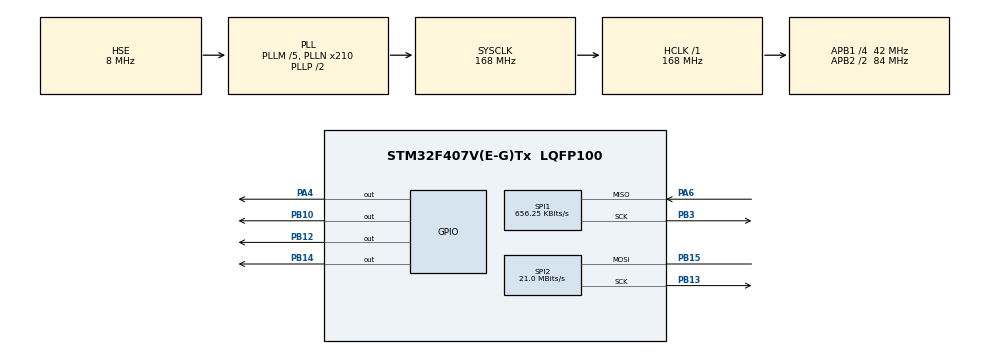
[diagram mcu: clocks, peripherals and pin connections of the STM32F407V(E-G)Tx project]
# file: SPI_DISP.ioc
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Mcu.Family=STM32F4
Mcu.Name=STM32F407V(E-G)Tx
Mcu.Package=LQFP100
NVIC.PriorityGroup=NVIC_PRIORITYGROUP_4
PA4.Signal=GPIO_Output
PA6.Mode=RX_Only_Simplex_Unidirect_Master
PA6.Signal=SPI1_MISO
PB10.Signal=GPIO_Output
PB12.Signal=GPIO_Output
PB13.Mode=Simplex_Bidirectional_Master
PB13.Signal=SPI2_SCK
PB14.Signal=GPIO_Output
PB15.Mode=Simplex_Bidirectional_Master
PB15.Signal=SPI2_MOSI
PB3.Mode=RX_Only_Simplex_Unidirect_Master
PB3.Signal=SPI1_SCK
PH0-OSC_IN.Mode=HSE-External-Oscillator
PH0-OSC_IN.Signal=RCC_OSC_IN
PH1-OSC_OUT.Mode=HSE-External-Oscillator
PH1-OSC_OUT.Signal=RCC_OSC_OUT
ProjectManager.TargetToolchain=MDK-ARM V5
RCC.48MHZClocksFreq_Value=84000000
RCC.AHBFreq_Value=168000000
RCC.APB1CLKDivider=RCC_HCLK_DIV4
RCC.APB1Freq_Value=42000000
RCC.APB1TimFreq_Value=84000000
RCC.APB2CLKDivider=RCC_HCLK_DIV2
RCC.APB2Freq_Value=84000000
RCC.APB2TimFreq_Value=168000000
RCC.CortexFreq_Value=168000000
RCC.HCLKFreq_Value=168000000
RCC.HSE_VALUE=8000000
RCC.HSI_VALUE=16000000
RCC.LSE_VALUE=32768
RCC.PLLM=5
RCC.PLLN=210
RCC.PLLSourceVirtual=RCC_PLLSOURCE_HSE
RCC.SYSCLKFreq_VALUE=168000000
RCC.SYSCLKSource=RCC_SYSCLKSOURCE_PLLCLK
RCC.VCOOutputFreq_Value=336000000
SPI1.BaudRatePrescaler=SPI_BAUDRATEPRESCALER_128
SPI1.CLKPhase=SPI_PHASE_2EDGE
SPI1.CalculateBaudRate=656.25 KBits/s
SPI1.DataSize=SPI_DATASIZE_16BIT
SPI1.Direction=SPI_DIRECTION_2LINES_RXONLY
SPI1.Mode=SPI_MODE_MASTER
SPI2.CalculateBaudRate=21.0 MBits/s
SPI2.Direction=SPI_DIRECTION_1LINE
SPI2.Mode=SPI_MODE_MASTER
board=custom

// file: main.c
/**
  ******************************************************************************
  * File Name          : main.c
  * Description        : Main program body
  ******************************************************************************
  *
  * COPYRIGHT(c) 2016 STMicroelectronics
  *
  * Redistribution and use in source and binary forms, with or without modification,
  * are permitted provided that the following conditions are met:
  *   1. Redistributions of source code must retain the above copyright notice,
  *      this list of conditions and the following disclaimer.
  *   2. Redistributions in binary form must reproduce the above copyright notice,
  *      this list of conditions and the following disclaimer in the documentation
  *      and/or other materials provided with the distribution.
  *   3. Neither the name of STMicroelectronics nor the names of its contributors
  *      may be used to endorse or promote products derived from this software
  *      without specific prior written permission.
  *
  * THIS SOFTWARE IS PROVIDED BY THE COPYRIGHT HOLDERS AND CONTRIBUTORS "AS IS"
  * AND ANY EXPRESS OR IMPLIED WARRANTIES, INCLUDING, BUT NOT LIMITED TO, THE
  * IMPLIED WARRANTIES OF MERCHANTABILITY AND FITNESS FOR A PARTICULAR PURPOSE ARE
  * DISCLAIMED. IN NO EVENT SHALL THE COPYRIGHT HOLDER OR CONTRIBUTORS BE LIABLE
  * FOR ANY DIRECT, INDIRECT, INCIDENTAL, SPECIAL, EXEMPLARY, OR CONSEQUENTIAL
  * DAMAGES (INCLUDING, BUT NOT LIMITED TO, PROCUREMENT OF SUBSTITUTE GOODS OR
  * SERVICES; LOSS OF USE, DATA, OR PROFITS; OR BUSINESS INTERRUPTION) HOWEVER
  * CAUSED AND ON ANY THEORY OF LIABILITY, WHETHER IN CONTRACT, STRICT LIABILITY,
  * OR TORT (INCLUDING NEGLIGENCE OR OTHERWISE) ARISING IN ANY WAY OUT OF THE USE
  * OF THIS SOFTWARE, EVEN IF ADVISED OF THE POSSIBILITY OF SUCH DAMAGE.
  *
  ******************************************************************************
  */

int  pixel=0;

#include "stm32f4xx_hal.h"

/* USER CODE BEGIN Includes */
//===============================================================================//
//----------------------AUTHOR: ИЛЬКОВЕЦ БОРИС / ILKAVETS BARYS-----------------//
// This is Open source software. You can place this code on site, but don't
// forget a link to my YouTube-channel: http://www.youtube.com/c/ElectroHobby1
// Это программное обеспечение распространяется свободно. Вы можете размещать
// его на сайте, но не забудьте указать ссылку на мой YouTube-канал
// "ElectroHobby" http://www.youtube.com/c/ElectroHobby1
//===============================================================================//
#include "main.h"
#include "func.h"
/* USER CODE END Includes */

SPI_HandleTypeDef hspi1;
SPI_HandleTypeDef hspi2;
DMA_HandleTypeDef hdma_spi2_tx;
DMA_HandleTypeDef hdma_spi2_rx;

/* USER CODE BEGIN PV */
#define MAX6675_CS1   HAL_GPIO_WritePin(GPIOA, GPIO_PIN_4,GPIO_PIN_SET);
#define MAX6675_CS0   HAL_GPIO_WritePin(GPIOA, GPIO_PIN_4,GPIO_PIN_RESET);

void Error_Handler(void)
{
  /* USER CODE BEGIN Error_Handler_Debug */
  /* User can add his own implementation to report the HAL error return state */
  __disable_irq();
  while (1)
  {
  }
  /* USER CODE END Error_Handler_Debug */
}

void int2char(int num, unsigned char str[])
{
char lstr[30];
int cnt = 0;
int div = 10;
int j = 0;

while( num >= div)
{
	lstr[cnt] = num % div + 0x30;
	num /= 10;
	cnt++;
}
	lstr[cnt] = num + 0x30;
for(j= cnt ; j >=0;j--)
{
	str[cnt-j] = lstr[j];
}

}

const int test_img_128x128[] = {

0xffff, 0xffff, 0xffff, 0xffff, 0xffff, 0xffff, 0xffff, 0xffff, 0xffff, 0xffff, 0xffff, 0xffff, 0xffff, 0xffff, 0xffff, 0xffff,
	0xffff, 0xffff, 0xffff, 0xffff, 0xffff, 0xffff, 0xffff, 0xffff, 0xffff, 0xffff, 0xffff, 0xffff, 0xffff, 0xffff, 0xffff, 0xffff,
	0xffff, 0xffff, 0xffff, 0xffff, 0xffff, 0xffff, 0xffff, 0xffff, 0xffff, 0xffff, 0xffff, 0xffff, 0xffff, 0xffff, 0xffff, 0xffff,
	0xffff, 0xffff, 0xffff, 0xffff, 0xffff, 0xffff, 0xffff, 0xffff, 0xffff, 0xffff, 0xffff, 0xffff, 0xffff, 0xffff, 0xffff, 0xffff,
	0xffff, 0xffff, 0xffff, 0xffff, 0xffff, 0xffff, 0x4a8a, 0x10c3, 0x10c3, 0x10c3, 0x10c3, 0x10c3, 0x10c3, 0x10c3, 0x10c3, 0x10c3,
	0x10c3, 0x10c3, 0x10c3, 0x10c3, 0x10c3, 0x10c3, 0x10c3, 0x10c3, 0x10c3, 0x1924, 0xffff, 0xffff, 0xffff, 0xffff, 0xffff, 0xffff,
	0xffff, 0xffff, 0xffff, 0xffff, 0xffff, 0xffff, 0xffff, 0xffff, 0xffff, 0xffff, 0xffff, 0xffff, 0xffff, 0xffff, 0xffff, 0xffff,
	0xffff, 0xffff, 0xffff, 0xffff, 0xffff, 0xffff, 0xffff, 0xffff, 0xffff, 0xffff, 0xffff, 0xffff, 0xffff, 0xffff, 0xffff, 0xffff,
	0xffff, 0xffff, 0xffff, 0xffff, 0xffff, 0xffff, 0xffff, 0xffff, 0xffff, 0xffff, 0xffff, 0xffff, 0xffff, 0xffff, 0xffff, 0xffff,
	0xffff, 0xffff, 0xffff, 0xffff, 0xffff, 0xffff, 0xffff, 0xffff, 0xffff, 0xffff, 0xffff, 0xffff, 0xffff, 0xffff, 0xffff, 0xffff,
	0xffff, 0xffff, 0xffff, 0xffff, 0xffff, 0xffff, 0xffff, 0xffff, 0xffff, 0xffff, 0xffff, 0xffff, 0xffff, 0xffff, 0xffff, 0xffff,
	0xffff, 0xffff, 0xffff, 0xffff, 0xffff, 0xffff, 0xffff, 0xffff, 0xffff, 0xffff, 0xffff, 0xffff, 0xffff, 0xffff, 0xffff, 0xffff,
	0xffff, 0xffff, 0xffff, 0xffff, 0xffff, 0xffff, 0xffff, 0xffff, 0xffff, 0xffff, 0xffff, 0xffff, 0xffff, 0xffff, 0xffff, 0xffff,
	0xffff, 0xffff, 0xffff, 0xffff, 0xffff, 0xffff, 0xffff, 0xffff, 0xffff, 0xffff, 0xffff, 0xffff, 0xffff, 0xffff, 0xffff, 0x10c3,
	0x10a2, 0x10a2, 0x10c3, 0x10c3, 0x10c3, 0x10c3, 0x10c3, 0x10c3, 0x10c3, 0x10c3, 0x10c3, 0x10c3, 0x10c3, 0x10c3, 0x10c3, 0x10c3,
	0x10c3, 0x10c3, 0x10c3, 0x10c3, 0x10c3, 0x10c3, 0x10c3, 0x10c3, 0x10c3, 0x10c3, 0x10c3, 0x10c3, 0x10c3, 0x10c3, 0x10a2, 0x10a2,
	0x10a3, 0xffff, 0xffff, 0xffff, 0xffff, 0xffff, 0xffff, 0xffff, 0xffff, 0xffff, 0xffff, 0xffff, 0xffff, 0xffff, 0xffff, 0xffff,
	0xffff, 0xffff, 0xffff, 0xffff, 0xffff, 0xffff, 0xffff, 0xffff, 0xffff, 0xffff, 0xffff, 0xffff, 0xffff, 0xffff, 0xffff, 0xffff,
	0xffff, 0xffff, 0xffff, 0xffff, 0xffff, 0xffff, 0xffff, 0xffff, 0xffff, 0xffff, 0xffff, 0xffff, 0xffff, 0xffff, 0xffff, 0xffff,
	0xffff, 0xffff, 0xffff, 0xffff, 0xffff, 0xffff, 0xffff, 0xffff, 0xffff, 0xffff, 0xffff, 0xffff, 0xffff, 0xffff, 0xffff, 0xffff,
	0xffff, 0xffff, 0xffff, 0xffff, 0xffff, 0xffff, 0xffff, 0xffff, 0xffff, 0xffff, 0xffff, 0xffff, 0xffff, 0xffff, 0xffff, 0xffff,
	0xffff, 0xffff, 0xffff, 0xffff, 0xffff, 0xffff, 0xffff, 0xffff, 0xffff, 0xffff, 0xffff, 0xffff, 0xffff, 0xffff, 0xffff, 0xffff,
	0xffff, 0xffff, 0xffff, 0xffff, 0xffff, 0xffff, 0xffff, 0xffff, 0xffff, 0xffff, 0xffff, 0xffff, 0xffff, 0xffff, 0xffff, 0xffff,
	0xffff, 0xffff, 0xffff, 0xffff, 0xffff, 0xffff, 0xffff, 0xffff, 0xffff, 0xffff, 0x10c3, 0x10c3, 0x10c3, 0x10c3, 0x10c3, 0x10c3,
	0x10c3, 0x10c3, 0x10c3, 0x10c3, 0x10c3, 0x10a3, 0x10a3, 0x10a2, 0x94d3, 0xffff, 0xffff, 0xffff, 0xffff, 0xffff, 0xffff, 0xffff,
	0xffff, 0xffff, 0xffff, 0xffff, 0xffff, 0xffff, 0xffff, 0xc638, 0x10c3, 0x10a3, 0x10c3, 0x10a3, 0x10c3, 0x10c3, 0x10c3, 0x10c3,
	0x10c3, 0x10c3, 0x10c3, 0x10c3, 0x10c3, 0x10c3, 0xffff, 0xffff, 0xffff, 0xffff, 0xffff, 0xffff, 0xffff, 0xffff, 0xffff, 0xffff,
	0xffff, 0xffff, 0xffff, 0xffff, 0xffff, 0xffff, 0xffff, 0xffff, 0xffff, 0xffff, 0xffff, 0xffff, 0xffff, 0xffff, 0xffff, 0xffff,
	0xffff, 0xffff, 0xffff, 0xffff, 0xffff, 0xffff, 0xffff, 0xffff, 0xffff, 0xffff, 0xffff, 0xffff, 0xffff, 0xffff, 0xffff, 0xffff,
	0xffff, 0xffff, 0xffff, 0xffff, 0xffff, 0xffff, 0xffff, 0xffff, 0xffff, 0xffff, 0xffff, 0xffff, 0xffff, 0xffff, 0xffff, 0xffff,
	0xffff, 0xffff, 0xffff, 0xffff, 0xffff, 0xffff, 0xffff, 0xffff, 0xffff, 0xffff, 0xffff, 0xffff, 0xffff, 0xffff, 0xffff, 0xffff,
	0xffff, 0xffff, 0xffff, 0xffff, 0xffff, 0xffff, 0xffff, 0xffff, 0xffff, 0xffff, 0xffff, 0xffff, 0xffff, 0xffff, 0xffff, 0xffff,
	0xffff, 0xffff, 0xffff, 0xffff, 0xffff, 0xffff, 0xffff, 0xffff, 0xffff, 0xffff, 0xffff, 0xffff, 0xffff, 0xffff, 0xffff, 0xffff,
	0xffff, 0xffff, 0xffff, 0xffff, 0xffff, 0xffff, 0x10a3, 0x10a2, 0x10c3, 0x10c3, 0x10c3, 0x10c3, 0x10c3, 0x10c3, 0x10c3, 0x10a2,
	0xffff, 0xffff, 0xffff, 0xffff, 0xffff, 0xffff, 0xffff, 0xffff, 0xffff, 0xffff, 0xffff, 0xffff, 0xffff, 0xffff, 0xffff, 0xffff,
	0xffff, 0xffff, 0xffff, 0xffff, 0xffff, 0xffff, 0xffff, 0xffff, 0xffff, 0xffff, 0xffff, 0xffff, 0xffff, 0xffff, 0xffff, 0xffff,
	0x10c3, 0x10c3, 0x10c3, 0x10c3, 0x10c3, 0x10c3, 0x10c3, 0x10c3, 0x10a3, 0x10a3, 0xffff, 0xffff, 0xffff, 0xffff, 0xffff, 0xffff,
	0xffff, 0xffff, 0xffff, 0xffff, 0xffff, 0xffff, 0xffff, 0xffff, 0xffff, 0xffff, 0xffff, 0xffff, 0xffff, 0xffff, 0xffff, 0xffff,
	0xffff, 0xffff, 0xffff, 0xffff, 0xffff, 0xffff, 0xffff, 0xffff, 0xffff, 0xffff, 0xffff, 0xffff, 0xffff, 0xffff, 0xffff, 0xffff,
	0xffff, 0xffff, 0xffff, 0xffff, 0xffff, 0xffff, 0xffff, 0xffff, 0xffff, 0xffff, 0xffff, 0xffff, 0xffff, 0xffff, 0xffff, 0xffff,
	0xffff, 0xffff, 0xffff, 0xffff, 0xffff, 0xffff, 0xffff, 0xffff, 0xffff, 0xffff, 0xffff, 0xffff, 0xffff, 0xffff, 0xffff, 0xffff,
	0xffff, 0xffff, 0xffff, 0xffff, 0xffff, 0xffff, 0xffff, 0xffff, 0xffff, 0xffff, 0xffff, 0xffff, 0xffff, 0xffff, 0xffff, 0xffff,
	0xffff, 0xffff, 0xffff, 0xffff, 0xffff, 0xffff, 0xffff, 0xffff, 0xffff, 0xffff, 0xffff, 0xffff, 0xffff, 0xffff, 0xffff, 0xffff,
	0xffff, 0xffff, 0x6b6d, 0x10c3, 0x10c3, 0x10c3, 0x10c3, 0x10c3, 0x10c3, 0x10c3, 0x10a2, 0xffff, 0xffff, 0xffff, 0xffff, 0xffff,
	0xffff, 0xffff, 0xffff, 0xffff, 0xffff, 0xffff, 0xffff, 0xffff, 0xffff, 0xffff, 0xffff, 0xc73a, 0x45cf, 0x0d09, 0x0d0a, 0x0d0a,
	0x0d09, 0x0d0a, 0x0d0a, 0x4dcf, 0xc75a, 0xffff, 0xffff, 0xffff, 0xffff, 0xffff, 0xffff, 0xffff, 0xffff, 0xffff, 0xffff, 0xffff,
	0xffff, 0xffff, 0xffff, 0xffff, 0xffff, 0x10a3, 0x10c3, 0x10c3, 0x10c3, 0x10c3, 0x10c3, 0x10c3, 0x10a3, 0x2124, 0xffff, 0xffff,
	0xffff, 0xffff, 0xffff, 0xffff, 0xffff, 0xffff, 0xffff, 0xffff, 0xffff, 0xffff, 0xffff, 0xffff, 0xffff, 0xffff, 0xffff, 0xffff,
	0xffff, 0xffff, 0xffff, 0xffff, 0xffff, 0xffff, 0xffff, 0xffff, 0xffff, 0xffff, 0xffff, 0xffff, 0xffff, 0xffff, 0xffff, 0xffff,
	0xffff, 0xffff, 0xffff, 0xffff, 0xffff, 0xffff, 0xffff, 0xffff, 0xffff, 0xffff, 0xffff, 0xffff, 0xffff, 0xffff, 0xffff, 0xffff,
	0xffff, 0xffff, 0xffff, 0xffff, 0xffff, 0xffff, 0xffff, 0xffff, 0xffff, 0xffff, 0xffff, 0xffff, 0xffff, 0xffff, 0xffff, 0xffff,
	0xffff, 0xffff, 0xffff, 0xffff, 0xffff, 0xffff, 0xffff, 0xffff, 0xffff, 0xffff, 0xffff, 0xffff, 0xffff, 0xffff, 0xffff, 0xffff,
	0xffff, 0xffff, 0xffff, 0xffff, 0xffff, 0xffff, 0xffff, 0xffff, 0xffff, 0xffff, 0xffff, 0xffff, 0xffff, 0xffff, 0xffff, 0x6b6d,
	0x10c3, 0x10c3, 0x10c3, 0x10c3, 0x10c3, 0x10c3, 0x10a3, 0xffff, 0xffff, 0xffff, 0xffff, 0xffff, 0xffff, 0xffff, 0xffff, 0xffff,
	0xffff, 0xf7de, 0x0d0a, 0x0d0a, 0x0d0a, 0x0d0a, 0x0d0a, 0x0d0a, 0x0d0a, 0x0d0a, 0x0d0a, 0x0d0a, 0x0d0a, 0x0d0a, 0x0d0a, 0x0d0a,
	0x0d0a, 0x0d0a, 0x0d0a, 0x0d0a, 0x0d0a, 0x0d0a, 0x0d0a, 0x0d0a, 0x0d0a, 0x0d0a, 0x0d0a, 0x0d0a, 0x0d0a, 0x0d0a, 0xc75a, 0xffff,
	0xffff, 0xffff, 0xffff, 0xffff, 0xffff, 0xffff, 0xffff, 0xffff, 0xffff, 0x10a3, 0x10a2, 0x10c3, 0x10c3, 0x10c3, 0x10c3, 0x10c3,
	0x2124, 0xffff, 0xffff, 0xffff, 0xffff, 0xffff, 0xffff, 0xffff, 0xffff, 0xffff, 0xffff, 0xffff, 0xffff, 0xffff, 0xffff, 0xffff,
	0xffff, 0xffff, 0xffff, 0xffff, 0xffff, 0xffff, 0xffff, 0xffff, 0xffff, 0xffff, 0xffff, 0xffff, 0xffff, 0xffff, 0xffff, 0xffff,
	0xffff, 0xffff, 0xffff, 0xffff, 0xffff, 0xffff, 0xffff, 0xffff, 0xffff, 0xffff, 0xffff, 0xffff, 0xffff, 0xffff, 0xffff, 0xffff,
	0xffff, 0xffff, 0xffff, 0xffff, 0xffff, 0xffff, 0xffff, 0xffff, 0xffff, 0xffff, 0xffff, 0xffff, 0xffff, 0xffff, 0xffff, 0xffff,
	0xffff, 0xffff, 0xffff, 0xffff, 0xffff, 0xffff, 0xffff, 0xffff, 0xffff, 0xffff, 0xffff, 0xffff, 0xffff, 0xffff, 0xffff, 0xffff,
	0xffff, 0xffff, 0xffff, 0xffff, 0xffff, 0xffff, 0xffff, 0xffff, 0xffff, 0xffff, 0xffff, 0xffff, 0xffff, 0x10c3, 0x10c3, 0x10c3,
	0x10c3, 0x10c3, 0x10c3, 0x10a3, 0xffff, 0xffff, 0xffff, 0xffff, 0xffff, 0xffff, 0xffff, 0xffff, 0xffff, 0x050a, 0x050a, 0x0d0a,
	0x0d0a, 0x0d0a, 0x0d0a, 0x0d0a, 0x0d0a, 0x0d0a, 0x0d0a, 0x0d0a, 0x0d0a, 0x0d0a, 0x0d0a, 0x0d2a, 0x050a, 0x0d2a, 0x45cf, 0x45cf,
	0x45cf, 0x45cf, 0x050a, 0x0d0a, 0x0d2a, 0x0d09, 0x0d0a, 0x0d0a, 0x0d0a, 0x0d0a, 0x0d0a, 0x0d0a, 0x0d0a, 0x0d0a, 0x0d0a, 0x0d0a,
	0x0d0a, 0x0d09, 0x0d0a, 0xe7bd, 0xffff, 0xffff, 0xffff, 0xffff, 0xffff, 0xffff, 0xffff, 0xffff, 0x10a2, 0x10c3, 0x10c3, 0x10c3,
	0x10c3, 0x10c3, 0x10a3, 0xffff, 0xffff, 0xffff, 0xffff, 0xffff, 0xffff, 0xffff, 0xffff, 0xffff, 0xffff, 0xffff, 0xffff, 0xffff,
	0xffff, 0xffff, 0xffff, 0xffff, 0xffff, 0xffff, 0xffff, 0xffff, 0xffff, 0xffff, 0xffff, 0xffff, 0xffff, 0xffff, 0xffff, 0xffff,
	0xffff, 0xffff, 0xffff, 0xffff, 0xffff, 0xffff, 0xffff, 0xffff, 0xffff, 0xffff, 0xffff, 0xffff, 0xffff, 0xffff, 0xffff, 0xffff,
	0xffff, 0xffff, 0xffff, 0xffff, 0xffff, 0xffff, 0xffff, 0xffff, 0xffff, 0xffff, 0xffff, 0xffff, 0xffff, 0xffff, 0xffff, 0xffff,
	0xffff, 0xffff, 0xffff, 0xffff, 0xffff, 0xffff, 0xffff, 0xffff, 0xffff, 0xffff, 0xffff, 0xffff, 0xffff, 0xffff, 0xffff, 0xffff,
	0xffff, 0xffff, 0xffff, 0xffff, 0xffff, 0xffff, 0xffff, 0xffff, 0xffff, 0xffff, 0xc638, 0x10c3, 0x10c3, 0x10c3, 0x10c3, 0x10c3,
	0x10a3, 0xffff, 0xffff, 0xffff, 0xffff, 0xffff, 0xffff, 0xffff, 0x6631, 0x0d0a, 0x0d0a, 0x0d0a, 0x0d0a, 0x0d0a, 0x0d0a, 0x0509,
	0x0d09, 0x0d09, 0x4dcf, 0xffff, 0xffff, 0xffff, 0xffff, 0xffff, 0xffff, 0xffff, 0xffff, 0xffff, 0xffff, 0xffff, 0xffff, 0xffff,
	0xffff, 0xffff, 0xffff, 0xffff, 0xffff, 0xffff, 0xffff, 0xffff, 0xffff, 0xffff, 0xffff, 0xffff, 0xffff, 0x6632, 0x0d2a, 0x0d0a,
	0x0d0a, 0x0d0a, 0x0d0a, 0x0d0a, 0x0d0a, 0x0d0a, 0x0509, 0x256c, 0xffff, 0xffff, 0xffff, 0xffff, 0xffff, 0xffff, 0xffff, 0x10a3,
	0x10c3, 0x10c3, 0x10c3, 0x10c3, 0x10c3, 0x4a6a, 0xffff, 0xffff, 0xffff, 0xffff, 0xffff, 0xffff, 0xffff, 0xffff, 0xffff, 0xffff,
	0xffff, 0xffff, 0xffff, 0xffff, 0xffff, 0xffff, 0xffff, 0xffff, 0xffff, 0xffff, 0xffff, 0xffff, 0xffff, 0xffff, 0xffff, 0xffff,
	0xffff, 0xffff, 0xffff, 0xffff, 0xffff, 0xffff, 0xffff, 0xffff, 0xffff, 0xffff, 0xffff, 0xffff, 0xffff, 0xffff, 0xffff, 0xffff,
	0xffff, 0xffff, 0xffff, 0xffff, 0xffff, 0xffff, 0xffff, 0xffff, 0xffff, 0xffff, 0xffff, 0xffff, 0xffff, 0xffff, 0xffff, 0xffff,
	0xffff, 0xffff, 0xffff, 0xffff, 0xffff, 0xffff, 0xffff, 0xffff, 0xffff, 0xffff, 0xffff, 0xffff, 0xffff, 0xffff, 0xffff, 0xffff,
	0xffff, 0xffff, 0xffff, 0xffff, 0xffff, 0xffff, 0xffff, 0xffff, 0x10a3, 0x10c3, 0x10c3, 0x10c3, 0x10c3, 0x10c3, 0xffff, 0xffff,
	0xffff, 0xffff, 0xffff, 0xffff, 0xffff, 0x0d0a, 0x0d09, 0x0d0a, 0x0d0a, 0x0d0a, 0x0d0a, 0x0d0a, 0x0d0a, 0xffff, 0xffff, 0xffff,
	0xffff, 0xffff, 0xffff, 0xffff, 0xffff, 0xffff, 0xffff, 0xffff, 0xffff, 0xffff, 0xffff, 0xffff, 0xffff, 0xffff, 0xffff, 0xffff,
	0xffff, 0xffff, 0xffff, 0xffff, 0xffff, 0xffff, 0xffff, 0xffff, 0xffff, 0xffff, 0xffff, 0xffff, 0xffff, 0xffff, 0xffff, 0xffff,
	0xffff, 0xffff, 0xffff, 0x0d0a, 0x0d0a, 0x0d0a, 0x0d0a, 0x0d0a, 0x050a, 0x0509, 0x0d09, 0xffff, 0xffff, 0xffff, 0xffff, 0xffff,
	0xffff, 0xffff, 0x10a3, 0x10c3, 0x10c3, 0x10c3, 0x10a3, 0x10c3, 0xffff, 0xffff, 0xffff, 0xffff, 0xffff, 0xffff, 0xffff, 0xffff,
	0xffff, 0xffff, 0xffff, 0xffff, 0xffff, 0xffff, 0xffff, 0xffff, 0xffff, 0xffff, 0xffff, 0xffff, 0xffff, 0xffff, 0xffff, 0xffff,
	0xffff, 0xffff, 0xffff, 0xffff, 0xffff, 0xffff, 0xffff, 0xffff, 0xffff, 0xffff, 0xffff, 0xffff, 0xffff, 0xffff, 0xffff, 0xffff,
	0xffff, 0xffff, 0xffff, 0xffff, 0xffff, 0xffff, 0xffff, 0xffff, 0xffff, 0xffff, 0xffff, 0xffff, 0xffff, 0xffff, 0xffff, 0xffff,
	0xffff, 0xffff, 0xffff, 0xffff, 0xffff, 0xffff, 0xffff, 0xffff, 0xffff, 0xffff, 0xffff, 0xffff, 0xffff, 0xffff, 0xffff, 0xffff,
	0xffff, 0xffff, 0xffff, 0xffff, 0xffff, 0xffff, 0x10c3, 0x10c3, 0x10c3, 0x10c3, 0x10c3, 0x10a3, 0xffff, 0xffff, 0xffff, 0xffff,
	0xffff, 0xffff, 0x0d09, 0x0d0a, 0x0d0a, 0x0d0a, 0x0d0a, 0x0d0a, 0x0d2a, 0xffff, 0xffff, 0xffff, 0xffff, 0xffff, 0xffff, 0xffff,
	0xffff, 0xffff, 0xffff, 0xffff, 0xffff, 0xffff, 0xffff, 0xffff, 0xffff, 0xffff, 0xffff, 0xffff, 0xffff, 0xffff, 0xffff, 0xffff,
	0xffff, 0xffff, 0xffff, 0xffff, 0xffff, 0xffff, 0xffff, 0xffff, 0xffff, 0xffff, 0xffff, 0xffff, 0xffff, 0xffff, 0xffff, 0xffff,
	0xffff, 0xffff, 0xffff, 0xffff, 0xffff, 0xffff, 0xffff, 0x0d09, 0x0d0a, 0x0d0a, 0x0d0a, 0x0d0a, 0x0d0a, 0x0d2a, 0xffff, 0xffff,
	0xffff, 0xffff, 0xffff, 0xffff, 0x10a3, 0x10a3, 0x10c3, 0x10c3, 0x10c3, 0x10a2, 0xffff, 0xffff, 0xffff, 0xffff, 0xffff, 0xffff,
	0xffff, 0xffff, 0xffff, 0xffff, 0xffff, 0xffff, 0xffff, 0xffff, 0xffff, 0xffff, 0xffff, 0xffff, 0xffff, 0xffff, 0xffff, 0xffff,
	0xffff, 0xffff, 0xffff, 0xffff, 0xffff, 0xffff, 0xffff, 0xffff, 0xffff, 0xffff, 0xffff, 0xffff, 0xffff, 0xffff, 0xffff, 0xffff,
	0xffff, 0xffff, 0xffff, 0xffff, 0xffff, 0xffff, 0xffff, 0xffff, 0xffff, 0xffff, 0xffff, 0xffff, 0xffff, 0xffff, 0xffff, 0xffff,
	0xffff, 0xffff, 0xffff, 0xffff, 0xffff, 0xffff, 0xffff, 0xffff, 0xffff, 0xffff, 0xffff, 0xffff, 0xffff, 0xffff, 0xffff, 0xffff,
	0xffff, 0xffff, 0xffff, 0xffff, 0x10a2, 0x10c3, 0x10c3, 0x10c3, 0x10a3, 0xffff, 0xffff, 0xffff, 0xffff, 0xffff, 0xffff, 0x0d0a,
	0x0d0a, 0x0d0a, 0x0d0a, 0x0d0a, 0x0d2a, 0x45ef, 0xffff, 0xffff, 0xffff, 0xffff, 0xffff, 0xffff, 0xffff, 0xffff, 0xffff, 0xffff,
	0xffff, 0xffff, 0xffff, 0xffff, 0xffff, 0xffff, 0xffff, 0xffff, 0xffff, 0xffff, 0xffff, 0xffff, 0xffff, 0xffff, 0xffff, 0xffff,
	0xffff, 0xffff, 0xffff, 0xffff, 0xffff, 0xffff, 0xffff, 0xffff, 0xffff, 0xffff, 0xffff, 0xffff, 0xffff, 0xffff, 0xffff, 0xffff,
	0xffff, 0xffff, 0xffff, 0xffff, 0xffff, 0xffff, 0xffff, 0xffff, 0xffff, 0xffff, 0xa6f7, 0x0d09, 0x0d0a, 0x0d0a, 0x0d0a, 0x0d0a,
	0x052a, 0xffff, 0xffff, 0xffff, 0xffff, 0xffff, 0xffff, 0x10c3, 0x10c3, 0x10c3, 0x10c3, 0x10a2, 0xffff, 0xffff, 0xffff, 0xffff,
	0xffff, 0xffff, 0xffff, 0xffff, 0xffff, 0xffff, 0xffff, 0xffff, 0xffff, 0xffff, 0xffff, 0xffff, 0xffff, 0xffff, 0xffff, 0xffff,
	0xffff, 0xffff, 0xffff, 0xffff, 0xffff, 0xffff, 0xffff, 0xffff, 0xffff, 0xffff, 0xffff, 0xffff, 0xffff, 0xffff, 0xffff, 0xffff,
	0xffff, 0xffff, 0xffff, 0xffff, 0xffff, 0xffff, 0xffff, 0xffff, 0xffff, 0xffff, 0xffff, 0xffff, 0xffff, 0xffff, 0xffff, 0xffff,
	0xffff, 0xffff, 0xffff, 0xffff, 0xffff, 0xffff, 0xffff, 0xffff, 0xffff, 0xffff, 0xffff, 0xffff, 0xffff, 0xffff, 0xffff, 0xffff,
	0xffff, 0xffff, 0x10a3, 0x10c3, 0x10c3, 0x10c3, 0x10c3, 0xffff, 0xffff, 0xffff, 0xffff, 0xffff, 0xffff, 0x0d2a, 0x0d0a, 0x0d0a,
	0x0d0a, 0x0d0a, 0x256d, 0xffff, 0xffff, 0xffff, 0xffff, 0xffff, 0xffff, 0xffff, 0xffff, 0xffff, 0xffff, 0xffff, 0xffff, 0xffff,
	0xffff, 0xffff, 0xffff, 0xffff, 0xffff, 0xffff, 0xffff, 0xffff, 0xffff, 0xffff, 0xffff, 0xffff, 0xffff, 0xffff, 0xffff, 0xffff,
	0xffff, 0xffff, 0xffff, 0xffff, 0xffff, 0xffff, 0xffff, 0xffff, 0xffff, 0xffff, 0xffff, 0xffff, 0xffff, 0xffff, 0xffff, 0xffff,
	0xffff, 0xffff, 0xffff, 0xffff, 0xffff, 0xffff, 0xffff, 0xffff, 0xffff, 0xffff, 0xffff, 0xffff, 0xffff, 0x8694, 0x0d0a, 0x0d0a,
	0x0d0a, 0x0d0a, 0x0529, 0xffff, 0xffff, 0xffff, 0xffff, 0xffff, 0xffff, 0x10c3, 0x10c3, 0x10c3, 0x10c3, 0x10c3, 0xffff, 0xffff,
	0xffff, 0xffff, 0xffff, 0xffff, 0xffff, 0xffff, 0xffff, 0xffff, 0xffff, 0xffff, 0xffff, 0xffff, 0xffff, 0xffff, 0xffff, 0xffff,
	0xffff, 0xffff, 0xffff, 0xffff, 0xffff, 0xffff, 0xffff, 0xffff, 0xffff, 0xffff, 0xffff, 0xffff, 0xffff, 0xffff, 0xffff, 0xffff,
	0xffff, 0xffff, 0xffff, 0xffff, 0xffff, 0xffff, 0xffff, 0xffff, 0xffff, 0xffff, 0xffff, 0xffff, 0xffff, 0xffff, 0xffff, 0xffff,
	0xffff, 0xffff, 0xffff, 0xffff, 0xffff, 0xffff, 0xffff, 0xffff, 0xffff, 0xffff, 0xffff, 0xffff, 0xffff, 0xffff, 0xffff, 0xffff,
	0xffff, 0x10c3, 0x10c3, 0x10c3, 0x10c3, 0xffff, 0xffff, 0xffff, 0xffff, 0xffff, 0xf7de, 0x0d0a, 0x0d0a, 0x0d0a, 0x0509, 0x0d2a,
	0xffff, 0xffff, 0xffff, 0xffff, 0xffff, 0xffff, 0xffff, 0xffff, 0xffff, 0xffff, 0xffff, 0xffff, 0xffff, 0xffff, 0xffff, 0xffff,
	0xffff, 0xffff, 0xffff, 0xffff, 0xef9e, 0x10a3, 0x10a3, 0x94b3, 0xffff, 0xffff, 0x10a3, 0xffff, 0xffff, 0xffff, 0xffff, 0xffff,
	0xffff, 0x10a2, 0xffff, 0xffff, 0xffff, 0xffff, 0x10c3, 0x10c3, 0x10c3, 0x10c3, 0x10c3, 0xffff, 0xffff, 0xffff, 0xffff, 0xffff,
	0xffff, 0xffff, 0xffff, 0xffff, 0xffff, 0xffff, 0xffff, 0xffff, 0xffff, 0xffff, 0xffff, 0xffff, 0xffff, 0xffff, 0xffff, 0xffff,
	0x0d0a, 0x0d0a, 0x0d0a, 0x0d0a, 0x0d0a, 0x8694, 0xffff, 0xffff, 0xffff, 0xffff, 0xffff, 0x10c3, 0x10c3, 0x10c3, 0x10c3, 0xd6ba,
	0xffff, 0xffff, 0xffff, 0xffff, 0xffff, 0xffff, 0xffff, 0xffff, 0xffff, 0xffff, 0xffff, 0xffff, 0xffff, 0xffff, 0xffff, 0xffff,
	0xffff, 0xffff, 0xffff, 0xffff, 0xffff, 0xffff, 0xffff, 0xffff, 0xffff, 0xffff, 0xffff, 0xffff, 0xffff, 0xffff, 0xffff, 0xffff,
	0xffff, 0xffff, 0xffff, 0xffff, 0xffff, 0xffff, 0xffff, 0xffff, 0xffff, 0xffff, 0xffff, 0xffff, 0xffff, 0xffff, 0xffff, 0xffff,
	0xffff, 0xffff, 0xffff, 0xffff, 0xffff, 0xffff, 0xffff, 0xffff, 0xffff, 0xffff, 0xffff, 0xffff, 0xffff, 0xffff, 0xffff, 0x10c3,
	0x10c3, 0x10c3, 0x10a2, 0x2124, 0xffff, 0xffff, 0xffff, 0xffff, 0xc75a, 0x0d0a, 0x0d0a, 0x0d0a, 0x050a, 0x45cf, 0xffff, 0xffff,
	0xffff, 0xffff, 0xffff, 0xffff, 0xffff, 0xffff, 0xffff, 0xffff, 0xffff, 0xffff, 0xffff, 0xffff, 0xffff, 0xffff, 0xffff, 0xffff,
	0xffff, 0xffff, 0xffff, 0xffff, 0xffff, 0x2124, 0x10c3, 0xffff, 0xffff, 0xffff, 0xffff, 0xffff, 0x10c3, 0xffff, 0xffff, 0xffff,
	0xffff, 0xffff, 0x3a08, 0xffff, 0xffff, 0xffff, 0xffff, 0xf79e, 0xffff, 0xffff, 0xffff, 0xef9e, 0xffff, 0xffff, 0xffff, 0xffff,
	0xffff, 0xffff, 0xffff, 0xffff, 0xffff, 0xffff, 0xffff, 0xffff, 0xffff, 0xffff, 0xffff, 0xffff, 0xffff, 0xffff, 0xffff, 0xffff,
	0xffff, 0xffff, 0xb719, 0x0d2a, 0x0d0a, 0x0d0a, 0x0d0a, 0x45cf, 0xffff, 0xffff, 0xffff, 0xffff, 0x8c51, 0x10a3, 0x10c3, 0x10c3,
	0x10c3, 0xffff, 0xffff, 0xffff, 0xffff, 0xffff, 0xffff, 0xffff, 0xffff, 0xffff, 0xffff, 0xffff, 0xffff, 0xffff, 0xffff, 0xffff,
	0xffff, 0xffff, 0xffff, 0xffff, 0xffff, 0xffff, 0xffff, 0xffff, 0xffff, 0xffff, 0xffff, 0xffff, 0xffff, 0xffff, 0xffff, 0xffff,
	0xffff, 0xffff, 0xffff, 0xffff, 0xffff, 0xffff, 0xffff, 0xffff, 0xffff, 0xffff, 0xffff, 0xffff, 0xffff, 0xffff, 0xffff, 0xffff,
	0xffff, 0xffff, 0xffff, 0xffff, 0xffff, 0xffff, 0xffff, 0xffff, 0xffff, 0xffff, 0xffff, 0xffff, 0xffff, 0x10a2, 0x10c3, 0x10c3,
	0x10c3, 0x10a3, 0xffff, 0xffff, 0xffff, 0xffff, 0xffff, 0x0d0a, 0x0d0a, 0x0d0a, 0x0d0a, 0xffff, 0xffff, 0xffff, 0xffff, 0xffff,
	0xffff, 0xffff, 0xffff, 0xffff, 0xffff, 0xffff, 0xffff, 0xffff, 0xffff, 0xffff, 0xffff, 0xffff, 0xffff, 0xffff, 0xffff, 0xffff,
	0xffff, 0xffff, 0xffff, 0xffff, 0xffff, 0x4a6a, 0x10c3, 0xffff, 0xffff, 0xffff, 0xffff, 0xffff, 0xd69a, 0x10c3, 0xffff, 0xffff,
	0xffff, 0xffff, 0xffff, 0x10a3, 0xffff, 0xffff, 0xffff, 0xffff, 0x10a2, 0xffff, 0xffff, 0xffff, 0xffff, 0xffff, 0xffff, 0xffff,
	0xffff, 0xffff, 0xffff, 0xffff, 0xffff, 0xffff, 0xffff, 0xffff, 0xffff, 0xffff, 0xffff, 0xffff, 0xffff, 0xffff, 0xffff, 0xffff,
	0xffff, 0xffff, 0xffff, 0xffff, 0xffff, 0x0509, 0x0d0a, 0x0d0a, 0x0d0a, 0xd77b, 0xffff, 0xffff, 0xffff, 0xffff, 0x10a2, 0x10c3,
	0x10c3, 0x10c3, 0x10a2, 0xffff, 0xffff, 0xffff, 0xffff, 0xffff, 0xffff, 0xffff, 0xffff, 0xffff, 0xffff, 0xffff, 0xffff, 0xffff,
	0xffff, 0xffff, 0xffff, 0xffff, 0xffff, 0xffff, 0xffff, 0xffff, 0xffff, 0xffff, 0xffff, 0xffff, 0xffff, 0xffff, 0xffff, 0xffff,
	0xffff, 0xffff, 0xffff, 0xffff, 0xffff, 0xffff, 0xffff, 0xffff, 0xffff, 0xffff, 0xffff, 0xffff, 0xffff, 0xffff, 0xffff, 0xffff,
	0xffff, 0xffff, 0xffff, 0xffff, 0xffff, 0xffff, 0xffff, 0xffff, 0xffff, 0xffff, 0xffff, 0xffff, 0x10a2, 0x10c3, 0x10c3, 0x10c3,
	0xffff, 0xffff, 0xffff, 0xffff, 0xffff, 0x0d0a, 0x0d0a, 0x0d0a, 0x0d0a, 0xffff, 0xffff, 0xffff, 0xffff, 0xffff, 0xffff, 0xffff,
	0xffff, 0xffff, 0xffff, 0xffff, 0xffff, 0xffff, 0xffff, 0xffff, 0xffff, 0xffff, 0xffff, 0xffff, 0xffff, 0xffff, 0xffff, 0xffff,
	0xffff, 0xffff, 0xffff, 0xffff, 0xffff, 0x4a6a, 0x10c3, 0xffff, 0xffff, 0xffff, 0x10a3, 0xffff, 0x6b6d, 0x10a3, 0xffff, 0xffff,
	0x10a2, 0x10c3, 0xffff, 0x10a3, 0x10a2, 0xffff, 0xffff, 0xffff, 0xffff, 0x10a2, 0xffff, 0xffff, 0xffff, 0xffff, 0xffff, 0xffff,
	0xffff, 0xffff, 0xffff, 0xffff, 0xffff, 0xffff, 0xffff, 0xffff, 0xffff, 0xffff, 0xffff, 0xffff, 0xffff, 0xffff, 0xffff, 0xffff,
	0xffff, 0xffff, 0xffff, 0xffff, 0xffff, 0xffff, 0xffff, 0x050a, 0x0d0a, 0x0d0a, 0x0d0a, 0xffff, 0xffff, 0xffff, 0xffff, 0xffff,
	0x10a2, 0x10c3, 0x10c3, 0x10c3, 0xffff, 0xffff, 0xffff, 0xffff, 0xffff, 0xffff, 0xffff, 0xffff, 0xffff, 0xffff, 0xffff, 0xffff,
	0xffff, 0xffff, 0xffff, 0xffff, 0xffff, 0xffff, 0xffff, 0xffff, 0xffff, 0xffff, 0xffff, 0xffff, 0xffff, 0xffff, 0xffff, 0xffff,
	0xffff, 0xffff, 0xffff, 0xffff, 0xffff, 0xffff, 0xffff, 0xffff, 0xffff, 0xffff, 0xffff, 0xffff, 0xffff, 0xffff, 0xffff, 0xffff,
	0xffff, 0xffff, 0xffff, 0xffff, 0xffff, 0xffff, 0xffff, 0xffff, 0xffff, 0xffff, 0x4208, 0x10a3, 0x10c3, 0x10c3, 0x10a3, 0xffff,
	0xffff, 0xffff, 0xffff, 0x0d0a, 0x0d0a, 0x0d0a, 0x0d0a, 0xffff, 0xffff, 0xffff, 0xffff, 0xffff, 0xffff, 0xffff, 0xffff, 0xffff,
	0xffff, 0xffff, 0xffff, 0xffff, 0xffff, 0xffff, 0xffff, 0xffff, 0xffff, 0xffff, 0xffff, 0xffff, 0xffff, 0xffff, 0xffff, 0xffff,
	0xffff, 0xffff, 0xffff, 0xffff, 0xffff, 0x4a6a, 0x10c3, 0xffff, 0xffff, 0x10a2, 0xffff, 0xffff, 0xffff, 0x10c3, 0xffff, 0xffff,
	0x10a2, 0xffff, 0xffff, 0xffff, 0x10c3, 0xffff, 0xffff, 0xffff, 0xffff, 0xffff, 0x10a3, 0xffff, 0xffff, 0xffff, 0xffff, 0xffff,
	0xffff, 0xffff, 0xffff, 0xffff, 0xffff, 0xffff, 0xffff, 0xffff, 0xffff, 0xffff, 0xffff, 0xffff, 0xffff, 0xffff, 0xffff, 0xffff,
	0xffff, 0xffff, 0xffff, 0xffff, 0xffff, 0xffff, 0xffff, 0xffff, 0xffff, 0x0d0a, 0x0d0a, 0x0d0a, 0x0d0a, 0xffff, 0xffff, 0xffff,
	0xffff, 0x6b6d, 0x10c3, 0x10c3, 0x10a3, 0x10a3, 0xffff, 0xffff, 0xffff, 0xffff, 0xffff, 0xffff, 0xffff, 0xffff, 0xffff, 0xffff,
	0xffff, 0xffff, 0xffff, 0xffff, 0xffff, 0xffff, 0xffff, 0xffff, 0xffff, 0xffff, 0xffff, 0xffff, 0xffff, 0xffff, 0xffff, 0xffff,
	0xffff, 0xffff, 0xffff, 0xffff, 0xffff, 0xffff, 0xffff, 0xffff, 0xffff, 0xffff, 0xffff, 0xffff, 0xffff, 0xffff, 0xffff, 0xffff,
	0xffff, 0xffff, 0xffff, 0xffff, 0xffff, 0xffff, 0xffff, 0xffff, 0xffff, 0x10a3, 0x10c3, 0x10c3, 0x10c3, 0xffff, 0xffff, 0xffff,
	0xffff, 0x154b, 0x0d0a, 0x0d0a, 0x0d0a, 0x0d0a, 0xffff, 0xffff, 0xffff, 0xffff, 0xffff, 0xffff, 0xffff, 0xffff, 0xffff, 0xffff,
	0xffff, 0xffff, 0xffff, 0xffff, 0xffff, 0xffff, 0xffff, 0xffff, 0xffff, 0xffff, 0xffff, 0xffff, 0xffff, 0xffff, 0xffff, 0xffff,
	0xffff, 0xffff, 0xffff, 0xffff, 0xffff, 0x10a3, 0x10c3, 0xffff, 0xffff, 0x10a3, 0xffff, 0xffff, 0xffff, 0x10c3, 0xffff, 0xd69a,
	0x10a3, 0xffff, 0xffff, 0xffff, 0x10a2, 0xffff, 0xffff, 0xffff, 0xffff, 0xffff, 0x10a3, 0xffff, 0xffff, 0xffff, 0xffff, 0xffff,
	0xffff, 0xffff, 0xffff, 0xffff, 0xffff, 0xffff, 0xffff, 0xffff, 0xffff, 0xffff, 0xffff, 0xffff, 0xffff, 0xffff, 0xffff, 0xffff,
	0xffff, 0xffff, 0xffff, 0xffff, 0xffff, 0xffff, 0xffff, 0xffff, 0xffff, 0xffff, 0x154b, 0x0d0a, 0x0d0a, 0x050a, 0x050a, 0xffff,
	0xffff, 0xffff, 0xffff, 0x10a3, 0x10c3, 0x10c3, 0x10a3, 0xffff, 0xffff, 0xffff, 0xffff, 0xffff, 0xffff, 0xffff, 0xffff, 0xffff,
	0xffff, 0xffff, 0xffff, 0xffff, 0xffff, 0xffff, 0xffff, 0xffff, 0xffff, 0xffff, 0xffff, 0xffff, 0xffff, 0xffff, 0xffff, 0xffff,
	0xffff, 0xffff, 0xffff, 0xffff, 0xffff, 0xffff, 0xffff, 0xffff, 0xffff, 0xffff, 0xffff, 0xffff, 0xffff, 0xffff, 0xffff, 0xffff,
	0xffff, 0xffff, 0xffff, 0xffff, 0xffff, 0xffff, 0xffff, 0xffff, 0x10c3, 0x10c3, 0x10c3, 0x10c3, 0xffff, 0xffff, 0xffff, 0xffff,
	0x052a, 0x0d0a, 0x0d0a, 0x0d0a, 0xffff, 0xffff, 0xffff, 0xffff, 0xffff, 0xffff, 0xffff, 0xffff, 0xffff, 0xffff, 0xffff, 0xffff,
	0xffff, 0xffff, 0xffff, 0xffff, 0xffff, 0xffff, 0xffff, 0xffff, 0xffff, 0xffff, 0xffff, 0xffff, 0xffff, 0xffff, 0xffff, 0xffff,
	0xffff, 0xffff, 0xffff, 0xffff, 0xffff, 0x10a2, 0x10a2, 0xffff, 0xffff, 0x10a3, 0xffff, 0xffff, 0xffff, 0x10c3, 0xffff, 0xffff,
	0x10a2, 0xffff, 0xffff, 0x10a2, 0xffff, 0xffff, 0xffff, 0xffff, 0xffff, 0x4208, 0x10c3, 0xffff, 0xffff, 0xffff, 0xffff, 0xffff,
	0xffff, 0xffff, 0xffff, 0xffff, 0xffff, 0xffff, 0xffff, 0xffff, 0xffff, 0xffff, 0xffff, 0xffff, 0xffff, 0xffff, 0xffff, 0xffff,
	0xffff, 0xffff, 0xffff, 0xffff, 0xffff, 0xffff, 0xffff, 0xffff, 0xffff, 0xffff, 0xffff, 0xffff, 0x0d09, 0x0d0a, 0x0d0a, 0x0d0a,
	0xffff, 0xffff, 0xffff, 0xffff, 0x10a3, 0x10c3, 0x10c3, 0x10c3, 0xffff, 0xffff, 0xffff, 0xffff, 0xffff, 0xffff, 0xffff, 0xffff,
	0xffff, 0xffff, 0xffff, 0xffff, 0xffff, 0xffff, 0xffff, 0xffff, 0xffff, 0xffff, 0xffff, 0xffff, 0xffff, 0xffff, 0xffff, 0xffff,
	0xffff, 0xffff, 0xffff, 0xffff, 0xffff, 0xffff, 0xffff, 0xffff, 0xffff, 0xffff, 0xffff, 0xffff, 0xffff, 0xffff, 0xffff, 0xffff,
	0xffff, 0xffff, 0xffff, 0xffff, 0xffff, 0xffff, 0xffff, 0x10c3, 0x10c3, 0x10c3, 0x2124, 0xffff, 0xffff, 0xffff, 0xf7de, 0x0d0a,
	0x0d0a, 0x0d0a, 0x3d8e, 0xffff, 0xffff, 0xffff, 0xffff, 0xffff, 0xffff, 0xffff, 0xffff, 0xffff, 0xffff, 0xffff, 0xffff, 0xffff,
	0xffff, 0xffff, 0xffff, 0xffff, 0xffff, 0xffff, 0xffff, 0xffff, 0xffff, 0xffff, 0xffff, 0xffff, 0xffff, 0xffff, 0xffff, 0xffff,
	0xffff, 0xffff, 0xffff, 0xffff, 0xffff, 0xffff, 0xffff, 0xffff, 0xffff, 0xffff, 0xffff, 0xc638, 0xffff, 0xffff, 0xffff, 0xffff,
	0xffff, 0xffff, 0xc638, 0xffff, 0xffff, 0xffff, 0xffff, 0xffff, 0xffff, 0xffff, 0xffff, 0xffff, 0xffff, 0xffff, 0xffff, 0xffff,
	0xffff, 0xffff, 0xffff, 0xffff, 0xffff, 0xffff, 0xffff, 0xffff, 0xffff, 0xffff, 0xffff, 0xffff, 0xffff, 0xffff, 0xffff, 0xffff,
	0xffff, 0xffff, 0xffff, 0xffff, 0xffff, 0xffff, 0xffff, 0xffff, 0xffff, 0xffff, 0xffff, 0xffff, 0xffff, 0xd77b, 0x0d0a, 0x0d0a,
	0x0d0a, 0x6632, 0xffff, 0xffff, 0xffff, 0xd69a, 0x10c3, 0x10c3, 0x10c3, 0xd69a, 0xffff, 0xffff, 0xffff, 0xffff, 0xffff, 0xffff,
	0xffff, 0xffff, 0xffff, 0xffff, 0xffff, 0xffff, 0xffff, 0xffff, 0xffff, 0xffff, 0xffff, 0xffff, 0xffff, 0xffff, 0xffff, 0xffff,
	0xffff, 0xffff, 0xffff, 0xffff, 0xffff, 0xffff, 0xffff, 0xffff, 0xffff, 0xffff, 0xffff, 0xffff, 0xffff, 0xffff, 0xffff, 0xffff,
	0xffff, 0xffff, 0xffff, 0xffff, 0xffff, 0x10a2, 0x10c3, 0x10c3, 0x10c3, 0xffff, 0xffff, 0xffff, 0xffff, 0x052a, 0x0d0a, 0x0d0a,
	0x0d0a, 0xffff, 0xffff, 0xffff, 0xffff, 0xffff, 0xffff, 0xffff, 0xffff, 0xffff, 0xffff, 0xffff, 0xffff, 0xffff, 0xffff, 0xffff,
	0xffff, 0xffff, 0xffff, 0xffff, 0xffff, 0xffff, 0xffff, 0xffff, 0xffff, 0xffff, 0xffff, 0xffff, 0xffff, 0xffff, 0xffff, 0xffff,
	0xffff, 0xffff, 0xffff, 0xffff, 0xffff, 0xffff, 0xffff, 0xffff, 0xffff, 0xffff, 0xffff, 0xffff, 0xffff, 0xffff, 0xffff, 0xffff,
	0xffff, 0xffff, 0xffff, 0xffff, 0xffff, 0xffff, 0xffff, 0xffff, 0xffff, 0xffff, 0xffff, 0xffff, 0xffff, 0xffff, 0xffff, 0xffff,
	0xffff, 0xffff, 0xffff, 0xffff, 0xffff, 0xffff, 0xffff, 0xffff, 0xffff, 0xffff, 0xffff, 0xffff, 0xffff, 0xffff, 0xffff, 0xffff,
	0xffff, 0xffff, 0xffff, 0xffff, 0xffff, 0xffff, 0xffff, 0xffff, 0xffff, 0xffff, 0xffff, 0xffff, 0xffff, 0xffff, 0xffff, 0x0d0a,
	0x0d0a, 0x0d0a, 0x0d0a, 0xffff, 0xffff, 0xffff, 0xffff, 0x10c3, 0x10c3, 0x10c3, 0x10c3, 0xffff, 0xffff, 0xffff, 0xffff, 0xffff,
	0xffff, 0xffff, 0xffff, 0xffff, 0xffff, 0xffff, 0xffff, 0xffff, 0xffff, 0xffff, 0xffff, 0xffff, 0xffff, 0xffff, 0xffff, 0xffff,
	0xffff, 0xffff, 0xffff, 0xffff, 0xffff, 0xffff, 0xffff, 0xffff, 0xffff, 0xffff, 0xffff, 0xffff, 0xffff, 0xffff, 0xffff, 0xffff,
	0xffff, 0xffff, 0xffff, 0xffff, 0x10a3, 0x10c3, 0x10c3, 0x10c3, 0xffff, 0xffff, 0xffff, 0xffff, 0x0d2a, 0x0d0a, 0x0d0a, 0x0d29,
	0xffff, 0xffff, 0xffff, 0xffff, 0xffff, 0xffff, 0xffff, 0xffff, 0xffff, 0xffff, 0xffff, 0xffff, 0xffff, 0xffff, 0xffff, 0xffff,
	0xffff, 0xffff, 0xffff, 0xffff, 0xffff, 0xffff, 0xffff, 0xffff, 0xffff, 0xffff, 0xffff, 0xffff, 0xffff, 0xffff, 0xffff, 0xffff,
	0xffff, 0xffff, 0xffff, 0xffff, 0xffff, 0xffff, 0xffff, 0xffff, 0xffff, 0xffff, 0xffff, 0xffff, 0xffff, 0xffff, 0xffff, 0xffff,
	0xffff, 0xffff, 0xffff, 0xffff, 0xffff, 0xffff, 0xffff, 0xffff, 0xffff, 0xffff, 0xffff, 0xffff, 0xffff, 0xffff, 0xffff, 0xffff,
	0xffff, 0xffff, 0xffff, 0xffff, 0xffff, 0xffff, 0xffff, 0xffff, 0xffff, 0xffff, 0xffff, 0xffff, 0xffff, 0xffff, 0xffff, 0xffff,
	0xffff, 0xffff, 0xffff, 0xffff, 0xffff, 0xffff, 0xffff, 0xffff, 0xffff, 0xffff, 0xffff, 0xffff, 0xffff, 0xffff, 0xffff, 0xffff,
	0x35ad, 0x0d0a, 0x0d0a, 0x0d0a, 0xffff, 0xffff, 0xffff, 0xffff, 0x10c3, 0x10c3, 0x10c3, 0x10a2, 0xffff, 0xffff, 0xffff, 0xffff,
	0xffff, 0xffff, 0xffff, 0xffff, 0xffff, 0xffff, 0xffff, 0xffff, 0xffff, 0xffff, 0xffff, 0xffff, 0xffff, 0xffff, 0xffff, 0xffff,
	0xffff, 0xffff, 0xffff, 0xffff, 0xffff, 0xffff, 0xffff, 0xffff, 0xffff, 0xffff, 0xffff, 0xffff, 0xffff, 0xffff, 0xffff, 0xffff,
	0xffff, 0xffff, 0xffff, 0x10c3, 0x10c3, 0x10c3, 0x10c3, 0xffff, 0xffff, 0xffff, 0xffff, 0x0d0a, 0x0d0a, 0x0d09, 0xffff, 0xffff,
	0xffff, 0xffff, 0xffff, 0xffff, 0xffff, 0xffff, 0xffff, 0xffff, 0xffff, 0xffff, 0xffff, 0xffff, 0xffff, 0xffff, 0xffff, 0xffff,
	0xffff, 0xffff, 0xffff, 0xffff, 0xffff, 0xffff, 0xffff, 0xffff, 0xffff, 0xffff, 0xffff, 0xffff, 0xffff, 0xffff, 0xffff, 0xffff,
	0xffff, 0xffff, 0xffff, 0xffff, 0xffff, 0xffff, 0xffff, 0xffff, 0xffff, 0xffff, 0xffff, 0xffff, 0xffff, 0xffff, 0xffff, 0xffff,
	0xffff, 0xffff, 0xffff, 0xffff, 0xffff, 0xffff, 0xffff, 0xffff, 0xffff, 0xffff, 0xffff, 0xffff, 0xffff, 0xffff, 0xffff, 0xffff,
	0xffff, 0xffff, 0xffff, 0xffff, 0xffff, 0xffff, 0xffff, 0xffff, 0xffff, 0xffff, 0xffff, 0xffff, 0xffff, 0xffff, 0xffff, 0xffff,
	0xffff, 0xffff, 0xffff, 0xffff, 0xffff, 0xffff, 0xffff, 0xffff, 0xffff, 0xffff, 0xffff, 0xffff, 0xffff, 0xffff, 0xffff, 0xffff,
	0xffff, 0xffff, 0x0d0a, 0x0d0a, 0x0509, 0xffff, 0xffff, 0xffff, 0xffff, 0x10a2, 0x10c3, 0x10c3, 0x10a3, 0xffff, 0xffff, 0xffff,
	0xffff, 0xffff, 0xffff, 0xffff, 0xffff, 0xffff, 0xffff, 0xffff, 0xffff, 0xffff, 0xffff, 0xffff, 0xffff, 0xffff, 0xffff, 0xffff,
	0xffff, 0xffff, 0xffff, 0xffff, 0xffff, 0xffff, 0xffff, 0xffff, 0xffff, 0xffff, 0xffff, 0xffff, 0xffff, 0xffff, 0xffff, 0xffff,
	0xffff, 0xffff, 0x10c3, 0x10c3, 0x10c3, 0x10a3, 0xffff, 0xffff, 0xffff, 0x154b, 0x0d0a, 0x0d0a, 0x0d2a, 0xffff, 0xffff, 0xffff,
	0xffff, 0xffff, 0xffff, 0xffff, 0xffff, 0xffff, 0xffff, 0xffff, 0xffff, 0xffff, 0xffff, 0xffff, 0xffff, 0xffff, 0xffff, 0xffff,
	0xffff, 0xffff, 0xffff, 0xffff, 0xffff, 0xffff, 0xffff, 0xffff, 0xffff, 0xffff, 0xffff, 0xffff, 0xffff, 0xffff, 0xffff, 0xffff,
	0xffff, 0xffff, 0xffff, 0xffff, 0xffff, 0xffff, 0xffff, 0xffff, 0xffff, 0xffff, 0xffff, 0xffff, 0xffff, 0xffff, 0xffff, 0xffff,
	0xffff, 0xffff, 0xffff, 0xffff, 0xffff, 0xffff, 0xffff, 0xffff, 0xffff, 0xffff, 0xffff, 0xffff, 0xffff, 0xffff, 0xffff, 0xffff,
	0xffff, 0xffff, 0xffff, 0xffff, 0xffff, 0xffff, 0xffff, 0xffff, 0xffff, 0xffff, 0xffff, 0xffff, 0xffff, 0xffff, 0xffff, 0xffff,
	0xffff, 0xffff, 0xffff, 0xffff, 0xffff, 0xffff, 0xffff, 0xffff, 0xffff, 0xffff, 0xffff, 0xffff, 0xffff, 0xffff, 0xffff, 0xffff,
	0xffff, 0xffff, 0xffff, 0x0d09, 0x0d0a, 0x0d0a, 0x0d09, 0xffff, 0xffff, 0xffff, 0x10a3, 0x10c3, 0x10c3, 0x10c3, 0xffff, 0xffff,
	0xffff, 0xffff, 0xffff, 0xffff, 0xffff, 0xffff, 0xffff, 0xffff, 0xffff, 0xffff, 0xffff, 0xffff, 0xffff, 0xffff, 0xffff, 0xffff,
	0xffff, 0xffff, 0xffff, 0xffff, 0xffff, 0xffff, 0xffff, 0xffff, 0xffff, 0xffff, 0xffff, 0xffff, 0xffff, 0xffff, 0xffff, 0xffff,
	0xffff, 0x10a2, 0x10c3, 0x10c3, 0x10c3, 0xffff, 0xffff, 0xffff, 0x0d0a, 0x0d2a, 0x0d0a, 0x0d0a, 0xffff, 0xffff, 0xffff, 0xffff,
	0xffff, 0xffff, 0xffff, 0xffff, 0xffff, 0xffff, 0xffff, 0xffff, 0xffff, 0xffff, 0xffff, 0xffff, 0xffff, 0xffff, 0xffff, 0xffff,
	0xffff, 0xffff, 0xffff, 0xffff, 0xffff, 0xffff, 0xffff, 0xffff, 0xffff, 0xffff, 0xffff, 0xffff, 0xffff, 0xffff, 0xffff, 0xffff,
	0xffff, 0xffff, 0xffff, 0xffff, 0xffff, 0xffff, 0xffff, 0xffff, 0xffff, 0xffff, 0xffff, 0xffff, 0xffff, 0xffff, 0xffff, 0xffff,
	0xffff, 0xffff, 0xffff, 0xffff, 0xffff, 0xffff, 0xffff, 0xffff, 0xffff, 0xffff, 0xffff, 0xffff, 0xffff, 0xffff, 0xffff, 0xffff,
	0xffff, 0xffff, 0xffff, 0xffff, 0xffff, 0xffff, 0xffff, 0xffff, 0xffff, 0xffff, 0xffff, 0xffff, 0xffff, 0xffff, 0xffff, 0xffff,
	0xffff, 0xffff, 0xffff, 0xffff, 0xffff, 0xffff, 0xffff, 0xffff, 0xffff, 0xffff, 0xffff, 0xffff, 0xffff, 0xffff, 0xffff, 0xffff,
	0xffff, 0xffff, 0xffff, 0xffff, 0x0d0a, 0x0d0a, 0x0d0a, 0x0d09, 0xffff, 0xffff, 0xffff, 0x10a3, 0x10c3, 0x10c3, 0x10c3, 0xffff,
	0xffff, 0xffff, 0xffff, 0xffff, 0xffff, 0xffff, 0xffff, 0xffff, 0xffff, 0xffff, 0xffff, 0xffff, 0xffff, 0xffff, 0xffff, 0xffff,
	0xffff, 0xffff, 0xffff, 0xffff, 0xffff, 0xffff, 0xffff, 0xffff, 0xffff, 0xffff, 0xffff, 0xffff, 0xffff, 0xffff, 0xffff, 0xffff,
	0x10a2, 0x10c3, 0x10c3, 0x10a3, 0xffff, 0xffff, 0xffff, 0x0d09, 0x0d0a, 0x0d0a, 0x0d0a, 0xffff, 0xffff, 0xffff, 0xffff, 0xffff,
	0xffff, 0xffff, 0xffff, 0xffff, 0xffff, 0xffff, 0xffff, 0xffff, 0xffff, 0xffff, 0xffff, 0xffff, 0xffff, 0xffff, 0xffff, 0xffff,
	0xffff, 0xffff, 0xffff, 0xffff, 0xffff, 0xffff, 0xffff, 0xffff, 0xffff, 0xffff, 0xffff, 0xffff, 0xffff, 0xffff, 0xffff, 0xffff,
	0xffff, 0xffff, 0xffff, 0xffff, 0xffff, 0xffff, 0xffff, 0xffff, 0xffff, 0xffff, 0xffff, 0xffff, 0xffff, 0xffff, 0xffff, 0xffff,
	0xffff, 0xffff, 0xffff, 0xffff, 0xffff, 0xffff, 0xffff, 0xffff, 0xffff, 0xffff, 0xffff, 0xffff, 0xffff, 0xffff, 0xffff, 0xffff,
	0xffff, 0xffff, 0xffff, 0xffff, 0xffff, 0xffff, 0xffff, 0xffff, 0xffff, 0xffff, 0xffff, 0xffff, 0xffff, 0xffff, 0xffff, 0xffff,
	0xffff, 0xffff, 0xffff, 0xffff, 0xffff, 0xffff, 0xffff, 0xffff, 0xffff, 0xffff, 0xffff, 0xffff, 0xffff, 0xffff, 0xffff, 0xffff,
	0xffff, 0xffff, 0xffff, 0xffff, 0xffff, 0x152b, 0x0d0a, 0x0d0a, 0x050a, 0xffff, 0xffff, 0xffff, 0x2124, 0x10c3, 0x10c3, 0x10a3,
	0xffff, 0xffff, 0xffff, 0xffff, 0xffff, 0xffff, 0xffff, 0xffff, 0xffff, 0xffff, 0xffff, 0xffff, 0xffff, 0xffff, 0xffff, 0xffff,
	0xffff, 0xffff, 0xffff, 0xffff, 0xffff, 0xffff, 0xffff, 0xffff, 0xffff, 0xffff, 0xffff, 0xffff, 0xffff, 0xffff, 0xffff, 0x10c3,
	0x10c3, 0x10c3, 0x10a2, 0xffff, 0xffff, 0xffff, 0x0d0a, 0x0d0a, 0x0d0a, 0x6632, 0xffff, 0xffff, 0xffff, 0xffff, 0xffff, 0xffff,
	0xffff, 0xffff, 0xffff, 0xffff, 0xffff, 0xffff, 0xffff, 0xffff, 0xffff, 0xffff, 0xffff, 0xffff, 0xffff, 0xffff, 0xffff, 0xffff,
	0xffff, 0xffff, 0xffff, 0xffff, 0xffff, 0xffff, 0xffff, 0xffff, 0xffff, 0xffff, 0xffff, 0xffff, 0xffff, 0xffff, 0xffff, 0xffff,
	0xffff, 0xffff, 0xffff, 0xffff, 0xffff, 0xffff, 0xffff, 0xffff, 0xffff, 0xffff, 0xffff, 0xffff, 0xffff, 0x45cf, 0x0d0a, 0x0d0a,
	0x0d0a, 0x0d0a, 0x45cf, 0xffff, 0xffff, 0xffff, 0xffff, 0xffff, 0xffff, 0xffff, 0xffff, 0xffff, 0xffff, 0xffff, 0xffff, 0xffff,
	0xffff, 0xffff, 0xffff, 0xffff, 0xffff, 0xffff, 0xffff, 0xffff, 0xffff, 0xffff, 0xffff, 0xffff, 0xffff, 0xffff, 0xffff, 0xffff,
	0xffff, 0xffff, 0xffff, 0xffff, 0xffff, 0xffff, 0xffff, 0xffff, 0xffff, 0xffff, 0xffff, 0xffff, 0xffff, 0xffff, 0xffff, 0xffff,
	0xffff, 0xffff, 0xffff, 0xffff, 0xffff, 0xffff, 0xffff, 0x0d0a, 0x0d0a, 0x0d0a, 0xffff, 0xffff, 0xffff, 0x3186, 0x10c3, 0x10c3,
	0x10c3, 0xffff, 0xffff, 0xffff, 0xffff, 0xffff, 0xffff, 0xffff, 0xffff, 0xffff, 0xffff, 0xffff, 0xffff, 0xffff, 0xffff, 0xffff,
	0xffff, 0xffff, 0xffff, 0xffff, 0xffff, 0xffff, 0xffff, 0xffff, 0xffff, 0xffff, 0xffff, 0xffff, 0xffff, 0xffff, 0x10a3, 0x10c3,
	0x10c3, 0x10c3, 0xffff, 0xffff, 0xffff, 0x0d0a, 0x0d0a, 0x0d0a, 0xffff, 0xffff, 0xffff, 0xffff, 0xffff, 0xffff, 0xffff, 0xffff,
	0xffff, 0xffff, 0xffff, 0xffff, 0xffff, 0xffff, 0xffff, 0xffff, 0xffff, 0xffff, 0xffff, 0xffff, 0xffff, 0xffff, 0xffff, 0xffff,
	0xffff, 0xffff, 0xffff, 0xffff, 0xffff, 0xffff, 0xffff, 0xffff, 0xffff, 0xffff, 0xffff, 0xffff, 0xffff, 0xffff, 0xffff, 0xffff,
	0xffff, 0xffff, 0xffff, 0xffff, 0xffff, 0x0509, 0x0d0a, 0x0d0a, 0x0d0a, 0x0d0a, 0x0d0a, 0x0d0a, 0x0d0a, 0x0d0a, 0x0d0a, 0x0d0a,
	0x0d0a, 0x0d0a, 0x0d0a, 0x0d0a, 0x0d0a, 0x0d0a, 0x0d0a, 0x0d0a, 0x0d09, 0x0d0a, 0x0d0a, 0xffff, 0xffff, 0xffff, 0xffff, 0xffff,
	0xffff, 0xffff, 0xffff, 0xffff, 0xffff, 0xffff, 0xffff, 0xffff, 0xffff, 0xffff, 0xffff, 0xffff, 0xffff, 0xffff, 0xffff, 0xffff,
	0xffff, 0xffff, 0xffff, 0xffff, 0xffff, 0xffff, 0xffff, 0xffff, 0xffff, 0xffff, 0xffff, 0xffff, 0xffff, 0xffff, 0xffff, 0xffff,
	0xffff, 0xffff, 0xffff, 0xffff, 0xffff, 0xffff, 0xffff, 0xffff, 0x0d0a, 0x0d0a, 0x0d0a, 0xffff, 0xffff, 0xffff, 0x10a3, 0x10c3,
	0x10c3, 0x10c3, 0xffff, 0xffff, 0xffff, 0xffff, 0xffff, 0xffff, 0xffff, 0xffff, 0xffff, 0xffff, 0xffff, 0xffff, 0xffff, 0xffff,
	0xffff, 0xffff, 0xffff, 0xffff, 0xffff, 0xffff, 0xffff, 0xffff, 0xffff, 0xffff, 0xffff, 0xffff, 0xffff, 0x4a8a, 0x10c3, 0x10c3,
	0x10c3, 0xffff, 0xffff, 0xffff, 0x050a, 0x0d0a, 0x0d2a, 0xc75a, 0xffff, 0xffff, 0xffff, 0xffff, 0xffff, 0xffff, 0xffff, 0xffff,
	0xffff, 0xffff, 0xffff, 0xffff, 0xffff, 0xffff, 0xffff, 0xffff, 0xffff, 0xffff, 0xffff, 0xffff, 0xffff, 0xffff, 0xffff, 0xffff,
	0xffff, 0xffff, 0xffff, 0xffff, 0xffff, 0xffff, 0xffff, 0xffff, 0xffff, 0xffff, 0xffff, 0xffff, 0xffff, 0xffff, 0xffff, 0xffff,
	0xdf9c, 0x0d0a, 0x0d0a, 0x0d0a, 0x0d0a, 0x0d0a, 0x0d0a, 0x0d0a, 0x0d0a, 0x0d0a, 0x0d0a, 0x0d0a, 0x0d0a, 0x0d0a, 0x0d0a, 0x0d0a,
	0x0d0a, 0x0d0a, 0x0d0a, 0x0d0a, 0x0d0a, 0x0d0a, 0x0d0a, 0x0d0a, 0x0d0a, 0x0d0a, 0x0d0a, 0x0d0a, 0x0d0a, 0x0d0a, 0x0d2a, 0xa6f7,
	0xffff, 0xffff, 0xffff, 0xffff, 0xffff, 0xffff, 0xffff, 0xffff, 0xffff, 0xffff, 0xffff, 0xffff, 0xffff, 0xffff, 0xffff, 0xffff,
	0xffff, 0xffff, 0xffff, 0xffff, 0xffff, 0xffff, 0xffff, 0xffff, 0xffff, 0xffff, 0xffff, 0xffff, 0xffff, 0xffff, 0xffff, 0xffff,
	0xffff, 0xffff, 0xffff, 0xffff, 0xffff, 0xffff, 0xffff, 0xffff, 0xffff, 0x0509, 0x0d0a, 0x0d0a, 0xffff, 0xffff, 0xffff, 0x10c3,
	0x10c3, 0x10c3, 0x10a3, 0xffff, 0xffff, 0xffff, 0xffff, 0xffff, 0xffff, 0xffff, 0xffff, 0xffff, 0xffff, 0xffff, 0xffff, 0xffff,
	0xffff, 0xffff, 0xffff, 0xffff, 0xffff, 0xffff, 0xffff, 0xffff, 0xffff, 0xffff, 0xffff, 0xffff, 0xffff, 0x10c3, 0x10c3, 0x10c3,
	0xffff, 0xffff, 0xffff, 0x0d0a, 0x0d0a, 0x0d0a, 0xc75a, 0xffff, 0xffff, 0xffff, 0xffff, 0xffff, 0xffff, 0xffff, 0xffff, 0xffff,
	0xffff, 0xffff, 0xffff, 0xffff, 0xffff, 0xffff, 0xffff, 0xffff, 0xffff, 0xffff, 0xffff, 0xffff, 0xffff, 0xffff, 0xffff, 0xffff,
	0xffff, 0xffff, 0xffff, 0xffff, 0xffff, 0xffff, 0xffff, 0xffff, 0xffff, 0xffff, 0xffff, 0xffff, 0xffff, 0x154b, 0x0d0a, 0x0d0a,
	0x0d0a, 0x0d0a, 0x0d0a, 0x0d0a, 0x0d0a, 0x0d0a, 0x0d0a, 0x0d0a, 0x0d0a, 0x0d0a, 0x0d0a, 0x0d0a, 0x0d0a, 0x0d0a, 0x0d0a, 0x0d0a,
	0x0d0a, 0x0d0a, 0x0d0a, 0x0d0a, 0x0d0a, 0x0d0a, 0x0d0a, 0x0d0a, 0x0d0a, 0x0d0a, 0x0d0a, 0x0d0a, 0x0d0a, 0x0d0a, 0x0d0a, 0x0d0a,
	0x0d0a, 0x0d2a, 0x0d09, 0xffff, 0xffff, 0xffff, 0xffff, 0xffff, 0xffff, 0xffff, 0xffff, 0xffff, 0xffff, 0xffff, 0xffff, 0xffff,
	0xffff, 0xffff, 0xffff, 0xffff, 0xffff, 0xffff, 0xffff, 0xffff, 0xffff, 0xffff, 0xffff, 0xffff, 0xffff, 0xffff, 0xffff, 0xffff,
	0xffff, 0xffff, 0xffff, 0xffff, 0xffff, 0xffff, 0xffff, 0xffff, 0xffff, 0xffff, 0x0d0a, 0x0d0a, 0x0d2a, 0xffff, 0xffff, 0xffff,
	0x10a3, 0x10c3, 0x10a2, 0xe71c, 0xffff, 0xffff, 0xffff, 0xffff, 0xffff, 0xffff, 0xffff, 0xffff, 0xffff, 0xffff, 0xffff, 0xffff,
	0xffff, 0xffff, 0xffff, 0xffff, 0xffff, 0xffff, 0xffff, 0xffff, 0xffff, 0xffff, 0xffff, 0xffff, 0x10c3, 0x10c3, 0x10c3, 0xffff,
	0xffff, 0xffff, 0x0d2a, 0x0d0a, 0x0d0a, 0x45cf, 0xffff, 0xffff, 0xffff, 0xffff, 0xffff, 0xffff, 0xffff, 0xffff, 0xffff, 0xffff,
	0xffff, 0xffff, 0xffff, 0xffff, 0xffff, 0xffff, 0xffff, 0xffff, 0xffff, 0xffff, 0xffff, 0xffff, 0xffff, 0xffff, 0xffff, 0xffff,
	0xffff, 0xffff, 0xffff, 0xffff, 0xffff, 0xffff, 0xffff, 0xffff, 0xffff, 0xffff, 0xffff, 0x0d0a, 0x0d0a, 0x0d0a, 0x0d0a, 0x0d0a,
	0x0d0a, 0x0d0a, 0x0d0a, 0x0d0a, 0x0d0a, 0x0d0a, 0x0d0a, 0x0d0a, 0x0d0a, 0x0d0a, 0x0d0a, 0x0d0a, 0x0d0a, 0x0d0a, 0x0d0a, 0x0d0a,
	0x0d0a, 0x0d0a, 0x0d0a, 0x0d0a, 0x0d0a, 0x0d0a, 0x0d0a, 0x0d0a, 0x0d0a, 0x0d0a, 0x0d0a, 0x0d0a, 0x0d0a, 0x0d0a, 0x0d0a, 0x0d0a,
	0x0d0a, 0x0d0a, 0x0d0a, 0x0d0a, 0x0d2a, 0xffff, 0xffff, 0xffff, 0xffff, 0xffff, 0xffff, 0xffff, 0xffff, 0xffff, 0xffff, 0xffff,
	0xffff, 0xffff, 0xffff, 0xffff, 0xffff, 0xffff, 0xffff, 0xffff, 0xffff, 0xffff, 0xffff, 0xffff, 0xffff, 0xffff, 0xffff, 0xffff,
	0xffff, 0xffff, 0xffff, 0xffff, 0xffff, 0xffff, 0xffff, 0xffff, 0xffff, 0xffff, 0xffff, 0x0d0a, 0x0d0a, 0x0d0a, 0xffff, 0xffff,
	0xffff, 0x10c3, 0x10c3, 0x10c3, 0xffff, 0xffff, 0xffff, 0xffff, 0xffff, 0xffff, 0xffff, 0xffff, 0xffff, 0xffff, 0xffff, 0xffff,
	0xffff, 0xffff, 0xffff, 0xffff, 0xffff, 0xffff, 0xffff, 0xffff, 0xffff, 0xffff, 0xffff, 0x10c3, 0x10c3, 0x10c3, 0xffff, 0xffff,
	0xffff, 0xffff, 0x0d0a, 0x0d0a, 0x0d2a, 0xffff, 0xffff, 0xffff, 0xffff, 0xffff, 0xffff, 0xffff, 0xffff, 0xffff, 0xffff, 0xffff,
	0xffff, 0xffff, 0xffff, 0xffff, 0xffff, 0xffff, 0xffff, 0xffff, 0xffff, 0xffff, 0xffff, 0xffff, 0xffff, 0xffff, 0xffff, 0xffff,
	0xffff, 0xffff, 0xffff, 0xffff, 0xffff, 0xffff, 0xffff, 0xffff, 0x0d0a, 0x0d0a, 0x0d0a, 0x0d0a, 0x0d0a, 0x0d0a, 0x0d0a, 0x0d0a,
	0x0d0a, 0x0d0a, 0x0d0a, 0x0d0a, 0x0d0a, 0x0d0a, 0x0d0a, 0x0d0a, 0x0d0a, 0x0d0a, 0x0d0a, 0x0d0a, 0x0d0a, 0x0d0a, 0x0d0a, 0x0d0a,
	0x0d0a, 0x0d0a, 0x0d0a, 0x0d0a, 0x0d0a, 0x0d0a, 0x0d0a, 0x0d0a, 0x0d0a, 0x0d0a, 0x0d0a, 0x0d0a, 0x0d0a, 0x0d0a, 0x0d0a, 0x0d0a,
	0x0d0a, 0x0d0a, 0x0d0a, 0x0d0a, 0x0d0a, 0x0d0a, 0x0d0a, 0x052a, 0xffff, 0xffff, 0xffff, 0xffff, 0xffff, 0xffff, 0xffff, 0xffff,
	0xffff, 0xffff, 0xffff, 0xffff, 0xffff, 0xffff, 0xffff, 0xffff, 0xffff, 0xffff, 0xffff, 0xffff, 0xffff, 0xffff, 0xffff, 0xffff,
	0xffff, 0xffff, 0xffff, 0xffff, 0xffff, 0xffff, 0xffff, 0xffff, 0xffff, 0xffff, 0xffff, 0x050a, 0x0d0a, 0x0d0a, 0xefde, 0xffff,
	0xffff, 0xffff, 0x10c3, 0x10c3, 0x10c3, 0xffff, 0xffff, 0xffff, 0xffff, 0xffff, 0xffff, 0xffff, 0xffff, 0xffff, 0xffff, 0xffff,
	0xffff, 0xffff, 0xffff, 0xffff, 0xffff, 0xffff, 0xffff, 0xffff, 0xffff, 0xffff, 0x10a2, 0x10c3, 0x10c3, 0x10a3, 0xffff, 0xffff,
	0xffff, 0x0d2a, 0x0d0a, 0x0d09, 0xffff, 0xffff, 0xffff, 0xffff, 0xffff, 0xffff, 0xffff, 0xffff, 0xffff, 0xffff, 0xffff, 0xffff,
	0xffff, 0xffff, 0xffff, 0xffff, 0xffff, 0xffff, 0xffff, 0xffff, 0xffff, 0xffff, 0xffff, 0xffff, 0xffff, 0xffff, 0xffff, 0xffff,
	0xffff, 0xffff, 0xffff, 0xffff, 0xffff, 0xffff, 0x8694, 0x0d0a, 0x0d0a, 0x0d0a, 0x0d0a, 0x0d0a, 0x0d0a, 0x0d0a, 0x0d0a, 0x0d0a,
	0x0d0a, 0x0d0a, 0x0d0a, 0x0d0a, 0x0d0a, 0x0d0a, 0x0d0a, 0x0d0a, 0x0d0a, 0x0d0a, 0x0d0a, 0x0d0a, 0x0d0a, 0x0d0a, 0x0d0a, 0x0d0a,
	0x0d0a, 0x0d0a, 0x0d0a, 0x0d0a, 0x0d0a, 0x0d0a, 0x0d0a, 0x0d0a, 0x0d0a, 0x0d0a, 0x0d0a, 0x0d0a, 0x0d0a, 0x0d0a, 0x0d0a, 0x0d0a,
	0x0d0a, 0x0d0a, 0x0d0a, 0x0d0a, 0x0d0a, 0x0d0a, 0x0d0a, 0x0d0a, 0x0d09, 0x1d4b, 0xffff, 0xffff, 0xffff, 0xffff, 0xffff, 0xffff,
	0xffff, 0xffff, 0xffff, 0xffff, 0xffff, 0xffff, 0xffff, 0xffff, 0xffff, 0xffff, 0xffff, 0xffff, 0xffff, 0xffff, 0xffff, 0xffff,
	0xffff, 0xffff, 0xffff, 0xffff, 0xffff, 0xffff, 0xffff, 0xffff, 0xffff, 0xffff, 0xffff, 0xffff, 0x0d2a, 0x0d0a, 0x0d29, 0xffff,
	0xffff, 0xffff, 0x3186, 0x10c3, 0x10c3, 0x10a2, 0xffff, 0xffff, 0xffff, 0xffff, 0xffff, 0xffff, 0xffff, 0xffff, 0xffff, 0xffff,
	0xffff, 0xffff, 0xffff, 0xffff, 0xffff, 0xffff, 0xffff, 0xffff, 0xffff, 0xffff, 0x10c3, 0x10c3, 0x10c3, 0xffff, 0xffff, 0xffff,
	0x0d0a, 0x0d0a, 0x0d0a, 0xffff, 0xffff, 0xffff, 0xffff, 0xffff, 0xffff, 0xffff, 0xffff, 0xffff, 0x10c3, 0x10a2, 0xffff, 0xffff,
	0xffff, 0xffff, 0xffff, 0xffff, 0xffff, 0xffff, 0xffff, 0xffff, 0xffff, 0xffff, 0xffff, 0xffff, 0xffff, 0xffff, 0xffff, 0xffff,
	0xffff, 0xffff, 0xffff, 0xffff, 0xffff, 0x0d0a, 0x0d0a, 0x0d0a, 0x0d0a, 0x0d0a, 0x0d0a, 0x0d0a, 0x0d0a, 0x0d0a, 0x0d0a, 0x0d0a,
	0x0d0a, 0x0d0a, 0x0d0a, 0x0d0a, 0x0d0a, 0x0d0a, 0x0d0a, 0x0d0a, 0x0d0a, 0x0d0a, 0x0d0a, 0x0d0a, 0x0d0a, 0x0d0a, 0x0d0a, 0x0d0a,
	0x0d0a, 0x0d0a, 0x0d0a, 0x0d0a, 0x0d0a, 0x0d0a, 0x0d0a, 0x0d0a, 0x0d0a, 0x0d0a, 0x0d0a, 0x0d0a, 0x0d0a, 0x0d0a, 0x0d0a, 0x0d0a,
	0x0d0a, 0x0d0a, 0x0d0a, 0x0d0a, 0x0d0a, 0x0d0a, 0x0d0a, 0x0d0a, 0x0d0a, 0x0d0a, 0x0d0a, 0xffff, 0xffff, 0xffff, 0xffff, 0xffff,
	0xffff, 0xffff, 0xffff, 0xffff, 0xffff, 0xffff, 0xffff, 0xffff, 0xffff, 0xffff, 0xffff, 0xffff, 0xffff, 0xffff, 0xffff, 0xffff,
	0xffff, 0xffff, 0xffff, 0xffff, 0xffff, 0xffff, 0xffff, 0x10c3, 0x10c3, 0xffff, 0xffff, 0xffff, 0xffff, 0x0d09, 0x0d0a, 0x0d0a,
	0xffff, 0xffff, 0xffff, 0x10c3, 0x10c3, 0x10c3, 0xffff, 0xffff, 0xffff, 0xffff, 0xffff, 0xffff, 0xffff, 0xffff, 0xffff, 0xffff,
	0xffff, 0xffff, 0xffff, 0xffff, 0xffff, 0xffff, 0xffff, 0xffff, 0xffff, 0x10a3, 0x10c3, 0x10c3, 0xffff, 0xffff, 0xffff, 0x0d0a,
	0x0d0a, 0x0d0a, 0xffff, 0xffff, 0xffff, 0xffff, 0xffff, 0xffff, 0xffff, 0xffff, 0xffff, 0x10a3, 0x10c3, 0x10c3, 0x10c3, 0x10c3,
	0xffff, 0xffff, 0xffff, 0xffff, 0xffff, 0xffff, 0xffff, 0xffff, 0xffff, 0xffff, 0xffff, 0xffff, 0xffff, 0xffff, 0xffff, 0xffff,
	0xffff, 0xffff, 0xffff, 0x0d2a, 0x0d0a, 0x0d0a, 0x0d0a, 0x0d0a, 0x0d0a, 0x0d0a, 0x0d0a, 0x0d0a, 0x0d0a, 0x0d0a, 0x0d0a, 0x0d0a,
	0x0d0a, 0x0d0a, 0x0d0a, 0x0d0a, 0x0d0a, 0x0d0a, 0x0d0a, 0x0d0a, 0x0d0a, 0x0d0a, 0x0d0a, 0x0d0a, 0x0d0a, 0x0d0a, 0x0d0a, 0x0d0a,
	0x0d0a, 0x0d0a, 0x0d0a, 0x0d0a, 0x0d0a, 0x0d0a, 0x0d0a, 0x0d0a, 0x0d0a, 0x0d0a, 0x0d0a, 0x0d0a, 0x0d0a, 0x0d0a, 0x0d0a, 0x0d0a,
	0x0d0a, 0x0d0a, 0x0d0a, 0x0d0a, 0x0d0a, 0x0d0a, 0x0d0a, 0x0d0a, 0x0d0a, 0x0d0a, 0x0d0a, 0x0d0a, 0x0d0a, 0xffff, 0xffff, 0xffff,
	0xffff, 0xffff, 0xffff, 0xffff, 0xffff, 0xffff, 0xffff, 0xffff, 0xffff, 0xffff, 0xffff, 0xffff, 0xffff, 0xffff, 0xffff, 0xffff,
	0xffff, 0xffff, 0xffff, 0xffff, 0xffff, 0xffff, 0xffff, 0x10c3, 0x10c3, 0xffff, 0xffff, 0xffff, 0xffff, 0xffff, 0x0d0a, 0x0d0a,
	0x0d0a, 0xffff, 0xffff, 0xffff, 0x10a2, 0x10c3, 0x10a2, 0xffff, 0xffff, 0xffff, 0xffff, 0xffff, 0xffff, 0xffff, 0xffff, 0xffff,
	0xffff, 0xffff, 0xffff, 0xffff, 0xffff, 0xffff, 0xffff, 0xffff, 0x2124, 0x10c3, 0x10c3, 0x2986, 0xffff, 0xffff, 0xffff, 0x0d0a,
	0x0d0a, 0x0d09, 0xffff, 0xffff, 0xffff, 0xffff, 0xffff, 0xffff, 0xffff, 0xffff, 0xffff, 0xffff, 0x10c3, 0x10c3, 0x10c3, 0x10c3,
	0x10c3, 0x10c3, 0xffff, 0xffff, 0xffff, 0xffff, 0xffff, 0xffff, 0xffff, 0xffff, 0xffff, 0xffff, 0xffff, 0xffff, 0xffff, 0xffff,
	0xffff, 0x6632, 0x0d0a, 0x0d0a, 0x0d0a, 0x0d0a, 0x0d0a, 0x0d0a, 0x0d0a, 0x0d0a, 0x0d0a, 0x0d0a, 0x0d0a, 0x0d0a, 0x0d0a, 0x0d0a,
	0x0d0a, 0x0d0a, 0x0d0a, 0x0d0a, 0x0d0a, 0x6632, 0x0d0a, 0x0d0a, 0x0d0a, 0x0d0a, 0x0d0a, 0x0d0a, 0x0d0a, 0x0d0a, 0x0d0a, 0x0d0a,
	0x0d0a, 0x0d0a, 0x0d0a, 0x0d0a, 0x0d0a, 0x0d0a, 0x0d0a, 0x0d0a, 0x0d0a, 0x0d0a, 0xffff, 0x0d0a, 0x0d0a, 0x0d0a, 0x0d0a, 0x0d0a,
	0x0d0a, 0x0d0a, 0x0d0a, 0x0d0a, 0x0d0a, 0x0d0a, 0x0d0a, 0x0d0a, 0x0d0a, 0x0d0a, 0x0d0a, 0x0d0a, 0x0d0a, 0x0d0a, 0x052a, 0xffff,
	0xffff, 0xffff, 0xffff, 0xffff, 0xffff, 0xffff, 0xffff, 0xffff, 0xffff, 0xffff, 0xffff, 0xffff, 0xffff, 0xffff, 0xffff, 0xffff,
	0xffff, 0xffff, 0xffff, 0x10a3, 0x10c3, 0x2124, 0xffff, 0xffff, 0xffff, 0xffff, 0xffff, 0xffff, 0xffff, 0xffff, 0x4dcf, 0x0d0a,
	0x0d0a, 0xffff, 0xffff, 0xffff, 0xe71c, 0x10c3, 0x10c3, 0x10c3, 0xffff, 0xffff, 0xffff, 0xffff, 0xffff, 0xffff, 0xffff, 0xffff,
	0xffff, 0xffff, 0xffff, 0xffff, 0xffff, 0xffff, 0xffff, 0xffff, 0x10a3, 0x10c3, 0x10c3, 0xffff, 0xffff, 0xffff, 0x0d09, 0x0d0a,
	0x0d0a, 0xffff, 0xffff, 0xffff, 0xffff, 0xffff, 0xffff, 0xffff, 0xffff, 0xffff, 0xffff, 0xffff, 0xffff, 0xffff, 0x10a3, 0x10c3,
	0x10c3, 0x10c3, 0x10c3, 0x10a3, 0xffff, 0xffff, 0xffff, 0xffff, 0xffff, 0xffff, 0xffff, 0xffff, 0xffff, 0xffff, 0xffff, 0xffff,
	0x0d09, 0x0d0a, 0x0d0a, 0x0d0a, 0x0d0a, 0x0d0a, 0x0d0a, 0x0d0a, 0x0d0a, 0x0d0a, 0x0d0a, 0x0d0a, 0x0d0a, 0x0d0a, 0x0d0a, 0x0d0a,
	0x0d0a, 0x0d0a, 0x0d0a, 0x0d0a, 0x0d0a, 0xffff, 0xffff, 0x0d0a, 0x0d0a, 0x0d0a, 0x0d0a, 0x0d0a, 0x0d0a, 0x0d0a, 0x0d0a, 0x0d0a,
	0x0d0a, 0x0d0a, 0x0d0a, 0x0d0a, 0x0d0a, 0x0d0a, 0x0d0a, 0x0d0a, 0x0d0a, 0x7653, 0xffff, 0x0d0a, 0x0d0a, 0x0d0a, 0x0d0a, 0x0d0a,
	0x0d0a, 0x0d0a, 0x0d0a, 0x0d0a, 0x0d0a, 0x0d0a, 0x0d0a, 0x0d0a, 0x0d0a, 0x0d0a, 0x0d0a, 0x0d0a, 0x0d0a, 0x0d0a, 0x0d0a, 0x0d0a,
	0xffff, 0xffff, 0xffff, 0xffff, 0xffff, 0xffff, 0xffff, 0xffff, 0xffff, 0xffff, 0xffff, 0xffff, 0xffff, 0xffff, 0xffff, 0xffff,
	0xffff, 0x10c3, 0x10c3, 0x10c3, 0x10c3, 0x10c3, 0xffff, 0xffff, 0xffff, 0xffff, 0xffff, 0xffff, 0xffff, 0xffff, 0xffff, 0x0529,
	0x0d0a, 0x050a, 0xffff, 0xffff, 0xffff, 0x10a3, 0x10c3, 0x10c3, 0xffff, 0xffff, 0xffff, 0xffff, 0xffff, 0xffff, 0xffff, 0xffff,
	0xffff, 0xffff, 0xffff, 0xffff, 0xffff, 0xffff, 0xffff, 0x10c3, 0x10c3, 0x10c3, 0xffff, 0xffff, 0xffff, 0x0509, 0x0d0a, 0x0d09,
	0xffff, 0xffff, 0xffff, 0xffff, 0xffff, 0xffff, 0xffff, 0xffff, 0xffff, 0xffff, 0xffff, 0xffff, 0xffff, 0xffff, 0xffff, 0xffff,
	0x10a3, 0x10c3, 0x10c3, 0x10c3, 0x10c3, 0x10a2, 0xffff, 0xffff, 0xffff, 0xffff, 0xffff, 0xffff, 0xffff, 0xffff, 0xffff, 0x0d0a,
	0x0d0a, 0x0d0a, 0x0d0a, 0x0d0a, 0x0d0a, 0x0d0a, 0x0d0a, 0x0d0a, 0x0d0a, 0x0d0a, 0x0d0a, 0x0d0a, 0x0d0a, 0x0d0a, 0x0d0a, 0x0d0a,
	0x0d0a, 0x0d0a, 0x0d0a, 0x0d0a, 0x0d0a, 0xffff, 0xffff, 0x0d0a, 0x0d0a, 0x0d0a, 0x0d0a, 0x0d0a, 0x0d0a, 0x0d0a, 0x0d0a, 0x0d0a,
	0x0d0a, 0x0d0a, 0x0d0a, 0x0d0a, 0x0d0a, 0x0d0a, 0x0d0a, 0x0d0a, 0x0d0a, 0xffff, 0xffff, 0x0d0a, 0x0d0a, 0x0d0a, 0x0d0a, 0x0d0a,
	0x0d0a, 0x0d0a, 0x0d0a, 0x0d0a, 0x0d0a, 0x0d0a, 0x0d0a, 0x0d0a, 0x0d0a, 0x0d0a, 0x0d0a, 0x0d0a, 0x0d0a, 0x0d0a, 0x0d0a, 0x0d0a,
	0x0d0a, 0xffff, 0xffff, 0xffff, 0xffff, 0xffff, 0xffff, 0xffff, 0xffff, 0xffff, 0xffff, 0xffff, 0xffff, 0xffff, 0xffff, 0x10c3,
	0x10c3, 0x10c3, 0x10c3, 0x10c3, 0x10a3, 0xffff, 0xffff, 0xffff, 0xffff, 0xffff, 0xffff, 0xffff, 0xffff, 0xffff, 0xffff, 0xffff,
	0x0d0a, 0x0d0a, 0x0509, 0xffff, 0xffff, 0xffff, 0x10c3, 0x10c3, 0x10a3, 0xffff, 0xffff, 0xffff, 0xffff, 0xffff, 0xffff, 0xffff,
	0xffff, 0xffff, 0xffff, 0xffff, 0xffff, 0xffff, 0xffff, 0x10c3, 0x10c3, 0x10a2, 0xffff, 0xffff, 0xffff, 0x0d0a, 0x0d0a, 0x256c,
	0xffff, 0xffff, 0xffff, 0xffff, 0xffff, 0xffff, 0xffff, 0xffff, 0x10a2, 0x10c3, 0x10c3, 0x10c3, 0x10c3, 0x10c3, 0x10c3, 0x10c3,
	0x10c3, 0xffff, 0x10a3, 0x10c3, 0x10c3, 0x10c3, 0x10c3, 0x7bcf, 0xffff, 0xffff, 0xffff, 0xffff, 0xffff, 0xd77b, 0x0d0a, 0x0d0a,
	0x0d0a, 0x0d0a, 0x0d0a, 0x0d0a, 0x0d0a, 0x0d0a, 0x0d0a, 0x0d0a, 0x0d0a, 0x0d0a, 0x0d0a, 0x0d0a, 0x0d0a, 0x0d0a, 0x0d0a, 0x0d0a,
	0x0d0a, 0x0d0a, 0x0d0a, 0x0d0a, 0x0d09, 0xffff, 0xffff, 0x0d0a, 0x0d0a, 0x0d0a, 0x0d0a, 0x0d0a, 0x0d0a, 0x0d0a, 0x0d0a, 0x0d0a,
	0x0d0a, 0x0d0a, 0x0d0a, 0x0d0a, 0x0d0a, 0x0d0a, 0x0d0a, 0x0d0a, 0x0d09, 0xffff, 0xffff, 0xa6d7, 0x0d0a, 0x0d0a, 0x0d0a, 0x0d0a,
	0x0d0a, 0x0d0a, 0x0d0a, 0x0d0a, 0x0d0a, 0x0d0a, 0x0d0a, 0x0d0a, 0x0d0a, 0x0d0a, 0x0d0a, 0x0d0a, 0x0d0a, 0x0d0a, 0x0d0a, 0x0d0a,
	0x0d0a, 0x0d0a, 0x35ae, 0xffff, 0xffff, 0xffff, 0xffff, 0xffff, 0xffff, 0xffff, 0xffff, 0xffff, 0xffff, 0x10a2, 0x10c3, 0x10c3,
	0x10c3, 0x10c3, 0x10a2, 0xffff, 0xffff, 0xffff, 0xffff, 0xffff, 0xffff, 0xffff, 0xffff, 0xffff, 0xffff, 0xffff, 0xffff, 0xffff,
	0xf7de, 0x0d0a, 0x0d0a, 0xffff, 0xffff, 0xffff, 0x10a2, 0x10c3, 0x10c3, 0xf79e, 0xffff, 0xffff, 0xffff, 0xffff, 0xffff, 0xffff,
	0xffff, 0xffff, 0xffff, 0xffff, 0xffff, 0xffff, 0x10c3, 0x10c3, 0x10c3, 0xffff, 0xffff, 0xffff, 0x0d0a, 0x0d0a, 0x0d0a, 0xffff,
	0xffff, 0xffff, 0xffff, 0xffff, 0xffff, 0xffff, 0xffff, 0x10c3, 0x10c3, 0x10a2, 0x10a3, 0x10a3, 0x10a3, 0x10a3, 0x10a3, 0x10c3,
	0x10c3, 0x10a3, 0xffff, 0xffff, 0x10a3, 0x10c3, 0x10c3, 0x10a3, 0xffff, 0xffff, 0xffff, 0xffff, 0x0529, 0x0d0a, 0x0d0a, 0x0d0a,
	0x0d0a, 0x0d0a, 0x0d0a, 0x0d0a, 0x0d0a, 0x0d0a, 0x0d0a, 0x0d0a, 0x0d0a, 0x0d0a, 0x0d0a, 0x0d0a, 0x0d0a, 0x0d0a, 0x0d0a, 0x0d0a,
	0x0d0a, 0x0d0a, 0x0d0a, 0x0d0a, 0xffff, 0xffff, 0xffff, 0x0d09, 0x0d0a, 0x0d0a, 0x0d0a, 0x0d0a, 0x0d0a, 0x0d0a, 0x0d0a, 0x0d0a,
	0x0d0a, 0x0d0a, 0x0d0a, 0x0d0a, 0x0d0a, 0x0d0a, 0x0d0a, 0x0d0a, 0x0d09, 0xffff, 0xffff, 0xffff, 0x0d0a, 0x0d0a, 0x0d0a, 0x0d0a,
	0x0d0a, 0x0d0a, 0x0d0a, 0x0d0a, 0x0d0a, 0x0d0a, 0x0d0a, 0x0d0a, 0x0d0a, 0x0d0a, 0x0d0a, 0x0d0a, 0x0d0a, 0x0d0a, 0x0d0a, 0x0d0a,
	0x0d0a, 0x0d0a, 0x0d0a, 0x0d0a, 0xffff, 0xffff, 0xffff, 0xffff, 0xffff, 0xffff, 0xffff, 0x10a2, 0x10c3, 0x10c3, 0x10c3, 0x10c3,
	0x10a2, 0xffff, 0xffff, 0xffff, 0xffff, 0xffff, 0xffff, 0xffff, 0xffff, 0xffff, 0xffff, 0xffff, 0xffff, 0xffff, 0xffff, 0xffff,
	0xffff, 0x0d0a, 0x0d0a, 0x0d0a, 0xffff, 0xffff, 0xffff, 0x10a2, 0x10c3, 0x10c3, 0xffff, 0xffff, 0xffff, 0xffff, 0xffff, 0xffff,
	0xffff, 0xffff, 0xffff, 0xffff, 0xffff, 0xffff, 0x10c3, 0x10c3, 0x10c3, 0xffff, 0xffff, 0xffff, 0x0d0a, 0x0d0a, 0xffff, 0xffff,
	0xffff, 0xffff, 0xffff, 0xffff, 0xffff, 0xffff, 0xffff, 0xffff, 0xffff, 0xffff, 0xffff, 0xffff, 0xffff, 0xffff, 0xffff, 0x10a3,
	0x10c3, 0x10c3, 0xffff, 0xffff, 0xffff, 0xffff, 0x10a2, 0xffff, 0xffff, 0xffff, 0xffff, 0x0d2a, 0x0d0a, 0x0d0a, 0x0d0a, 0x0d0a,
	0x0d0a, 0x0d0a, 0x0d0a, 0x0d0a, 0x0d0a, 0x0d0a, 0x0d0a, 0x0d0a, 0x0d0a, 0x0d0a, 0x0d0a, 0x0d0a, 0x0d0a, 0x0d0a, 0x0d0a, 0x0d0a,
	0x0d0a, 0x0d0a, 0x0d0a, 0x0d0a, 0xffff, 0xffff, 0xffff, 0xffff, 0x0d0a, 0x0d0a, 0x0d0a, 0x0d0a, 0x0d0a, 0x0d0a, 0x0d0a, 0x0d0a,
	0x0d0a, 0x0d0a, 0x0d0a, 0x0d0a, 0x0d0a, 0x0d0a, 0x0d0a, 0x0d0a, 0xffff, 0xffff, 0xffff, 0xffff, 0x0d0a, 0x0d0a, 0x0d0a, 0x0d0a,
	0x0d0a, 0x0d0a, 0x0d0a, 0x0d0a, 0x0d0a, 0x0d0a, 0x0d0a, 0x0d0a, 0x0d0a, 0x0d0a, 0x0d0a, 0x0d0a, 0x0d0a, 0x0d0a, 0x0d0a, 0x0d0a,
	0x0d0a, 0x0d0a, 0x0d0a, 0x0d0a, 0x0d0a, 0xffff, 0xffff, 0xffff, 0xffff, 0x2124, 0x10c3, 0x10c3, 0x10c3, 0x10c3, 0x10a3, 0xffff,
	0xffff, 0xffff, 0xffff, 0xffff, 0xffff, 0xffff, 0xffff, 0xffff, 0xffff, 0xffff, 0xffff, 0xffff, 0xffff, 0xffff, 0xffff, 0xffff,
	0xffff, 0xffff, 0x0d0a, 0x0d0a, 0xdf9d, 0xffff, 0xffff, 0x2986, 0x10c3, 0x10c3, 0xffff, 0xffff, 0xffff, 0xffff, 0xffff, 0xffff,
	0xffff, 0xffff, 0xffff, 0xffff, 0xffff, 0x10c3, 0x10c3, 0x10c3, 0xffff, 0xffff, 0xffff, 0x0d0a, 0x0d0a, 0x0d0a, 0xffff, 0xffff,
	0xffff, 0xffff, 0xffff, 0xffff, 0xffff, 0xffff, 0xffff, 0xffff, 0xffff, 0xffff, 0xffff, 0xffff, 0xffff, 0xffff, 0xffff, 0xffff,
	0x10c3, 0x10c3, 0x10c3, 0xffff, 0xffff, 0xffff, 0xffff, 0xffff, 0xffff, 0xffff, 0x0d09, 0x0d0a, 0x0d0a, 0x0d0a, 0x0d0a, 0x0d0a,
	0x0d0a, 0x0d0a, 0x0d0a, 0x0d0a, 0x0d0a, 0x0d0a, 0x0d0a, 0x0d0a, 0x0d0a, 0x0d0a, 0x0d0a, 0x0d0a, 0x0d0a, 0x0d0a, 0x0d0a, 0x0d0a,
	0x0d0a, 0x0d0a, 0x0d0a, 0x0509, 0xffff, 0xffff, 0xffff, 0xffff, 0x0d0a, 0x0d0a, 0x0d0a, 0x0d0a, 0x0d0a, 0x0d0a, 0x0d0a, 0x0d0a,
	0x0d0a, 0x0d0a, 0x0d0a, 0x0d0a, 0x0d0a, 0x0d0a, 0x0d0a, 0x0d0a, 0xffff, 0xffff, 0xffff, 0xffff, 0x0d2a, 0x0d0a, 0x0d0a, 0x0d0a,
	0x0d0a, 0x0d0a, 0x0d0a, 0x0d0a, 0x0d0a, 0x0d0a, 0x0d0a, 0x0d0a, 0x0d0a, 0x0d0a, 0x0d0a, 0x0d0a, 0x0d0a, 0x0d0a, 0x0d0a, 0x0d0a,
	0x0d0a, 0x0d0a, 0x0d0a, 0x0d0a, 0x0d0a, 0x0509, 0xffff, 0xffff, 0xffff, 0xffff, 0x10c3, 0x10c3, 0x10c3, 0xffff, 0xffff, 0xffff,
	0xffff, 0xffff, 0xffff, 0xffff, 0xffff, 0xffff, 0xffff, 0xffff, 0x10a3, 0xffff, 0xffff, 0xffff, 0xffff, 0xffff, 0xffff, 0xffff,
	0xffff, 0xffff, 0x0d0a, 0x0d0a, 0x0d0a, 0xffff, 0xffff, 0xffff, 0x10c3, 0x10c3, 0x10c3, 0xffff, 0xffff, 0xffff, 0xffff, 0xffff,
	0xffff, 0xffff, 0xffff, 0xffff, 0xffff, 0x10c3, 0x10c3, 0x10c3, 0xffff, 0xffff, 0xffff, 0x0d0a, 0x0d0a, 0xffff, 0xffff, 0xffff,
	0xffff, 0xffff, 0xffff, 0xffff, 0xffff, 0xffff, 0xffff, 0xffff, 0xffff, 0xffff, 0xffff, 0xffff, 0xffff, 0xffff, 0xffff, 0xffff,
	0x10c3, 0x10c3, 0x10c3, 0xffff, 0xffff, 0xffff, 0xffff, 0xffff, 0xffff, 0x1d4b, 0x0d0a, 0x0d0a, 0x0d0a, 0x0d0a, 0x0d0a, 0x0d0a,
	0x0d0a, 0x0d0a, 0x0d0a, 0x0d0a, 0x0d0a, 0x0d0a, 0x0d0a, 0x0d0a, 0x0d0a, 0x0d0a, 0x0d0a, 0x0d0a, 0x0d0a, 0x0d0a, 0x0d0a, 0x0d0a,
	0x0d0a, 0x0d0a, 0x0d0a, 0xffff, 0xffff, 0xffff, 0xffff, 0xffff, 0x0529, 0x0d0a, 0x0d0a, 0x0d0a, 0x0d0a, 0x0d0a, 0x0d0a, 0x0d0a,
	0x0d0a, 0x0d0a, 0x0d0a, 0x0d0a, 0x0d0a, 0x0d0a, 0x0d0a, 0x0d09, 0xffff, 0xffff, 0xffff, 0xffff, 0xffff, 0x0d0a, 0x0d0a, 0x0d0a,
	0x0d0a, 0x0d0a, 0x0d0a, 0x0d0a, 0x0d0a, 0x0d0a, 0x0d0a, 0x0d0a, 0x0d0a, 0x0d0a, 0x0d0a, 0x0d0a, 0x0d0a, 0x0d0a, 0x0d0a, 0x0d0a,
	0x0d0a, 0x0d0a, 0x0d0a, 0x0d0a, 0x0d0a, 0x0d0a, 0x0d2a, 0xffff, 0xffff, 0xffff, 0xffff, 0xffff, 0xffff, 0xffff, 0xffff, 0xffff,
	0xffff, 0xffff, 0xffff, 0xffff, 0xffff, 0xffff, 0xffff, 0xffff, 0x10c3, 0x10c3, 0x10c3, 0xffff, 0xffff, 0xffff, 0xffff, 0xffff,
	0xffff, 0xffff, 0xffff, 0x0d0a, 0x0d0a, 0x5611, 0xffff, 0xffff, 0x6b6d, 0x10c3, 0x10c3, 0xffff, 0xffff, 0xffff, 0xffff, 0xffff,
	0xffff, 0xffff, 0xffff, 0xffff, 0x10c3, 0x10c3, 0x10c3, 0xffff, 0xffff, 0xffff, 0x0509, 0x0d0a, 0x0d2a, 0xffff, 0xffff, 0xffff,
	0xffff, 0xffff, 0xffff, 0xffff, 0xffff, 0xffff, 0xffff, 0xffff, 0xffff, 0xffff, 0xffff, 0xffff, 0xffff, 0xffff, 0xffff, 0xffff,
	0xffff, 0x10c3, 0x10c3, 0x10c3, 0xffff, 0xffff, 0xffff, 0xffff, 0xffff, 0x0d0a, 0x0d0a, 0x0d0a, 0x0d0a, 0x0d0a, 0x0d0a, 0x0d0a,
	0x0d0a, 0x0d0a, 0x0d0a, 0x0d0a, 0x0d0a, 0x0d0a, 0x0d0a, 0x0d0a, 0x0d0a, 0x0d0a, 0x0d0a, 0x0d0a, 0x0d0a, 0x0d0a, 0x0d0a, 0x0d0a,
	0x0d0a, 0x0d0a, 0x0d0a, 0xffff, 0xffff, 0xffff, 0xffff, 0xffff, 0xffff, 0x0d09, 0x0d0a, 0x0d0a, 0x0d0a, 0x0d0a, 0x0d0a, 0x0d0a,
	0x0d0a, 0x0d0a, 0x0d0a, 0x0d0a, 0x0d0a, 0x0d0a, 0x0d0a, 0xffff, 0xffff, 0xffff, 0xffff, 0xffff, 0xffff, 0x0d09, 0x0d0a, 0x0d0a,
	0x0d0a, 0x0d0a, 0x0d0a, 0x0d0a, 0x0d0a, 0x0d0a, 0x0d0a, 0x0d0a, 0x0d0a, 0x0d0a, 0x0d0a, 0x0d0a, 0x0d0a, 0x0d0a, 0x0d0a, 0x0d0a,
	0x0d0a, 0x0d0a, 0x0d0a, 0x0d0a, 0x0d0a, 0x0d0a, 0x0d0a, 0xffff, 0xffff, 0xffff, 0xffff, 0xffff, 0xffff, 0xffff, 0xffff, 0xffff,
	0x10c3, 0x10a2, 0x10c3, 0xffff, 0xffff, 0xffff, 0xffff, 0xffff, 0xffff, 0x10c3, 0x10c3, 0xffff, 0xffff, 0xffff, 0xffff, 0xffff,
	0xffff, 0xffff, 0xffff, 0x0d0a, 0x0d0a, 0x0d2a, 0xffff, 0xffff, 0xffff, 0x10c3, 0x10c3, 0x10c3, 0xffff, 0xffff, 0xffff, 0xffff,
	0xffff, 0xffff, 0xffff, 0xffff, 0x10c3, 0x10c3, 0x10c3, 0xffff, 0xffff, 0xffff, 0x0d0a, 0x0d0a, 0xffff, 0xffff, 0xffff, 0xffff,
	0xffff, 0xffff, 0xffff, 0xffff, 0xffff, 0xffff, 0xffff, 0xffff, 0xffff, 0xffff, 0xffff, 0xffff, 0xffff, 0xffff, 0xffff, 0xffff,
	0xffff, 0x10a3, 0x10c3, 0x10a2, 0xffff, 0xffff, 0xffff, 0xffff, 0x0d0a, 0x0d0a, 0x0d0a, 0x0d0a, 0x0d0a, 0x0d0a, 0x0d0a, 0x0d0a,
	0x0d0a, 0x0d0a, 0x0d0a, 0x0d0a, 0x0d0a, 0x0d0a, 0x0d0a, 0x0d0a, 0x0d0a, 0x0d0a, 0x0d0a, 0x0d0a, 0x0d0a, 0x0d0a, 0x0d0a, 0x0d0a,
	0x0d0a, 0x0d0a, 0x0d0a, 0xffff, 0xffff, 0xffff, 0xffff, 0xffff, 0xffff, 0x0d0a, 0x0d0a, 0x0d0a, 0x0d0a, 0x0d0a, 0x0d0a, 0x0d0a,
	0x0d0a, 0x0d0a, 0x0d0a, 0x0d0a, 0x0d0a, 0x0d0a, 0x0d0a, 0xffff, 0xffff, 0xffff, 0xffff, 0xffff, 0xffff, 0x050a, 0x0d0a, 0x0d0a,
	0x0d0a, 0x0d0a, 0x0d0a, 0x0d0a, 0x0d0a, 0x0d0a, 0x0d0a, 0x0d0a, 0x0d0a, 0x0d0a, 0x0d0a, 0x0d0a, 0x0d0a, 0x0d0a, 0x0d0a, 0x0d0a,
	0x0d0a, 0x0d0a, 0x0d0a, 0x0d0a, 0x0d0a, 0x0d0a, 0x0d0a, 0x0d0a, 0xffff, 0xffff, 0xffff, 0xffff, 0xffff, 0xffff, 0x5aec, 0x10c3,
	0x10c3, 0x10c3, 0x10c3, 0x10c3, 0x10a2, 0xffff, 0xffff, 0xffff, 0xffff, 0x10c3, 0x10c3, 0x10a2, 0xffff, 0xffff, 0xffff, 0xffff,
	0xffff, 0xffff, 0xffff, 0xffff, 0x0d09, 0x0d0a, 0xd77b, 0xffff, 0xffff, 0x10a3, 0x10c3, 0x10c3, 0xffff, 0xffff, 0xffff, 0xffff,
	0xffff, 0xffff, 0xffff, 0x10a2, 0x10c3, 0x10c3, 0xffff, 0xffff, 0xffff, 0x0d2a, 0x0d0a, 0x0d0a, 0xffff, 0xffff, 0xffff, 0xffff,
	0xffff, 0xffff, 0xffff, 0xffff, 0xffff, 0xffff, 0xffff, 0xc638, 0x10a3, 0x10a3, 0xc638, 0xffff, 0xffff, 0xffff, 0xffff, 0xffff,
	0xffff, 0xffff, 0x10c3, 0xffff, 0xffff, 0xffff, 0xffff, 0x0d0a, 0x0d0a, 0x0d0a, 0x0d0a, 0x0d0a, 0x0d0a, 0x0d0a, 0x0d0a, 0x0d0a,
	0x0d0a, 0x0d0a, 0x0d0a, 0x0d0a, 0x0d0a, 0x0d0a, 0x0d0a, 0x0d0a, 0x0d0a, 0x0d0a, 0x0d0a, 0x0d0a, 0x0d0a, 0x0d0a, 0x0d0a, 0x0d0a,
	0x0d0a, 0x0d0a, 0xc75a, 0xffff, 0xffff, 0xffff, 0xffff, 0xffff, 0xffff, 0x0d09, 0x0d0a, 0x0d0a, 0x0d0a, 0x0d0a, 0x0d0a, 0x0d0a,
	0x0d0a, 0x0d0a, 0x0d0a, 0x0d0a, 0x0d0a, 0x0d0a, 0x0d0a, 0xffff, 0xffff, 0xffff, 0xffff, 0xffff, 0xffff, 0xffff, 0x0d0a, 0x0d0a,
	0x0d0a, 0x0d0a, 0x0d0a, 0x0d0a, 0x0d0a, 0x0d0a, 0x0d0a, 0x0d0a, 0x0d0a, 0x0d0a, 0x0d0a, 0x0d0a, 0x0d0a, 0x0d0a, 0x0d0a, 0x0d0a,
	0x0d0a, 0x0d0a, 0x0d0a, 0x0d0a, 0x0d0a, 0x0d0a, 0x0d0a, 0x0d0a, 0x0d09, 0xffff, 0xffff, 0xffff, 0xffff, 0xffff, 0x10c3, 0x10c3,
	0x10c3, 0x10a2, 0x10c3, 0x10c3, 0x10c3, 0x10a2, 0xffff, 0xffff, 0xffff, 0x10a2, 0x10c3, 0x10c3, 0xffff, 0xffff, 0xffff, 0xffff,
	0xffff, 0xffff, 0xffff, 0xffff, 0x0d09, 0x0d0a, 0x0d0a, 0xffff, 0xffff, 0xffff, 0x10c3, 0x10c3, 0x10a2, 0xffff, 0xffff, 0xffff,
	0xffff, 0xffff, 0xffff, 0x10c3, 0x10c3, 0x10c3, 0xffff, 0xffff, 0xffff, 0x0d0a, 0x0d0a, 0x0d0a, 0xffff, 0xffff, 0xffff, 0xffff,
	0xffff, 0xffff, 0xffff, 0xffff, 0xffff, 0x10c3, 0x10c3, 0x10c3, 0x10c3, 0x10c3, 0x10c3, 0x10c3, 0x10c3, 0xffff, 0xffff, 0xffff,
	0xffff, 0xffff, 0xffff, 0xffff, 0xffff, 0xffff, 0xdf9d, 0x0d0a, 0x0d0a, 0x0d0a, 0x0d0a, 0x0d0a, 0x0d0a, 0x0d0a, 0x0d0a, 0x0d0a,
	0x0d0a, 0x0d0a, 0x0d0a, 0x0d0a, 0x0d0a, 0x0d0a, 0x0d0a, 0x0d0a, 0x0d0a, 0x0d0a, 0x0d0a, 0x0d0a, 0x0d0a, 0x0d0a, 0x0d0a, 0x0d0a,
	0x0d0a, 0x0d0a, 0xffff, 0xffff, 0xffff, 0xffff, 0xffff, 0xffff, 0xffff, 0xffff, 0x0d0a, 0x0d0a, 0x0d0a, 0x0d0a, 0x0d0a, 0x0d0a,
	0x0d0a, 0x0d0a, 0x0d0a, 0x0d0a, 0x0d0a, 0x0d0a, 0xc73a, 0xffff, 0xffff, 0xffff, 0xffff, 0xffff, 0xffff, 0xffff, 0x0d0a, 0x0d0a,
	0x0d0a, 0x0d0a, 0x0d0a, 0x0d0a, 0x0d0a, 0x0d0a, 0x0d0a, 0x0d0a, 0x0d0a, 0x0d0a, 0x0d0a, 0x0d0a, 0x0d0a, 0x0d0a, 0x0d0a, 0x0d0a,
	0x0d0a, 0x0d0a, 0x0d0a, 0x0d0a, 0x0d0a, 0x0d0a, 0x0d0a, 0x0d0a, 0x0d0a, 0x152b, 0xffff, 0xffff, 0xffff, 0xffff, 0x10c3, 0x10c3,
	0xffff, 0xffff, 0xffff, 0xffff, 0x10c3, 0x10c3, 0x10c3, 0x10c3, 0x10c3, 0x10c3, 0x10c3, 0x10c3, 0xffff, 0xffff, 0xffff, 0xffff,
	0xffff, 0xffff, 0xffff, 0xffff, 0xcf7b, 0x0d0a, 0x0d0a, 0xffff, 0xffff, 0xffff, 0x10c3, 0x10c3, 0x10c3, 0xffff, 0xffff, 0xffff,
	0xffff, 0xffff, 0xffff, 0x10c3, 0x10c3, 0x10a2, 0xffff, 0xffff, 0x8695, 0x0d0a, 0x0d0a, 0xffff, 0xffff, 0xffff, 0xffff, 0xffff,
	0xffff, 0xffff, 0xffff, 0x2124, 0x10c3, 0x10c3, 0x10c3, 0x10c3, 0x10c3, 0x10c3, 0x10c3, 0x10c3, 0x10c3, 0x10a3, 0x2124, 0xffff,
	0xffff, 0xffff, 0xffff, 0xffff, 0xffff, 0xffff, 0x0d0a, 0x0d0a, 0x0d0a, 0x0d0a, 0x0d0a, 0x0d0a, 0x0d0a, 0x0d0a, 0x0d0a, 0x0d0a,
	0x0d0a, 0x0d0a, 0x0d0a, 0x0d0a, 0x0d0a, 0x0d0a, 0x0d0a, 0x0d0a, 0x0d0a, 0x0d0a, 0x0d0a, 0x0d0a, 0x0d0a, 0x0d0a, 0x0d0a, 0x0d0a,
	0x0d0a, 0x0d0a, 0xffff, 0xffff, 0xffff, 0xffff, 0xffff, 0xffff, 0xffff, 0xffff, 0x0d0a, 0x0d0a, 0x0d0a, 0x0d0a, 0x0d0a, 0x0d0a,
	0x0d0a, 0x0d0a, 0x0d0a, 0x0d0a, 0x0d0a, 0x0d0a, 0xffff, 0xffff, 0xffff, 0xffff, 0xffff, 0xffff, 0xffff, 0xffff, 0x0d0a, 0x0d0a,
	0x0d0a, 0x0d0a, 0x0d0a, 0x0d0a, 0x0d0a, 0x0d0a, 0x0d0a, 0x0d0a, 0x0d0a, 0x0d0a, 0x0d0a, 0x0d0a, 0x0d0a, 0x0d0a, 0x0d0a, 0x0d0a,
	0x0d0a, 0x0d0a, 0x0d0a, 0x0d0a, 0x0d0a, 0x0d0a, 0x0d0a, 0x0d0a, 0x0d0a, 0x0d0a, 0xffff, 0xffff, 0xffff, 0xffff, 0x10c3, 0x10c3,
	0xffff, 0xffff, 0xffff, 0xffff, 0xffff, 0x10a2, 0x10c3, 0x10c3, 0x10c3, 0x10c3, 0x10c3, 0xffff, 0xffff, 0xffff, 0xffff, 0xffff,
	0xffff, 0xffff, 0xffff, 0xffff, 0xffff, 0x0d0a, 0x0d0a, 0x0d09, 0xffff, 0xffff, 0x2124, 0x10c3, 0x10c3, 0xffff, 0xffff, 0xffff,
	0xffff, 0xffff, 0x2124, 0x10c3, 0x10c3, 0xffff, 0xffff, 0xffff, 0x0d0a, 0x0d0a, 0x0d2a, 0xffff, 0xffff, 0xffff, 0xffff, 0xffff,
	0xffff, 0xffff, 0xe71c, 0x10c3, 0x10c3, 0x10c3, 0xffff, 0xffff, 0xffff, 0xffff, 0xffff, 0xf79e, 0x10a2, 0x10c3, 0x10c3, 0xffff,
	0xffff, 0xffff, 0xffff, 0xffff, 0xffff, 0x0d2a, 0x0d0a, 0x0d0a, 0x0d0a, 0x0d0a, 0x0d0a, 0x0d0a, 0x0d0a, 0x0d0a, 0x0d0a, 0x0d0a,
	0x0d0a, 0x0d0a, 0x0d0a, 0x0d0a, 0x0d0a, 0x0d0a, 0x0d0a, 0x0d0a, 0x0d0a, 0x0d0a, 0x0d0a, 0x0d0a, 0x0d0a, 0x0d0a, 0x0d0a, 0x0d0a,
	0x0d0a, 0x4dcf, 0xffff, 0xffff, 0xffff, 0xffff, 0xffff, 0xffff, 0xffff, 0xffff, 0x0d0a, 0x0d0a, 0x0d0a, 0x0d0a, 0x0d0a, 0x0d0a,
	0x0d0a, 0x0d0a, 0x0d0a, 0x0d0a, 0x0d0a, 0x0d09, 0xffff, 0xffff, 0xffff, 0xffff, 0xffff, 0xffff, 0xffff, 0xffff, 0xffff, 0x0d0a,
	0x0d0a, 0x0d0a, 0x0d0a, 0x0d0a, 0x0d0a, 0x0d0a, 0x0d0a, 0x0d0a, 0x0d0a, 0x0d0a, 0x0d0a, 0x0d0a, 0x0d0a, 0x0d0a, 0x0d0a, 0x0d0a,
	0x0d0a, 0x0d0a, 0x0d0a, 0x0d0a, 0x0d0a, 0x0d0a, 0x0d0a, 0x0d0a, 0x0d0a, 0x0d0a, 0x0509, 0xffff, 0xffff, 0xffff, 0x10a2, 0x10c3,
	0x10a2, 0xffff, 0xffff, 0xffff, 0xffff, 0xffff, 0xffff, 0xffff, 0x4a8a, 0xffff, 0xffff, 0xffff, 0xffff, 0xffff, 0xffff, 0xffff,
	0xffff, 0xffff, 0xffff, 0xffff, 0xffff, 0x0d0a, 0x0d0a, 0x0d0a, 0xffff, 0xffff, 0xffff, 0x10a2, 0x10c3, 0x10a3, 0xffff, 0xffff,
	0xffff, 0xffff, 0x10c3, 0x10c3, 0x10c3, 0xffff, 0xffff, 0xffff, 0x0d0a, 0x0d0a, 0xffff, 0xffff, 0xffff, 0xffff, 0xffff, 0xffff,
	0xffff, 0xffff, 0x10a3, 0x10c3, 0x10a3, 0xffff, 0xffff, 0xffff, 0xffff, 0xffff, 0xffff, 0xffff, 0xffff, 0x10c3, 0x10c3, 0x10c3,
	0xffff, 0xffff, 0xffff, 0xffff, 0xffff, 0x0d0a, 0x0d0a, 0x0d0a, 0x0d0a, 0x0d0a, 0x0d0a, 0x0d0a, 0x0d0a, 0x0d0a, 0x0d0a, 0x0d0a,
	0x0d0a, 0x0d0a, 0x0d0a, 0x0d0a, 0x0d0a, 0x0d0a, 0x0d0a, 0x0d0a, 0x0d0a, 0x0d0a, 0x0d0a, 0x0d0a, 0x0d0a, 0x0d0a, 0x0d0a, 0x0d0a,
	0x0d0a, 0xffff, 0xffff, 0xffff, 0xffff, 0xffff, 0xffff, 0xffff, 0xffff, 0xffff, 0x35ae, 0x0d0a, 0x0d0a, 0x0d0a, 0x0d0a, 0x0d0a,
	0x0d0a, 0x0d0a, 0x0d0a, 0x0d0a, 0x0d0a, 0x0d2a, 0xffff, 0xffff, 0xffff, 0xffff, 0xffff, 0xffff, 0xffff, 0xffff, 0xffff, 0x0d0a,
	0x0d0a, 0x0d0a, 0x0d0a, 0x0d0a, 0x0d0a, 0x0d0a, 0x0d0a, 0x0d0a, 0x0d0a, 0x0d0a, 0x0d0a, 0x0d0a, 0x0d0a, 0x0d0a, 0x0d0a, 0x0d0a,
	0x0d0a, 0x0d0a, 0x0d0a, 0x0d0a, 0x0d0a, 0x0d0a, 0x0d0a, 0x0d0a, 0x0d0a, 0x0d0a, 0x0d0a, 0xffff, 0xffff, 0xffff, 0xffff, 0x10a2,
	0x10c3, 0x10c3, 0x10c3, 0xffff, 0xffff, 0xffff, 0xffff, 0xffff, 0xffff, 0xffff, 0xffff, 0xffff, 0xffff, 0xffff, 0xffff, 0xffff,
	0xffff, 0xffff, 0xffff, 0xffff, 0xffff, 0xffff, 0x0d0a, 0x0d0a, 0xffff, 0xffff, 0xffff, 0x10a3, 0x10c3, 0x10c3, 0xffff, 0xffff,
	0xffff, 0xffff, 0x10c3, 0x10c3, 0x10c3, 0xffff, 0xffff, 0x6631, 0x0d0a, 0x0d0a, 0xffff, 0xffff, 0xffff, 0xffff, 0xffff, 0xffff,
	0xffff, 0xffff, 0x10a3, 0x10c3, 0xffff, 0xffff, 0xffff, 0xffff, 0xffff, 0xffff, 0xffff, 0xffff, 0xffff, 0x5aeb, 0x10c3, 0x10c3,
	0xffff, 0xffff, 0xffff, 0xffff, 0x050a, 0x0d0a, 0x0d0a, 0x0d0a, 0x0d0a, 0x0d0a, 0x0d0a, 0x0d0a, 0x0d0a, 0x0d0a, 0x0d0a, 0x0d0a,
	0x0d0a, 0x0d0a, 0x0d0a, 0x0d0a, 0x0d0a, 0x0d0a, 0x0d0a, 0x0d0a, 0x0d0a, 0x0d0a, 0x0d0a, 0x0d0a, 0x0d0a, 0x0d0a, 0x0d0a, 0x0d0a,
	0x0d0a, 0xffff, 0xffff, 0xffff, 0xffff, 0xffff, 0xffff, 0xffff, 0xffff, 0xffff, 0xffff, 0x0d0a, 0x0d0a, 0x0d0a, 0x0d0a, 0x0d0a,
	0x0d0a, 0x0d0a, 0x0d0a, 0x0d0a, 0x0d0a, 0xffff, 0xffff, 0xffff, 0xffff, 0xffff, 0xffff, 0xffff, 0xffff, 0xffff, 0xffff, 0x0d0a,
	0x0d0a, 0x0d0a, 0x0d0a, 0x0d0a, 0x0d0a, 0x0d0a, 0x0d0a, 0x0d0a, 0x0d0a, 0x0d0a, 0x0d0a, 0x0d0a, 0x0d0a, 0x0d0a, 0x0d0a, 0x0d0a,
	0x0d0a, 0x0d0a, 0x0d0a, 0x0d0a, 0x0d0a, 0x0d0a, 0x0d0a, 0x0d0a, 0x0d0a, 0x0d0a, 0x0d0a, 0x0d2a, 0xffff, 0xffff, 0xffff, 0xffff,
	0x10c3, 0x10c3, 0xffff, 0xffff, 0xffff, 0xffff, 0xffff, 0xffff, 0xffff, 0xffff, 0xffff, 0xffff, 0xffff, 0xffff, 0xffff, 0xffff,
	0xffff, 0xffff, 0xffff, 0xffff, 0xffff, 0xffff, 0x0d0a, 0x0d0a, 0x0d09, 0xffff, 0xffff, 0x10a3, 0x10c3, 0x10c3, 0xffff, 0xffff,
	0xffff, 0xffff, 0x10c3, 0x10c3, 0xffff, 0xffff, 0xffff, 0x0d0a, 0x0d0a, 0x0d0a, 0xffff, 0xffff, 0xffff, 0xffff, 0xffff, 0xffff,
	0xffff, 0xffff, 0x10c3, 0x10c3, 0xffff, 0xffff, 0xffff, 0xffff, 0xffff, 0xffff, 0xffff, 0xffff, 0xffff, 0xffff, 0x10c3, 0x10c3,
	0xffff, 0xffff, 0xffff, 0xffff, 0x0d0a, 0x0d0a, 0x0d0a, 0x0d0a, 0x0d0a, 0x0d0a, 0x0d0a, 0x0d0a, 0x0d0a, 0x0d0a, 0x0d0a, 0x0d0a,
	0x0d0a, 0x0d0a, 0x0d0a, 0x0d0a, 0x0d0a, 0x0d0a, 0x0d0a, 0x0d0a, 0x0d0a, 0x0d0a, 0x0d0a, 0x0d0a, 0x0d0a, 0x0d0a, 0x0d0a, 0x0d0a,
	0x052a, 0xffff, 0xffff, 0xffff, 0xffff, 0xffff, 0xffff, 0xffff, 0xffff, 0xffff, 0xffff, 0x0d2a, 0x0d0a, 0x0d0a, 0x0d0a, 0x0d0a,
	0x0d0a, 0x0d0a, 0x0d0a, 0x0d0a, 0x0d0a, 0xffff, 0xffff, 0xffff, 0xffff, 0xffff, 0xffff, 0xffff, 0xffff, 0xffff, 0xffff, 0x0509,
	0x0d0a, 0x0d0a, 0x0d0a, 0x0d0a, 0x0d0a, 0x0d0a, 0x0d0a, 0x0d0a, 0x0d0a, 0x0d0a, 0x0d0a, 0x0d0a, 0x0d0a, 0x0d0a, 0x0d0a, 0x0d0a,
	0x0d0a, 0x0d0a, 0x0d0a, 0x0d0a, 0x0d0a, 0x0d0a, 0x0d0a, 0x0d0a, 0x0d0a, 0x0d0a, 0x0d0a, 0x0d0a, 0xffff, 0xffff, 0xffff, 0xffff,
	0xffff, 0xffff, 0xffff, 0xffff, 0xffff, 0xffff, 0xffff, 0xffff, 0xffff, 0xffff, 0xffff, 0xffff, 0xffff, 0xffff, 0x2124, 0xffff,
	0xffff, 0xffff, 0xffff, 0xffff, 0xffff, 0xffff, 0x0d0a, 0x0d0a, 0x0d0a, 0xffff, 0xffff, 0xffff, 0x10c3, 0x10c3, 0x8c51, 0xffff,
	0xffff, 0x10c3, 0x10c3, 0x10c3, 0xffff, 0xffff, 0xffff, 0x0d0a, 0x0d0a, 0x4dcf, 0xffff, 0xffff, 0xffff, 0xffff, 0xffff, 0xffff,
	0xffff, 0xffff, 0x10a2, 0x10c3, 0x10a3, 0xffff, 0xffff, 0xffff, 0xffff, 0xffff, 0xffff, 0xffff, 0xffff, 0x10c3, 0x10c3, 0x10c3,
	0xffff, 0xffff, 0xffff, 0x0d0a, 0x0d0a, 0x0d0a, 0x0d0a, 0x0d0a, 0x0d0a, 0x0d0a, 0x0d0a, 0x0d0a, 0x0d0a, 0x0d0a, 0x0d0a, 0x0d0a,
	0x0d0a, 0x0d0a, 0x0d0a, 0x0d0a, 0x0d0a, 0x0d0a, 0x0d0a, 0x0d0a, 0x0d0a, 0x0d0a, 0x0d0a, 0x0d0a, 0x0d0a, 0x0d0a, 0x0d0a, 0x0d0a,
	0xffff, 0xffff, 0xffff, 0xffff, 0xffff, 0xffff, 0xffff, 0xffff, 0xffff, 0xffff, 0xffff, 0x0509, 0x0d0a, 0x0d0a, 0x0d0a, 0x0d0a,
	0x0d0a, 0x0d0a, 0x0d0a, 0x0d0a, 0x0d09, 0xffff, 0xffff, 0xffff, 0xffff, 0xffff, 0xffff, 0xffff, 0xffff, 0xffff, 0xffff, 0xffff,
	0x0d0a, 0x0d0a, 0x0d0a, 0x0d0a, 0x0d0a, 0x0d0a, 0x0d0a, 0x0d0a, 0x0d0a, 0x0d0a, 0x0d0a, 0x0d0a, 0x0d0a, 0x0d0a, 0x0d0a, 0x0d0a,
	0x0d0a, 0x0d0a, 0x0d0a, 0x0d0a, 0x0d0a, 0x0d0a, 0x0d0a, 0x0d0a, 0x0d0a, 0x0d0a, 0x0d0a, 0x0d0a, 0x0d0a, 0xffff, 0xffff, 0xffff,
	0xffff, 0xffff, 0xffff, 0xffff, 0xffff, 0xffff, 0xffff, 0x10c3, 0x10c3, 0xffff, 0xffff, 0xffff, 0x10a3, 0x10c3, 0x10c3, 0xffff,
	0xffff, 0xffff, 0xffff, 0xffff, 0xffff, 0xffff, 0xffff, 0x0d0a, 0x0d09, 0xffff, 0xffff, 0xffff, 0x10c3, 0x10c3, 0x10c3, 0xffff,
	0xffff, 0x10a2, 0x10c3, 0x10a2, 0xffff, 0xffff, 0xffff, 0x0d0a, 0x0d0a, 0xffff, 0xffff, 0xffff, 0xffff, 0xffff, 0xffff, 0xffff,
	0xffff, 0xffff, 0x10a2, 0x10c3, 0x10c3, 0xffff, 0xffff, 0xffff, 0xffff, 0xffff, 0xffff, 0xffff, 0xffff, 0x10c3, 0x10c3, 0x10a2,
	0xffff, 0xffff, 0xffff, 0x0d0a, 0x0d0a, 0x0d0a, 0x0d0a, 0x0d0a, 0x0d0a, 0x0d0a, 0x0d0a, 0x0d0a, 0x0d0a, 0x0d0a, 0x0d0a, 0x0d0a,
	0x0d0a, 0x0d0a, 0x0d0a, 0x0d0a, 0x0d0a, 0x0d0a, 0x0d0a, 0x0d0a, 0x0d0a, 0x0d0a, 0x0d0a, 0x0d0a, 0x0d0a, 0x0d0a, 0x0d0a, 0x0d0a,
	0xffff, 0xffff, 0xffff, 0xffff, 0xffff, 0xffff, 0xffff, 0xffff, 0xffff, 0xffff, 0xffff, 0xffff, 0x0d0a, 0x0d0a, 0x0d0a, 0x0d0a,
	0x0d0a, 0x0d0a, 0x0d0a, 0x0d0a, 0xffff, 0xffff, 0xffff, 0xffff, 0xffff, 0xffff, 0xffff, 0xffff, 0xffff, 0xffff, 0xffff, 0xffff,
	0x0509, 0x0d0a, 0x0d0a, 0x0d0a, 0x0d0a, 0x0d0a, 0x0d0a, 0x0d0a, 0x0d0a, 0x0d0a, 0x0d0a, 0x0d0a, 0x0d0a, 0x0d0a, 0x0d0a, 0x0d0a,
	0x0d0a, 0x0d0a, 0x0d0a, 0x0d0a, 0x0d0a, 0x0d0a, 0x0d0a, 0x0d0a, 0x0d0a, 0x0d0a, 0x0d0a, 0x0d0a, 0x0d0a, 0xffff, 0xffff, 0xffff,
	0xffff, 0x10a2, 0x10a3, 0x8c51, 0xffff, 0xffff, 0xffff, 0x10c3, 0x10c3, 0x10a2, 0xffff, 0xffff, 0x4a8a, 0x10c3, 0x10c3, 0xffff,
	0xffff, 0xffff, 0xffff, 0xffff, 0xffff, 0xffff, 0xffff, 0x0d0a, 0x0d0a, 0xffff, 0xffff, 0xffff, 0x10c3, 0x10c3, 0x10c3, 0xffff,
	0xffff, 0x10a3, 0x10c3, 0x10c3, 0xffff, 0xffff, 0x35ae, 0x0d0a, 0x0d0a, 0xffff, 0xffff, 0xffff, 0xffff, 0xffff, 0xffff, 0xffff,
	0xffff, 0xffff, 0xffff, 0x10c3, 0x10c3, 0x10c3, 0x10a3, 0xef9e, 0xffff, 0xffff, 0xffff, 0x10a2, 0x10c3, 0x10c3, 0x10c3, 0xffff,
	0xffff, 0xffff, 0xffff, 0x0d0a, 0x0d0a, 0x0d0a, 0x0d0a, 0x0d0a, 0x0d0a, 0x0d0a, 0x0d0a, 0x0d0a, 0x0d0a, 0x0d0a, 0x0d0a, 0x0d0a,
	0x0d0a, 0x0d0a, 0x0d0a, 0x0d0a, 0x0d0a, 0x0d0a, 0x0d0a, 0x0d0a, 0x0d0a, 0x0d0a, 0x0d0a, 0x0d0a, 0x0d0a, 0x0d0a, 0x0d0a, 0x0d0a,
	0xffff, 0xffff, 0xffff, 0xffff, 0xffff, 0xffff, 0xffff, 0xffff, 0xffff, 0xffff, 0xffff, 0xffff, 0x0d2a, 0x0d0a, 0x0d0a, 0x0d0a,
	0x0d0a, 0x0d0a, 0x0d0a, 0x0d0a, 0xffff, 0xffff, 0xffff, 0xffff, 0xffff, 0xffff, 0xffff, 0xffff, 0xffff, 0xffff, 0xffff, 0xffff,
	0x0d09, 0x0d0a, 0x0d0a, 0x0d0a, 0x0d0a, 0x0d0a, 0x0d0a, 0x0d0a, 0x0d0a, 0x0d0a, 0x0d0a, 0x0d0a, 0x0d0a, 0x0d0a, 0x0d0a, 0x0d0a,
	0x0d0a, 0x0d0a, 0x0d0a, 0x0d0a, 0x0d0a, 0x0d0a, 0x0d0a, 0x0d0a, 0x0d0a, 0x0d0a, 0x0d0a, 0x0d0a, 0x0d0a, 0xa6d7, 0xffff, 0xffff,
	0xffff, 0x10c3, 0x10c3, 0x10c3, 0xffff, 0xffff, 0xffff, 0x10c3, 0x10c3, 0x10c3, 0xffff, 0xffff, 0xffff, 0x10c3, 0x10c3, 0xffff,
	0xffff, 0xffff, 0xffff, 0xffff, 0xffff, 0xffff, 0xffff, 0x0d2a, 0x0d0a, 0x0d09, 0xffff, 0xffff, 0x10a3, 0x10c3, 0x10c3, 0xffff,
	0xffff, 0x10c3, 0x10c3, 0xc638, 0xffff, 0xffff, 0x0d09, 0x0d0a, 0x0d0a, 0xffff, 0xffff, 0xffff, 0xffff, 0xffff, 0xffff, 0xffff,
	0xffff, 0xffff, 0xffff, 0xffff, 0x10c3, 0x10c3, 0x10c3, 0x10c3, 0x10c3, 0x10c3, 0x10c3, 0x10c3, 0x10c3, 0x10a3, 0xffff, 0xffff,
	0xffff, 0xffff, 0x0d29, 0x0d0a, 0x0d0a, 0x0d0a, 0x0d0a, 0x0d0a, 0x0d0a, 0x0d0a, 0x0d0a, 0x0d0a, 0x0d0a, 0x0d0a, 0x0d0a, 0x0d0a,
	0x0d0a, 0x0d0a, 0x0d0a, 0x0d0a, 0x0d0a, 0x0d0a, 0x0d0a, 0x0d0a, 0x0d0a, 0x0d0a, 0x0d0a, 0x0d0a, 0x0d0a, 0x0d0a, 0x0d0a, 0xffff,
	0xffff, 0xffff, 0xffff, 0xffff, 0xffff, 0xffff, 0xffff, 0xffff, 0xffff, 0xffff, 0xffff, 0xffff, 0x0d09, 0x0d0a, 0x0d0a, 0x0d0a,
	0x0d0a, 0x0d0a, 0x0d0a, 0x0d0a, 0xffff, 0xffff, 0xffff, 0xffff, 0xffff, 0xffff, 0xffff, 0xffff, 0xffff, 0xffff, 0xffff, 0xffff,
	0xffff, 0x0d0a, 0x0d0a, 0x0d0a, 0x0d0a, 0x0d0a, 0x0d0a, 0x0d0a, 0x0d0a, 0x0d0a, 0x0d0a, 0x0d0a, 0x0d0a, 0x0d0a, 0x0d0a, 0x0d0a,
	0x0d0a, 0x0d0a, 0x0d0a, 0x0d0a, 0x0d0a, 0x0d0a, 0x0d0a, 0x0d0a, 0x0d0a, 0x0d0a, 0x0d0a, 0x0d0a, 0x0d0a, 0x0d2a, 0xffff, 0xffff,
	0xffff, 0x10c3, 0x10c3, 0x10c3, 0xffff, 0xffff, 0xffff, 0x8451, 0x10c3, 0x10c3, 0xffff, 0xffff, 0xffff, 0x10a2, 0x10c3, 0x8c51,
	0xffff, 0xffff, 0xffff, 0xffff, 0xffff, 0xffff, 0xffff, 0x0d0a, 0x0d0a, 0x0d2a, 0xffff, 0xffff, 0xffff, 0x10c3, 0x10c3, 0xffff,
	0xffff, 0x10c3, 0x10c3, 0xffff, 0xffff, 0xffff, 0x0d0a, 0x0d0a, 0x0d0a, 0xffff, 0xffff, 0xffff, 0xffff, 0xffff, 0xffff, 0xffff,
	0xffff, 0xffff, 0xffff, 0xffff, 0xffff, 0x4a8a, 0x10c3, 0x10c3, 0x10c3, 0x10c3, 0x10c3, 0x10c3, 0xffff, 0xffff, 0xffff, 0xffff,
	0xffff, 0xffff, 0x0d09, 0x0d0a, 0x0d0a, 0x0d0a, 0x0d0a, 0x0d0a, 0x0d0a, 0x0d0a, 0x0d0a, 0x0d0a, 0x0d0a, 0x0d0a, 0x0d0a, 0x0d0a,
	0x0d0a, 0x0d0a, 0x0d0a, 0x0d0a, 0x0d0a, 0x0d0a, 0x0d0a, 0x0d0a, 0x0d0a, 0x0d0a, 0x0d0a, 0x0d0a, 0x0d0a, 0x0d0a, 0x0d0a, 0xffff,
	0xffff, 0xffff, 0xffff, 0xffff, 0xffff, 0xffff, 0xffff, 0xffff, 0xffff, 0xffff, 0xffff, 0xffff, 0xffff, 0x0d0a, 0x0d0a, 0x0d0a,
	0x0d0a, 0x0d0a, 0x0d0a, 0xffff, 0xffff, 0xffff, 0xffff, 0xffff, 0xffff, 0xffff, 0xffff, 0xffff, 0xffff, 0xffff, 0xffff, 0xffff,
	0xffff, 0x0d0a, 0x0d0a, 0x0d0a, 0x0d0a, 0x0d0a, 0x0d0a, 0x0d0a, 0x0d0a, 0x0d0a, 0x0d0a, 0x0d0a, 0x0d0a, 0x0d0a, 0x0d0a, 0x0d0a,
	0x0d0a, 0x0d0a, 0x0d0a, 0x0d0a, 0x0d0a, 0x0d0a, 0x0d0a, 0x0d0a, 0x0d0a, 0x0d0a, 0x0d0a, 0x0d0a, 0x0d0a, 0x0d0a, 0xffff, 0xffff,
	0xffff, 0xffff, 0x10c3, 0x10c3, 0xffff, 0xffff, 0xffff, 0xffff, 0x10c3, 0x10c3, 0x10a3, 0x10c3, 0x10c3, 0x10c3, 0x10c3, 0x10c3,
	0xffff, 0xffff, 0xffff, 0xffff, 0xffff, 0xffff, 0xffff, 0x0d2a, 0x0d0a, 0x0d0a, 0xffff, 0xffff, 0xffff, 0x10c3, 0x10c3, 0x4a8a,
	0x10a2, 0x10c3, 0x10c3, 0xffff, 0xffff, 0xffff, 0x0d0a, 0x0d0a, 0x050a, 0xffff, 0xffff, 0xffff, 0xffff, 0xffff, 0xffff, 0xffff,
	0xffff, 0xffff, 0xffff, 0xffff, 0xffff, 0xffff, 0xffff, 0xffff, 0xffff, 0xffff, 0xffff, 0xffff, 0xffff, 0xffff, 0xffff, 0xffff,
	0xffff, 0xffff, 0x0d0a, 0x0d0a, 0x0d0a, 0x0d0a, 0x0d0a, 0x0d0a, 0x0d0a, 0x0d0a, 0x0d0a, 0x0d0a, 0x0d0a, 0x0d0a, 0x0d0a, 0x0d0a,
	0x0d0a, 0x0d0a, 0x0d0a, 0x0d0a, 0x0d0a, 0x0d0a, 0x0d0a, 0x0d0a, 0x0d0a, 0x0d0a, 0x0d0a, 0x0d0a, 0x0d0a, 0x0d0a, 0x0d2a, 0xffff,
	0xffff, 0xffff, 0xffff, 0xffff, 0xffff, 0xffff, 0xffff, 0xffff, 0xffff, 0xffff, 0xffff, 0xffff, 0xffff, 0x0d0a, 0x0d0a, 0x0d0a,
	0x0d0a, 0x0d0a, 0x0d0a, 0xffff, 0xffff, 0xffff, 0xffff, 0xffff, 0xffff, 0xffff, 0xffff, 0xffff, 0xffff, 0xffff, 0xffff, 0xffff,
	0xffff, 0x0d0a, 0x0d0a, 0x0d0a, 0x0d0a, 0x0d0a, 0x0d0a, 0x0d0a, 0x0d0a, 0x0d0a, 0x0d0a, 0x0d0a, 0x0d0a, 0x0d0a, 0x0d0a, 0x0d0a,
	0x0d0a, 0x0d0a, 0x0d0a, 0x0d0a, 0x0d0a, 0x0d0a, 0x0d0a, 0x0d0a, 0x0d0a, 0x0d0a, 0x0d0a, 0x0d0a, 0x0d0a, 0x0d0a, 0xffff, 0xffff,
	0xffff, 0xffff, 0x10c3, 0x10c3, 0x10c3, 0x10c3, 0x10c3, 0x10c3, 0x10c3, 0x10c3, 0x10c3, 0x10c3, 0x10c3, 0x10c3, 0x10a3, 0x10c3,
	0xffff, 0xffff, 0xffff, 0xffff, 0xffff, 0xffff, 0xffff, 0x55f0, 0x0d0a, 0x0d0a, 0xffff, 0xffff, 0xffff, 0x10c3, 0x10c3, 0x10a3,
	0x10a3, 0x10c3, 0x10a3, 0xffff, 0xffff, 0xffff, 0x0d0a, 0x0d0a, 0xc73a, 0xffff, 0xffff, 0xffff, 0xffff, 0xffff, 0xffff, 0xffff,
	0xffff, 0xffff, 0xffff, 0xffff, 0xffff, 0xffff, 0xffff, 0xffff, 0xffff, 0xffff, 0xffff, 0xffff, 0xffff, 0xffff, 0xffff, 0xffff,
	0xffff, 0xffff, 0x0d0a, 0x0d0a, 0x0d0a, 0x0d0a, 0x0d0a, 0x0d0a, 0x0d0a, 0x0d0a, 0x0d0a, 0x0d0a, 0x0d0a, 0x0d0a, 0x0d0a, 0x0d0a,
	0x0d0a, 0x0d0a, 0x0d0a, 0x0d0a, 0x0d0a, 0x0d0a, 0x0d0a, 0x0d0a, 0x0d0a, 0x0d0a, 0x0d0a, 0x0d0a, 0x0d0a, 0x0d0a, 0x96b6, 0xffff,
	0xffff, 0xffff, 0xffff, 0xffff, 0xffff, 0xffff, 0xffff, 0xffff, 0xffff, 0xffff, 0xffff, 0xffff, 0xffff, 0x0d0a, 0x0d0a, 0x0d0a,
	0x0d0a, 0x0d0a, 0x0d0a, 0xffff, 0xffff, 0xffff, 0xffff, 0xffff, 0xffff, 0xffff, 0xffff, 0xffff, 0xffff, 0xffff, 0xffff, 0xffff,
	0xffff, 0xffff, 0x0d0a, 0x0d0a, 0x0d0a, 0x0d0a, 0x0d0a, 0x0d0a, 0x0d0a, 0x0d0a, 0x0d0a, 0x0d0a, 0x0d0a, 0x0d0a, 0x0d0a, 0x0d0a,
	0x0d0a, 0x0d0a, 0x0d0a, 0x0d0a, 0x0d0a, 0x0d0a, 0x0d0a, 0x0d0a, 0x0d0a, 0x0d0a, 0x0d0a, 0x0d0a, 0x0d0a, 0x0d0a, 0x45cf, 0xffff,
	0xffff, 0xffff, 0x10a3, 0x10c3, 0x10c3, 0x10c3, 0x10c3, 0x10c3, 0x10c3, 0x10c3, 0x10c3, 0x10c3, 0xffff, 0xffff, 0xffff, 0xffff,
	0xffff, 0xffff, 0xffff, 0xffff, 0xffff, 0xffff, 0xffff, 0xffff, 0x0d0a, 0x0d0a, 0xffff, 0xffff, 0xffff, 0x10c3, 0x10c3, 0x10a3,
	0x10a2, 0x10c3, 0x10c3, 0xffff, 0xffff, 0xffff, 0x0d0a, 0x0d0a, 0xffff, 0xffff, 0xffff, 0xffff, 0xffff, 0xffff, 0xffff, 0xffff,
	0xffff, 0xffff, 0xffff, 0xffff, 0xffff, 0xffff, 0xffff, 0xffff, 0xffff, 0xffff, 0xffff, 0xffff, 0xffff, 0xffff, 0xffff, 0xffff,
	0xffff, 0x0d2a, 0x0d0a, 0x0d0a, 0x0d0a, 0x0d0a, 0x0d0a, 0x0d0a, 0x0d0a, 0x0d0a, 0x0d0a, 0x0d0a, 0x0d0a, 0x0d0a, 0x0d0a, 0x0d0a,
	0x0d0a, 0x0d0a, 0x0d0a, 0x0d0a, 0x0d0a, 0x0d0a, 0x0d0a, 0x0d0a, 0x0d0a, 0x0d0a, 0x0d0a, 0x0d0a, 0x0d0a, 0x0d0a, 0xffff, 0xffff,
	0xffff, 0xffff, 0xffff, 0xffff, 0xffff, 0xffff, 0xffff, 0xffff, 0xffff, 0xffff, 0xffff, 0xffff, 0xffff, 0x8694, 0x0d0a, 0x0d0a,
	0x0d0a, 0x0d0a, 0x0d0a, 0xffff, 0xffff, 0xffff, 0xffff, 0xffff, 0xffff, 0xffff, 0xffff, 0xffff, 0xffff, 0xffff, 0xffff, 0xffff,
	0xffff, 0xffff, 0x0d0a, 0x0d0a, 0x0d0a, 0x0d0a, 0x0d0a, 0x0d0a, 0x0d0a, 0x0d0a, 0x0d0a, 0x0d0a, 0x0d0a, 0x0d0a, 0x0d0a, 0x0d0a,
	0x0d0a, 0x0d0a, 0x0d0a, 0x0d0a, 0x0d0a, 0x0d0a, 0x0d0a, 0x0d0a, 0x0d0a, 0x0d0a, 0x0d0a, 0x0d0a, 0x0d0a, 0x0d0a, 0x0d2a, 0xffff,
	0xffff, 0xffff, 0x10c3, 0x10a2, 0x10a2, 0xffff, 0xffff, 0xffff, 0xffff, 0xffff, 0xffff, 0xffff, 0xffff, 0xffff, 0xffff, 0xffff,
	0xffff, 0xffff, 0xffff, 0xffff, 0xffff, 0xffff, 0xffff, 0xffff, 0x0d0a, 0x0d0a, 0xffff, 0xffff, 0xffff, 0x10a3, 0x10c3, 0x10c3,
	0x10a2, 0x10c3, 0x10c3, 0xffff, 0xffff, 0xffff, 0x0d0a, 0x0d0a, 0xffff, 0xffff, 0xffff, 0xffff, 0xffff, 0xffff, 0xffff, 0xffff,
	0xffff, 0xffff, 0xffff, 0xffff, 0xffff, 0x10a2, 0x10a3, 0x10c3, 0xef9e, 0xffff, 0xffff, 0xffff, 0xffff, 0xffff, 0xffff, 0xffff,
	0xffff, 0x0d09, 0x0d0a, 0x0d0a, 0x0d0a, 0x0d0a, 0x0d0a, 0x0d0a, 0x0d0a, 0x0d0a, 0x0d0a, 0x0d0a, 0x0d0a, 0x0d0a, 0x0d0a, 0x0d0a,
	0x0d0a, 0x0d0a, 0x0d0a, 0x0d0a, 0x0d0a, 0x0d0a, 0x0d0a, 0x0d0a, 0x0d0a, 0x0d0a, 0x0d0a, 0x0d0a, 0x0d0a, 0x0d0a, 0xffff, 0xffff,
	0xffff, 0xffff, 0xffff, 0xffff, 0xffff, 0xffff, 0xffff, 0xffff, 0xffff, 0xffff, 0xffff, 0xffff, 0xffff, 0xffff, 0x0d0a, 0x0d0a,
	0x0d0a, 0x0d0a, 0xffff, 0xffff, 0xffff, 0xffff, 0xffff, 0xffff, 0xffff, 0xffff, 0xffff, 0xffff, 0xffff, 0xffff, 0xffff, 0xffff,
	0xffff, 0xffff, 0x0d0a, 0x0d0a, 0x0d0a, 0x0d0a, 0x0d0a, 0x0d0a, 0x0d0a, 0x0d0a, 0x0d0a, 0x0d0a, 0x0d0a, 0x0d0a, 0x0d0a, 0x0d0a,
	0x0d0a, 0x0d0a, 0x0d0a, 0x0d0a, 0x0d0a, 0x0d0a, 0x0d0a, 0x0d0a, 0x0d0a, 0x0d0a, 0x0d0a, 0x0d0a, 0x0d0a, 0x0d0a, 0x0509, 0xffff,
	0xffff, 0xffff, 0xffff, 0xffff, 0xffff, 0xffff, 0xffff, 0xffff, 0xffff, 0xffff, 0xffff, 0xffff, 0xffff, 0xffff, 0xffff, 0xffff,
	0xffff, 0xffff, 0xffff, 0xffff, 0xffff, 0xffff, 0xffff, 0xffff, 0x0d0a, 0x0d0a, 0xffff, 0xffff, 0xffff, 0x10a3, 0x10c3, 0x10a3,
	0x10c3, 0x10c3, 0x10a2, 0xffff, 0xffff, 0xffff, 0x0d0a, 0x0d0a, 0xffff, 0xffff, 0xffff, 0xffff, 0xffff, 0xffff, 0xffff, 0xffff,
	0xffff, 0xffff, 0x10a3, 0x10c3, 0x10c3, 0x10c3, 0x10c3, 0x10c3, 0x10c3, 0x10c3, 0x10a2, 0xffff, 0xffff, 0xffff, 0xffff, 0xffff,
	0xffff, 0x0d0a, 0x0d0a, 0x0d0a, 0x0d0a, 0x0d0a, 0x0d0a, 0x0d0a, 0x0d0a, 0x0d0a, 0x0d0a, 0x0d0a, 0x0d0a, 0x0d0a, 0x0d0a, 0x0d0a,
	0x0d0a, 0x0d0a, 0x0d0a, 0x0d0a, 0x0d0a, 0x0d0a, 0x0d0a, 0x0d0a, 0x0d0a, 0x0d0a, 0x0d0a, 0x0d0a, 0x0d0a, 0x0d0a, 0x0d0a, 0x0d09,
	0xffff, 0xffff, 0xffff, 0xffff, 0xffff, 0x0d2a, 0xf7de, 0xffff, 0xffff, 0xffff, 0xffff, 0xffff, 0x0d0a, 0x050a, 0x0d0a, 0x0d0a,
	0x0d0a, 0x0d0a, 0x0d0a, 0x0509, 0xffff, 0xffff, 0xffff, 0xffff, 0xffff, 0xffff, 0x0d0a, 0xffff, 0xffff, 0xffff, 0xffff, 0xffff,
	0x0d0a, 0x0509, 0x0d0a, 0x0d0a, 0x0d0a, 0x0d0a, 0x0d0a, 0x0d0a, 0x0d0a, 0x0d0a, 0x0d0a, 0x0d0a, 0x0d0a, 0x0d0a, 0x0d0a, 0x0d0a,
	0x0d0a, 0x0d0a, 0x0d0a, 0x0d0a, 0x0d0a, 0x0d0a, 0x0d0a, 0x0d0a, 0x0d0a, 0x0d0a, 0x0d0a, 0x0d0a, 0x0d0a, 0x0d0a, 0x0d09, 0xffff,
	0xffff, 0xffff, 0xffff, 0xffff, 0xffff, 0xffff, 0xffff, 0xffff, 0xffff, 0xffff, 0xffff, 0xffff, 0xffff, 0xffff, 0xffff, 0xffff,
	0xffff, 0xffff, 0xffff, 0xffff, 0xffff, 0xffff, 0xffff, 0xffff, 0x0d0a, 0x0d0a, 0xffff, 0xffff, 0xffff, 0x10c3, 0x10c3, 0x10a2,
	0x10c3, 0x10c3, 0x10a2, 0xffff, 0xffff, 0xffff, 0x0d0a, 0x0d0a, 0xffff, 0xffff, 0xffff, 0xffff, 0xffff, 0xffff, 0xffff, 0xffff,
	0xffff, 0x10c3, 0x10c3, 0x10c3, 0x10c3, 0x10a2, 0x10c3, 0x10a3, 0x10c3, 0x10c3, 0x10c3, 0x10c3, 0xffff, 0xffff, 0xffff, 0xffff,
	0xffff, 0x0d0a, 0x0d0a, 0x0d0a, 0x0d0a, 0x0d0a, 0x0d0a, 0x0d0a, 0x0d0a, 0x0d0a, 0x0d0a, 0x0d0a, 0x0d0a, 0x0d0a, 0x0d0a, 0x0d0a,
	0x0d0a, 0x0d0a, 0x0d0a, 0x0d0a, 0x0d0a, 0x0d0a, 0x0d0a, 0x0d0a, 0x0d0a, 0x0d0a, 0x0d0a, 0x0d0a, 0x0d0a, 0x0d0a, 0x0d0a, 0x0d0a,
	0x0d0a, 0x0d0a, 0xffff, 0xffff, 0xffff, 0x0d0a, 0x0509, 0xffff, 0xffff, 0xffff, 0x0d0a, 0x0d0a, 0x0d0a, 0x0d0a, 0x0d0a, 0x0d0a,
	0x0d0a, 0x0d0a, 0x0d0a, 0x0d0a, 0x0d0a, 0x0d0a, 0xffff, 0xffff, 0xffff, 0x0509, 0x0d0a, 0xffff, 0xffff, 0xffff, 0x0d0a, 0x0d0a,
	0x0d0a, 0x0d0a, 0x0d0a, 0x0d0a, 0x0d0a, 0x0d0a, 0x0d0a, 0x0d0a, 0x0d0a, 0x0d0a, 0x0d0a, 0x0d0a, 0x0d0a, 0x0d0a, 0x0d0a, 0x0d0a,
	0x0d0a, 0x0d0a, 0x0d0a, 0x0d0a, 0x0d0a, 0x0d0a, 0x0d0a, 0x0d0a, 0x0d0a, 0x0d0a, 0x0d0a, 0x0d0a, 0x0d0a, 0x0d0a, 0x0d0a, 0xffff,
	0xffff, 0xffff, 0xffff, 0xffff, 0xffff, 0xffff, 0xffff, 0xffff, 0xffff, 0xffff, 0xffff, 0xffff, 0xffff, 0xffff, 0x10c3, 0x10c3,
	0x4a8a, 0xffff, 0xffff, 0xffff, 0xffff, 0xffff, 0xffff, 0xffff, 0x0d0a, 0x0d0a, 0xffff, 0xffff, 0xffff, 0x10a2, 0x10c3, 0x10c3,
	0x10c3, 0x10c3, 0x10c3, 0xffff, 0xffff, 0xffff, 0x0d0a, 0x0d0a, 0xffff, 0xffff, 0xffff, 0xffff, 0xffff, 0xffff, 0xffff, 0xffff,
	0x10a2, 0x10c3, 0x10c3, 0x10a2, 0xffff, 0xffff, 0xffff, 0xffff, 0xffff, 0xffff, 0x10c3, 0x10c3, 0x10c3, 0xffff, 0xffff, 0xffff,
	0xffff, 0x0d0a, 0x0d0a, 0x0d0a, 0x0d0a, 0x0d0a, 0x0d0a, 0x0d0a, 0x0d0a, 0x0d0a, 0x0d0a, 0x0d0a, 0x0d0a, 0x0d0a, 0x0d0a, 0x0d0a,
	0x0d0a, 0x0d0a, 0x0d0a, 0x0d0a, 0x0d0a, 0x0d0a, 0x0d0a, 0x0d0a, 0x0d0a, 0x0d0a, 0x0d0a, 0x0d0a, 0x0d0a, 0x0d0a, 0x0d0a, 0x0d0a,
	0x0d0a, 0x0d0a, 0x0d0a, 0xffff, 0xffff, 0xffff, 0xffff, 0xffff, 0xffff, 0x0d09, 0x0d0a, 0x0d0a, 0x0d0a, 0x0d0a, 0x0d0a, 0x0d0a,
	0x0d0a, 0x0d0a, 0x0d0a, 0x0d0a, 0x0d0a, 0x0d0a, 0x0d0a, 0xffff, 0xffff, 0xffff, 0xffff, 0xffff, 0xffff, 0x0d09, 0x0d0a, 0x0d0a,
	0x0d0a, 0x0d0a, 0x0d0a, 0x0d0a, 0x0d0a, 0x0d0a, 0x0d0a, 0x0d0a, 0x0d0a, 0x0d0a, 0x0d0a, 0x0d0a, 0x0d0a, 0x0d0a, 0x0d0a, 0x0d0a,
	0x0d0a, 0x0d0a, 0x0d0a, 0x0d0a, 0x0d0a, 0x0d0a, 0x0d0a, 0x0d0a, 0x0d0a, 0x0d0a, 0x0d0a, 0x0d0a, 0x0d0a, 0x0d0a, 0x0d0a, 0xffff,
	0xffff, 0xffff, 0xffff, 0xffff, 0xffff, 0xffff, 0xffff, 0xffff, 0xffff, 0xffff, 0xffff, 0xffff, 0xffff, 0xffff, 0x10c3, 0x10c3,
	0xc638, 0xffff, 0xffff, 0xffff, 0xffff, 0xffff, 0xffff, 0xffff, 0x0d0a, 0x0d0a, 0xc75a, 0xffff, 0xffff, 0x10a3, 0x10c3, 0x10c3,
	0x10c3, 0x10c3, 0x10c3, 0xffff, 0xffff, 0xffff, 0x0d0a, 0x0d0a, 0xffff, 0xffff, 0xffff, 0xffff, 0xffff, 0xffff, 0xffff, 0xffff,
	0x10c3, 0x10c3, 0x2986, 0xffff, 0xffff, 0xffff, 0xffff, 0xffff, 0xffff, 0xffff, 0xffff, 0x10c3, 0x10c3, 0x10a3, 0xffff, 0xffff,
	0xffff, 0x0d0a, 0x0d0a, 0x0d0a, 0x0d0a, 0x0d0a, 0x0d0a, 0x0d0a, 0x0d0a, 0x0d0a, 0x0d0a, 0x0d0a, 0x0d0a, 0x0d0a, 0x0d0a, 0x0d0a,
	0x0d0a, 0x0d0a, 0x0d0a, 0x0d0a, 0x0d0a, 0x0d0a, 0x0d0a, 0x0d0a, 0x0d0a, 0x0d0a, 0x0d0a, 0x0d0a, 0x0d0a, 0x0d0a, 0x0d0a, 0x0d0a,
	0x0d0a, 0x0d0a, 0x0d0a, 0x0d29, 0xffff, 0xffff, 0xffff, 0xffff, 0x0d0a, 0x0d0a, 0x0d0a, 0x0d0a, 0x0d0a, 0x0d0a, 0x0d0a, 0x0d0a,
	0x0d0a, 0x0d0a, 0x0d0a, 0x0d0a, 0x0d0a, 0x0d0a, 0x0d0a, 0x0d0a, 0xffff, 0xffff, 0xffff, 0xffff, 0xa6f7, 0x0d0a, 0x0d0a, 0x0d0a,
	0x0d0a, 0x0d0a, 0x0d0a, 0x0d0a, 0x0d0a, 0x0d0a, 0x0d0a, 0x0d0a, 0x0d0a, 0x0d0a, 0x0d0a, 0x0d0a, 0x0d0a, 0x0d0a, 0x0d0a, 0x0d0a,
	0x0d0a, 0x0d0a, 0x0d0a, 0x0d0a, 0x0d0a, 0x0d0a, 0x0d0a, 0x0d0a, 0x0d0a, 0x0d0a, 0x0d0a, 0x0d0a, 0x0d0a, 0x0d0a, 0x0d0a, 0xffff,
	0xffff, 0xffff, 0x5aec, 0x8c71, 0xffff, 0xffff, 0xffff, 0xffff, 0xffff, 0xffff, 0xffff, 0xffff, 0xffff, 0xffff, 0x10c3, 0x10c3,
	0xffff, 0xffff, 0xffff, 0xffff, 0xffff, 0xffff, 0xffff, 0xffff, 0x0d0a, 0x0d0a, 0xc75a, 0xffff, 0xffff, 0x10a3, 0x10c3, 0x10c3,
	0x10c3, 0x10c3, 0x10c3, 0xffff, 0xffff, 0xffff, 0x0d0a, 0x0d0a, 0xffff, 0xffff, 0xffff, 0xffff, 0xffff, 0xffff, 0xffff, 0x7bef,
	0x10c3, 0x10c3, 0xffff, 0xffff, 0xffff, 0xffff, 0xffff, 0xffff, 0xffff, 0xffff, 0xffff, 0x10a2, 0x10c3, 0x10c3, 0xffff, 0xffff,
	0xffff, 0x0d0a, 0x0d0a, 0x0d0a, 0x0d0a, 0x0d0a, 0x0d0a, 0x0d0a, 0x0d0a, 0x0d0a, 0x0d0a, 0x0d0a, 0x0d0a, 0x0d0a, 0x0d0a, 0x0d0a,
	0x0d0a, 0x0d0a, 0x0d0a, 0x0d0a, 0x0d0a, 0x0d0a, 0x0d0a, 0x0d0a, 0x0d0a, 0x0d0a, 0x0d0a, 0x0d0a, 0x0d0a, 0x0d0a, 0x0d0a, 0x0d0a,
	0x0d0a, 0x0d0a, 0x0d0a, 0x0529, 0xffff, 0xffff, 0xffff, 0xffff, 0x0d0a, 0x0d0a, 0x0d0a, 0x0d0a, 0x0d0a, 0x0d0a, 0x0d0a, 0x0d0a,
	0x0d0a, 0x0d0a, 0x0d0a, 0x0d0a, 0x0d0a, 0x0d0a, 0x0d0a, 0x0509, 0xffff, 0xffff, 0xffff, 0xffff, 0x0d09, 0x0d0a, 0x0d0a, 0x0d0a,
	0x0d0a, 0x0d0a, 0x0d0a, 0x0d0a, 0x0d0a, 0x0d0a, 0x0d0a, 0x0d0a, 0x0d0a, 0x0d0a, 0x0d0a, 0x0d0a, 0x0d0a, 0x0d0a, 0x0d0a, 0x0d0a,
	0x0d0a, 0x0d0a, 0x0d0a, 0x0d0a, 0x0d0a, 0x0d0a, 0x0d0a, 0x0d0a, 0x0d0a, 0x0d0a, 0x0d0a, 0x0d0a, 0x0d0a, 0x0d0a, 0x0d0a, 0xffff,
	0xffff, 0xffff, 0x10a2, 0x10c3, 0x10c3, 0x10c3, 0x10c3, 0x10c3, 0x10c3, 0x10c3, 0x10c3, 0x10c3, 0x10c3, 0x10c3, 0x10c3, 0x10c3,
	0xffff, 0xffff, 0xffff, 0xffff, 0xffff, 0xffff, 0xffff, 0xffff, 0x0d0a, 0x0d0a, 0xffff, 0xffff, 0xffff, 0x10c3, 0x10c3, 0x10c3,
	0x10a2, 0x10c3, 0x10a3, 0xffff, 0xffff, 0xffff, 0x0d0a, 0x0d0a, 0xffff, 0xffff, 0xffff, 0xffff, 0xffff, 0xffff, 0xffff, 0x10c3,
	0x10c3, 0x10c3, 0xffff, 0xffff, 0xffff, 0xffff, 0xffff, 0xffff, 0xffff, 0xffff, 0xffff, 0x10a3, 0x10c3, 0x10c3, 0xffff, 0xffff,
	0xffff, 0x0d0a, 0x0d0a, 0x0d0a, 0x0d0a, 0x0d0a, 0x0d0a, 0x0d0a, 0x0d0a, 0x0d0a, 0x0d0a, 0x0d0a, 0x0d0a, 0x0d0a, 0x0d0a, 0x0d0a,
	0x0d0a, 0x0d0a, 0x0d0a, 0x0d0a, 0x0d0a, 0x0d0a, 0x0d0a, 0x0d0a, 0x0d0a, 0x0d0a, 0x0d0a, 0x0d0a, 0x0d0a, 0x0d0a, 0x0d0a, 0x0d0a,
	0x0d0a, 0x0d0a, 0x0d0a, 0x0d0a, 0xffff, 0xffff, 0xffff, 0xffff, 0x0d0a, 0x0d0a, 0x0d0a, 0x0d0a, 0x0d0a, 0x0d0a, 0x0d0a, 0x0d0a,
	0x0d0a, 0x0d0a, 0x0d0a, 0x0d0a, 0x0d0a, 0x0d0a, 0x0d0a, 0x0d0a, 0xffff, 0xffff, 0xffff, 0xffff, 0x0d2a, 0x0d0a, 0x0d0a, 0x0d0a,
	0x0d0a, 0x0d0a, 0x0d0a, 0x0d0a, 0x0d0a, 0x0d0a, 0x0d0a, 0x0d0a, 0x0d0a, 0x0d0a, 0x0d0a, 0x0d0a, 0x0d0a, 0x0d0a, 0x0d0a, 0x0d0a,
	0x0d0a, 0x0d0a, 0x0d0a, 0x0d0a, 0x0d0a, 0x0d0a, 0x0d0a, 0x0d0a, 0x0d0a, 0x0d0a, 0x0d0a, 0x0d0a, 0x0d0a, 0x0d0a, 0x0d2a, 0xffff,
	0xffff, 0xffff, 0x10a2, 0x10c3, 0x10c3, 0x10c3, 0x10c3, 0x10c3, 0x10c3, 0x10c3, 0x10c3, 0x10c3, 0x10c3, 0x10c3, 0x10c3, 0x10c3,
	0xffff, 0xffff, 0xffff, 0xffff, 0xffff, 0xffff, 0xffff, 0xffff, 0x0d0a, 0x0d0a, 0xffff, 0xffff, 0xffff, 0x10a2, 0x10c3, 0x10a2,
	0x10c3, 0x10c3, 0x10a2, 0xffff, 0xffff, 0xffff, 0x0d0a, 0x0d0a, 0xffff, 0xffff, 0xffff, 0xffff, 0xffff, 0xffff, 0xffff, 0xa555,
	0x10c3, 0x10c3, 0xffff, 0xffff, 0xffff, 0xffff, 0xffff, 0xffff, 0xffff, 0xffff, 0xffff, 0x10a2, 0x10c3, 0x10c3, 0xffff, 0xffff,
	0xffff, 0x0d2a, 0x0d0a, 0x0d0a, 0x0d0a, 0x0d0a, 0x0d0a, 0x0d0a, 0x0d0a, 0x0d0a, 0x0d0a, 0x0d0a, 0x0d0a, 0x0d0a, 0x0d0a, 0x0d0a,
	0x0d0a, 0x0d0a, 0x0d0a, 0x0d0a, 0x0d0a, 0x0d0a, 0x0d0a, 0x0d0a, 0x0d0a, 0x0d0a, 0x0d0a, 0x0d0a, 0x0d0a, 0x0d0a, 0x0d0a, 0x0d0a,
	0x0d0a, 0x0d0a, 0x0d0a, 0x154b, 0xffff, 0xffff, 0xffff, 0xffff, 0x0d0a, 0x0d0a, 0x0d0a, 0x0d0a, 0x0d0a, 0x0d0a, 0x0d0a, 0x0d0a,
	0x0d0a, 0x0d0a, 0x0d0a, 0x0d0a, 0x0d0a, 0x0d0a, 0x0d0a, 0x0d0a, 0xffff, 0xffff, 0xffff, 0xffff, 0xd77b, 0x0d0a, 0x0d0a, 0x0d0a,
	0x0d0a, 0x0d0a, 0x0d0a, 0x0d0a, 0x0d0a, 0x0d0a, 0x0d0a, 0x0d0a, 0x0d0a, 0x0d0a, 0x0d0a, 0x0d0a, 0x0d0a, 0x0d0a, 0x0d0a, 0x0d0a,
	0x0d0a, 0x0d0a, 0x0d0a, 0x0d0a, 0x0d0a, 0x0d0a, 0x0d0a, 0x0d0a, 0x0d0a, 0x0d0a, 0x0d0a, 0x0d0a, 0x0d0a, 0x0d0a, 0x0d2a, 0xffff,
	0xffff, 0xffff, 0xffff, 0xffff, 0xffff, 0xffff, 0xffff, 0xffff, 0xffff, 0xffff, 0xffff, 0xffff, 0xffff, 0xffff, 0x10c3, 0x10c3,
	0xffff, 0xffff, 0xffff, 0xffff, 0xffff, 0xffff, 0xffff, 0xffff, 0x0d0a, 0x0d0a, 0xffff, 0xffff, 0xffff, 0x10a3, 0x10c3, 0x10a2,
	0x10a3, 0x10c3, 0x10c3, 0xffff, 0xffff, 0xffff, 0x0d0a, 0x0d0a, 0xffff, 0xffff, 0xffff, 0xffff, 0xffff, 0xffff, 0xffff, 0xffff,
	0x10c3, 0x10c3, 0xffff, 0xffff, 0xffff, 0xffff, 0xffff, 0xffff, 0xffff, 0xffff, 0xffff, 0x10c3, 0x10c3, 0x10a3, 0xffff, 0xffff,
	0xffff, 0x0d0a, 0x0d0a, 0x0d0a, 0x0d0a, 0x0d0a, 0x0d0a, 0x0d0a, 0x0d0a, 0x0d0a, 0x0d0a, 0x0d0a, 0x0d0a, 0x0d0a, 0x0d0a, 0x0d0a,
	0x0d0a, 0x0d0a, 0x0d0a, 0x0d0a, 0x0d0a, 0x0d0a, 0x0d0a, 0x0d0a, 0x0d0a, 0x0d0a, 0x0d0a, 0x0d0a, 0x0d0a, 0x0d0a, 0x0d0a, 0x0d0a,
	0x0d0a, 0x0d0a, 0x0d0a, 0xffff, 0xffff, 0xffff, 0xffff, 0xffff, 0xffff, 0x050a, 0x0d0a, 0x0d0a, 0x0d0a, 0x0d0a, 0x0d0a, 0x0d0a,
	0x0d0a, 0x0d0a, 0x0d0a, 0x0d0a, 0x0d0a, 0x0d0a, 0x0d0a, 0xffff, 0xffff, 0xffff, 0xffff, 0xffff, 0xffff, 0x0509, 0x0d0a, 0x0d0a,
	0x0d0a, 0x0d0a, 0x0d0a, 0x0d0a, 0x0d0a, 0x0d0a, 0x0d0a, 0x0d0a, 0x0d0a, 0x0d0a, 0x0d0a, 0x0d0a, 0x0d0a, 0x0d0a, 0x0d0a, 0x0d0a,
	0x0d0a, 0x0d0a, 0x0d0a, 0x0d0a, 0x0d0a, 0x0d0a, 0x0d0a, 0x0d0a, 0x0d0a, 0x0d0a, 0x0d0a, 0x0d0a, 0x0d0a, 0x0d0a, 0x0d2a, 0xffff,
	0xffff, 0xffff, 0xffff, 0xffff, 0xffff, 0xffff, 0xffff, 0xffff, 0xffff, 0xffff, 0xffff, 0xffff, 0xffff, 0xffff, 0x10c3, 0x10c3,
	0xffff, 0xffff, 0xffff, 0xffff, 0xffff, 0xffff, 0xffff, 0xffff, 0x0d0a, 0x0d0a, 0xffff, 0xffff, 0xffff, 0x10a3, 0x10c3, 0x10c3,
	0x10a3, 0x10c3, 0x10c3, 0xffff, 0xffff, 0xffff, 0x0d0a, 0x0d0a, 0xc73a, 0xffff, 0xffff, 0xffff, 0xffff, 0xffff, 0xffff, 0xffff,
	0x10c3, 0x10c3, 0x10c3, 0xffff, 0xffff, 0xffff, 0xffff, 0xffff, 0xffff, 0xffff, 0x10a3, 0x10a2, 0x10a2, 0xffff, 0xffff, 0xffff,
	0xffff, 0xffff, 0x0d0a, 0x0d0a, 0x0d0a, 0x0d0a, 0x0d0a, 0x0d0a, 0x0d0a, 0x0d0a, 0x0d0a, 0x0d0a, 0x0d0a, 0x0d0a, 0x0d0a, 0x0d0a,
	0x0d0a, 0x0d0a, 0x0d0a, 0x0d0a, 0x0d0a, 0x0d0a, 0x0d0a, 0x0d0a, 0x0d0a, 0x0d0a, 0x0d0a, 0x0d0a, 0x0d0a, 0x0d0a, 0x0d0a, 0x0d0a,
	0x0d0a, 0x0d2a, 0xffff, 0xffff, 0xffff, 0xffff, 0xffff, 0xffff, 0xffff, 0xffff, 0x0d0a, 0x0d0a, 0x0d0a, 0x0d0a, 0x0d0a, 0x0d0a,
	0x0d0a, 0x0d0a, 0x0d0a, 0x0d0a, 0x0d0a, 0x0d0a, 0xffff, 0xffff, 0xffff, 0xffff, 0xffff, 0xffff, 0xffff, 0xffff, 0x0d2a, 0x0d0a,
	0x0d0a, 0x0d0a, 0x0d0a, 0x0d0a, 0x0d0a, 0x0d0a, 0x0d0a, 0x0d0a, 0x0d0a, 0x0d0a, 0x0d0a, 0x0d0a, 0x0d0a, 0x0d0a, 0x0d0a, 0x0d0a,
	0x0d0a, 0x0d0a, 0x0d0a, 0x0d0a, 0x0d0a, 0x0d0a, 0x0d0a, 0x0d0a, 0x0d0a, 0x0d0a, 0x0d0a, 0x0d0a, 0x0d0a, 0x0d0a, 0x35ae, 0xffff,
	0xffff, 0xffff, 0xffff, 0xffff, 0xffff, 0xffff, 0xffff, 0xffff, 0xffff, 0xffff, 0xffff, 0xffff, 0xffff, 0xffff, 0x10c3, 0x10c3,
	0xffff, 0xffff, 0xffff, 0xffff, 0xffff, 0xffff, 0xffff, 0xffff, 0x0d0a, 0x0d0a, 0xffff, 0xffff, 0xffff, 0x10c3, 0x10c3, 0x10c3,
	0x10a3, 0x10c3, 0x10c3, 0xffff, 0xffff, 0xffff, 0x0d0a, 0x0d0a, 0x0d0a, 0xffff, 0xffff, 0xffff, 0xffff, 0xffff, 0xffff, 0xffff,
	0xffff, 0xffff, 0xffff, 0xffff, 0xffff, 0xffff, 0xffff, 0xffff, 0xffff, 0xffff, 0xffff, 0xffff, 0xffff, 0xffff, 0xffff, 0xffff,
	0xffff, 0xffff, 0x0d0a, 0x0d0a, 0x0d0a, 0x0d0a, 0x0d0a, 0x0d0a, 0x0d0a, 0x0d0a, 0x0d0a, 0x0d0a, 0x0d0a, 0x0d0a, 0x0d0a, 0x0d0a,
	0x0d0a, 0x0d0a, 0x0d0a, 0x0d0a, 0x0d0a, 0x0529, 0x0d0a, 0x0d0a, 0x0d0a, 0x0d0a, 0x0d0a, 0x0d0a, 0x0d0a, 0x0d0a, 0x0d2a, 0x050a,
	0xffff, 0xffff, 0xffff, 0xffff, 0xffff, 0xffff, 0xffff, 0xffff, 0xffff, 0xffff, 0xffff, 0xe7bd, 0x0d0a, 0x0529, 0x0d0a, 0x0d0a,
	0x0d0a, 0x0d0a, 0x0d0a, 0x0d0a, 0x8674, 0xffff, 0xffff, 0xffff, 0xffff, 0xffff, 0xffff, 0xffff, 0xffff, 0xffff, 0xffff, 0xffff,
	0x0d09, 0x050a, 0x0d0a, 0x0d0a, 0x0d0a, 0x0d0a, 0x0d0a, 0x0d0a, 0x0d0a, 0x0d0a, 0x0d0a, 0x0d0a, 0x0d0a, 0x0d0a, 0x0d0a, 0x0d0a,
	0x0d0a, 0x0d0a, 0x0d0a, 0x0d0a, 0x0d0a, 0x0d0a, 0x0d0a, 0x0d0a, 0x0d0a, 0x0d0a, 0x0d0a, 0x0d0a, 0x0d0a, 0x0d0a, 0xffff, 0xffff,
	0xffff, 0xffff, 0xffff, 0xffff, 0xffff, 0xffff, 0xffff, 0xffff, 0xffff, 0xffff, 0xffff, 0xffff, 0xffff, 0xffff, 0xffff, 0xffff,
	0xffff, 0xffff, 0xffff, 0xffff, 0xffff, 0xffff, 0xffff, 0x7653, 0x0d0a, 0x0d0a, 0xffff, 0xffff, 0xffff, 0x10c3, 0x10c3, 0x10c3,
	0xffff, 0x10c3, 0x10c3, 0xffff, 0xffff, 0xffff, 0x0d0a, 0x0d0a, 0x0d0a, 0xffff, 0xffff, 0xffff, 0xffff, 0xffff, 0xffff, 0xffff,
	0xffff, 0xffff, 0xffff, 0xffff, 0xffff, 0xffff, 0xffff, 0xffff, 0xffff, 0xffff, 0xffff, 0xffff, 0xffff, 0x10a3, 0xffff, 0xffff,
	0xffff, 0xffff, 0x0d0a, 0x0d0a, 0x0d0a, 0x0d0a, 0x0d0a, 0x0d0a, 0x0d0a, 0x0d0a, 0x0d0a, 0x0d0a, 0x0d0a, 0x0d0a, 0x0d0a, 0x0d0a,
	0x0d0a, 0x0d0a, 0x0d0a, 0x0d0a, 0x0d0a, 0x0d09, 0xffff, 0xffff, 0xffff, 0xffff, 0xffff, 0xffff, 0xffff, 0xffff, 0xffff, 0xffff,
	0xffff, 0xffff, 0xffff, 0xffff, 0xffff, 0xffff, 0xffff, 0xffff, 0xffff, 0xffff, 0xffff, 0xffff, 0xffff, 0xffff, 0xffff, 0xffff,
	0xffff, 0xffff, 0xffff, 0xffff, 0xffff, 0xffff, 0xffff, 0xffff, 0xffff, 0xffff, 0xffff, 0xffff, 0xffff, 0xffff, 0xffff, 0xffff,
	0xffff, 0xffff, 0xffff, 0xffff, 0xffff, 0xffff, 0xffff, 0xffff, 0xffff, 0xffff, 0xc75a, 0x0d0a, 0x0d0a, 0x0d0a, 0x0d0a, 0x0d0a,
	0x0d0a, 0x0d0a, 0x0d0a, 0x0d0a, 0x0d0a, 0x0d0a, 0x0d0a, 0x0d0a, 0x0d0a, 0x0d0a, 0x0d0a, 0x0d0a, 0x0d0a, 0x0d09, 0xffff, 0xffff,
	0xffff, 0xffff, 0xffff, 0xffff, 0xffff, 0xffff, 0xffff, 0xffff, 0xffff, 0xffff, 0xffff, 0xffff, 0xffff, 0xffff, 0xffff, 0xffff,
	0xffff, 0xffff, 0xffff, 0xffff, 0xffff, 0xffff, 0xffff, 0x0d2a, 0x0d0a, 0x0d0a, 0xffff, 0xffff, 0xffff, 0x10c3, 0x10c3, 0x4a8a,
	0xffff, 0x10a3, 0x10c3, 0xd6ba, 0xffff, 0xffff, 0x052a, 0x0d0a, 0x0d0a, 0xffff, 0xffff, 0xffff, 0xffff, 0xffff, 0xffff, 0xffff,
	0xffff, 0xffff, 0xffff, 0xffff, 0xffff, 0xffff, 0xffff, 0xffff, 0xffff, 0xffff, 0xffff, 0x10a3, 0x10c3, 0x10c3, 0xb5b6, 0xffff,
	0xffff, 0xffff, 0x0d29, 0x0d0a, 0x0d0a, 0x0d0a, 0x0d0a, 0x0d0a, 0x0d0a, 0x0d0a, 0x0d0a, 0x0d0a, 0x0d0a, 0x0d0a, 0x0d0a, 0x0d0a,
	0x0d0a, 0x0d0a, 0x0d0a, 0x0d0a, 0x0d0a, 0x0d09, 0xffff, 0xffff, 0xffff, 0xffff, 0xffff, 0xffff, 0xffff, 0xffff, 0xffff, 0xffff,
	0xffff, 0xffff, 0xffff, 0xffff, 0xffff, 0xffff, 0xffff, 0xffff, 0xffff, 0xffff, 0xffff, 0xffff, 0xffff, 0xffff, 0xffff, 0xffff,
	0xffff, 0xffff, 0xffff, 0xffff, 0xffff, 0xffff, 0xffff, 0xffff, 0xffff, 0xffff, 0xffff, 0xffff, 0xffff, 0xffff, 0xffff, 0xffff,
	0xffff, 0xffff, 0xffff, 0xffff, 0xffff, 0xffff, 0xffff, 0xffff, 0xffff, 0xffff, 0xc75a, 0x0d0a, 0x0d0a, 0x0d0a, 0x0d0a, 0x0d0a,
	0x0d0a, 0x0d0a, 0x0d0a, 0x0d0a, 0x0d0a, 0x0d0a, 0x0d0a, 0x0d0a, 0x0d0a, 0x0d0a, 0x0d0a, 0x0d0a, 0x0d0a, 0x0d0a, 0xffff, 0xffff,
	0xffff, 0x10c3, 0x10c3, 0x10c3, 0x10c3, 0x10a3, 0x10a3, 0xffff, 0xffff, 0xffff, 0xffff, 0xffff, 0xffff, 0xffff, 0xffff, 0xffff,
	0xffff, 0xffff, 0xffff, 0xffff, 0xffff, 0xffff, 0xffff, 0x0d09, 0x0d0a, 0x0d0a, 0xffff, 0xffff, 0xffff, 0x10c3, 0x10c3, 0xffff,
	0xffff, 0x10a2, 0x10c3, 0x10c3, 0xffff, 0xffff, 0x154b, 0x0d0a, 0x0d0a, 0xffff, 0xffff, 0xffff, 0xffff, 0xffff, 0xffff, 0xffff,
	0xffff, 0xffff, 0xffff, 0xffff, 0xffff, 0xffff, 0xffff, 0xffff, 0xffff, 0xf79e, 0x10c3, 0x10c3, 0x10c3, 0x10c3, 0xffff, 0xffff,
	0xffff, 0xffff, 0xffff, 0x0d0a, 0x0d0a, 0x0d0a, 0x0d0a, 0x0d0a, 0x0d0a, 0x0d0a, 0x0d0a, 0x0d0a, 0x0d0a, 0x0d0a, 0x0d0a, 0x0d0a,
	0x0d0a, 0x0d0a, 0x0d0a, 0x0d0a, 0x0d0a, 0x0d09, 0xffff, 0xffff, 0xffff, 0xffff, 0xffff, 0xffff, 0xffff, 0xffff, 0xffff, 0xffff,
	0xffff, 0xffff, 0xffff, 0xffff, 0xffff, 0xffff, 0xffff, 0xffff, 0xffff, 0xffff, 0xffff, 0xffff, 0xffff, 0xffff, 0xffff, 0xffff,
	0xffff, 0xffff, 0xffff, 0xffff, 0xffff, 0xffff, 0xffff, 0xffff, 0xffff, 0xffff, 0xffff, 0xffff, 0xffff, 0xffff, 0xffff, 0xffff,
	0xffff, 0xffff, 0xffff, 0xffff, 0xffff, 0xffff, 0xffff, 0xffff, 0xffff, 0xffff, 0xc75a, 0x0d0a, 0x0d0a, 0x0d0a, 0x0d0a, 0x0d0a,
	0x0d0a, 0x0d0a, 0x0d0a, 0x0d0a, 0x0d0a, 0x0d0a, 0x0d0a, 0x0d0a, 0x0d0a, 0x0d0a, 0x0d0a, 0x0d0a, 0x0d0a, 0x8694, 0xffff, 0xffff,
	0xffff, 0x10c3, 0x10c3, 0x10c3, 0x10c3, 0x10c3, 0x10c3, 0x10c3, 0x10c3, 0x10a2, 0x10a3, 0x10a3, 0xc638, 0xffff, 0xffff, 0xffff,
	0xffff, 0xffff, 0xffff, 0xffff, 0xffff, 0xffff, 0xffff, 0x0d09, 0x0d0a, 0x0d2a, 0xffff, 0xffff, 0x10a2, 0x10c3, 0x10c3, 0xffff,
	0xffff, 0x10c3, 0x10c3, 0x10a3, 0xffff, 0xffff, 0xffff, 0x0d0a, 0x0d0a, 0xffff, 0xffff, 0xffff, 0xffff, 0xffff, 0xffff, 0xffff,
	0xffff, 0xffff, 0xffff, 0xffff, 0xffff, 0xffff, 0xffff, 0xffff, 0x10c3, 0x10c3, 0x10c3, 0x10c3, 0x10a3, 0xffff, 0xffff, 0xffff,
	0xffff, 0xffff, 0xffff, 0x0d09, 0x0d0a, 0x0d0a, 0x0d0a, 0x0d0a, 0x0d0a, 0x0d0a, 0x0d0a, 0x0d0a, 0x0d0a, 0x0d0a, 0x0d0a, 0x0d0a,
	0x0d0a, 0x0d0a, 0x0d0a, 0x0d0a, 0x0d0a, 0x0d09, 0xffff, 0xffff, 0xffff, 0xffff, 0xffff, 0x96b6, 0x0d09, 0x0d0a, 0x0509, 0x0d09,
	0xffff, 0xffff, 0xffff, 0xffff, 0xffff, 0xffff, 0xffff, 0xffff, 0xffff, 0xffff, 0xffff, 0xffff, 0x0d0a, 0x0d09, 0x0d0a, 0x0d0a,
	0x0d0a, 0x0d0a, 0x0d0a, 0x0d29, 0xffff, 0xffff, 0xffff, 0xffff, 0xffff, 0xffff, 0xffff, 0xffff, 0xffff, 0xffff, 0xffff, 0xffff,
	0x052a, 0x0d2a, 0x0d2a, 0x0d0a, 0x45cf, 0xffff, 0xffff, 0xffff, 0xffff, 0xffff, 0xc75a, 0x0d0a, 0x0d0a, 0x0d0a, 0x0d0a, 0x0d0a,
	0x0d0a, 0x0d0a, 0x0d0a, 0x0d0a, 0x0d0a, 0x0d0a, 0x0d0a, 0x0d0a, 0x0d0a, 0x0d0a, 0x0d0a, 0x0d0a, 0x0d0a, 0xffff, 0xffff, 0xffff,
	0xffff, 0xffff, 0xffff, 0xffff, 0x2124, 0x10c3, 0x10c3, 0x10c3, 0x10c3, 0x10c3, 0x10c3, 0x10c3, 0x10c3, 0x10c3, 0x10c3, 0xffff,
	0xffff, 0xffff, 0xffff, 0xffff, 0xffff, 0xffff, 0xffff, 0x0d0a, 0x0d0a, 0xffff, 0xffff, 0xffff, 0x10c3, 0x10c3, 0x10c3, 0xffff,
	0xffff, 0x10a3, 0x10c3, 0x10c3, 0xffff, 0xffff, 0xffff, 0x0d0a, 0x0d0a, 0x6632, 0xffff, 0xffff, 0xffff, 0xffff, 0xffff, 0xffff,
	0xffff, 0xffff, 0xffff, 0xffff, 0xffff, 0xffff, 0x10a3, 0x10c3, 0x10c3, 0x10c3, 0x10a2, 0x10c3, 0x10a3, 0xffff, 0xffff, 0xffff,
	0xffff, 0xffff, 0xffff, 0x0d0a, 0x0d0a, 0x0d0a, 0x0d0a, 0x0d0a, 0x0d0a, 0x0d0a, 0x0d0a, 0x0d0a, 0x0d0a, 0x0d0a, 0x0d0a, 0x0d0a,
	0x0d0a, 0x0d0a, 0x0d0a, 0x0d0a, 0x0d0a, 0x0d09, 0xffff, 0xffff, 0xffff, 0xffff, 0x0d0a, 0x0d0a, 0x0d0a, 0x0d0a, 0x0d0a, 0x0d0a,
	0x0d0a, 0x0d0a, 0xffff, 0xffff, 0xffff, 0xffff, 0xffff, 0xffff, 0xffff, 0xffff, 0x0d0a, 0x0d0a, 0x0d0a, 0x0d0a, 0x0d0a, 0x0d0a,
	0x0d0a, 0x0d0a, 0x0d0a, 0x0d0a, 0x0d0a, 0x0d0a, 0xffff, 0xffff, 0xffff, 0xffff, 0xffff, 0xffff, 0xffff, 0xffff, 0x0d0a, 0x0d0a,
	0x0d0a, 0x0d0a, 0x0d0a, 0x0d0a, 0x0d0a, 0x0d0a, 0xa6f8, 0xffff, 0xffff, 0xffff, 0xc75a, 0x0d0a, 0x0d0a, 0x0d0a, 0x0d0a, 0x0d0a,
	0x0d0a, 0x0d0a, 0x0d0a, 0x0d0a, 0x0d0a, 0x0d0a, 0x0d0a, 0x0d0a, 0x0d0a, 0x0d0a, 0x0d0a, 0x0d0a, 0x0d0a, 0xffff, 0xffff, 0xffff,
	0xffff, 0xffff, 0xffff, 0xffff, 0xffff, 0xffff, 0xffff, 0xffff, 0xffff, 0xffff, 0x10a2, 0x10a2, 0x10c3, 0x10c3, 0x10c3, 0xffff,
	0x9cd3, 0x10c3, 0x10c3, 0xffff, 0xffff, 0xffff, 0xffff, 0x0d0a, 0x0d2a, 0xffff, 0xffff, 0xffff, 0x10c3, 0x10c3, 0x10c3, 0xffff,
	0xffff, 0xffff, 0x10c3, 0x10c3, 0xffff, 0xffff, 0xffff, 0x0d09, 0x0d0a, 0x0d0a, 0xffff, 0xffff, 0xffff, 0xffff, 0xffff, 0xffff,
	0xffff, 0xffff, 0xffff, 0xffff, 0xffff, 0x10c3, 0x10c3, 0x10c3, 0x10c3, 0xffff, 0xffff, 0x10c3, 0x10c3, 0xffff, 0xffff, 0xffff,
	0xffff, 0xffff, 0xffff, 0xffff, 0x0d0a, 0x0d0a, 0x0d0a, 0x0d0a, 0x0d0a, 0x0d0a, 0x0d0a, 0x0d0a, 0x0d0a, 0x0d0a, 0x0d0a, 0x0d0a,
	0x0d0a, 0x0d0a, 0x0d0a, 0x0d0a, 0x0d0a, 0x0d09, 0xffff, 0xffff, 0xffff, 0x0d0a, 0x0d0a, 0x0d0a, 0x0d0a, 0x0d0a, 0x0d0a, 0x0d0a,
	0x0d0a, 0x0d0a, 0x0d0a, 0xffff, 0xffff, 0xffff, 0xffff, 0xffff, 0xffff, 0x0d0a, 0x0d0a, 0x0d0a, 0x0d0a, 0x0d0a, 0x0d0a, 0x0d0a,
	0x0d0a, 0x0d0a, 0x0d0a, 0x0d0a, 0x0d0a, 0x0d0a, 0x0d0a, 0xffff, 0xffff, 0xffff, 0xffff, 0xffff, 0xffff, 0x0529, 0x0d0a, 0x0d0a,
	0x0d0a, 0x0d0a, 0x0d0a, 0x0d0a, 0x0d0a, 0x0d0a, 0x0d0a, 0x4dcf, 0xffff, 0xffff, 0xc75a, 0x0d0a, 0x0d0a, 0x0d0a, 0x0d0a, 0x0d0a,
	0x0d0a, 0x0d0a, 0x0d0a, 0x0d0a, 0x0d0a, 0x0d0a, 0x0d0a, 0x0d0a, 0x0d0a, 0x0d0a, 0x0d0a, 0x0d0a, 0xffff, 0xffff, 0xffff, 0xffff,
	0xffff, 0xffff, 0xffff, 0xffff, 0xffff, 0xffff, 0xffff, 0xffff, 0xffff, 0xffff, 0xffff, 0xffff, 0xffff, 0xffff, 0xffff, 0xffff,
	0xffff, 0x10c3, 0x8c51, 0xffff, 0xffff, 0xffff, 0x0d0a, 0x0d0a, 0x0d0a, 0xffff, 0xffff, 0xffff, 0x10c3, 0x10c3, 0x6b6d, 0xffff,
	0xffff, 0xffff, 0x10c3, 0x10c3, 0x10a3, 0xffff, 0xffff, 0x45cf, 0x0d0a, 0x050a, 0xffff, 0xffff, 0xffff, 0xffff, 0xffff, 0xffff,
	0xffff, 0xffff, 0xffff, 0x10a2, 0x10c3, 0x10c3, 0x10c3, 0x2124, 0xffff, 0xffff, 0xffff, 0x10c3, 0x10c3, 0xe71c, 0xffff, 0xffff,
	0xffff, 0xffff, 0xffff, 0xffff, 0x0d0a, 0x0d0a, 0x0d0a, 0x0d0a, 0x0d0a, 0x0d0a, 0x0d0a, 0x0d0a, 0x0d0a, 0x0d0a, 0x0d0a, 0x0d0a,
	0x0d0a, 0x0d0a, 0x0d0a, 0x0d0a, 0x0d0a, 0x0d09, 0xffff, 0xffff, 0x0d0a, 0x0d0a, 0x0d0a, 0x0d0a, 0x0d0a, 0x0d0a, 0x0d0a, 0x0d0a,
	0x0d0a, 0x0d0a, 0x0d0a, 0x0d0a, 0xffff, 0xffff, 0xffff, 0xffff, 0x0d0a, 0x0d0a, 0x0d0a, 0x0d0a, 0x0d0a, 0x0d0a, 0x0d0a, 0x0d0a,
	0x0d0a, 0x0d0a, 0x0d0a, 0x0d0a, 0x0d0a, 0x0d0a, 0x0d0a, 0x0d0a, 0xffff, 0xffff, 0xffff, 0xffff, 0x0d0a, 0x0d0a, 0x0d0a, 0x0d0a,
	0x0d0a, 0x0d0a, 0x0d0a, 0x0d0a, 0x0d0a, 0x0d0a, 0x0d0a, 0x0d0a, 0xffff, 0xffff, 0xc75a, 0x0d0a, 0x0d0a, 0x0d0a, 0x0d0a, 0x0d0a,
	0x0d0a, 0x0d0a, 0x0d0a, 0x0d0a, 0x0d0a, 0x0d0a, 0x0d0a, 0x0d0a, 0x0d0a, 0x0d0a, 0x0d0a, 0x0d0a, 0xffff, 0xffff, 0xffff, 0xffff,
	0x94d3, 0x10c3, 0x10c3, 0x10c3, 0xffff, 0xffff, 0xffff, 0xffff, 0xffff, 0xffff, 0xffff, 0xffff, 0xffff, 0xffff, 0xffff, 0xffff,
	0xffff, 0xffff, 0xffff, 0xffff, 0xffff, 0xffff, 0x0d0a, 0x0d0a, 0x0d0a, 0xffff, 0xffff, 0x10a2, 0x10c3, 0x10c3, 0xffff, 0xffff,
	0xffff, 0xffff, 0x10c3, 0x10c3, 0x10c3, 0xffff, 0xffff, 0xffff, 0x0d0a, 0x0d0a, 0xffff, 0xffff, 0xffff, 0xffff, 0xffff, 0xffff,
	0xffff, 0xffff, 0x10a3, 0x10c3, 0x10c3, 0x10a3, 0xffff, 0xffff, 0xffff, 0xffff, 0xffff, 0x10c3, 0x10c3, 0x10a3, 0xffff, 0xffff,
	0xffff, 0xffff, 0xffff, 0xffff, 0xffff, 0x0d0a, 0x0d0a, 0x0d0a, 0x0d0a, 0x0d0a, 0x0d0a, 0x0d0a, 0x0d0a, 0x0d0a, 0x0d0a, 0x0d0a,
	0x0d0a, 0x0d0a, 0x0d0a, 0x0d0a, 0x0d0a, 0x0d09, 0xffff, 0xffff, 0x0d0a, 0x0d0a, 0x0d0a, 0x0d0a, 0x0d0a, 0x0d0a, 0x0d0a, 0x0d0a,
	0x0d0a, 0x0d0a, 0x0d0a, 0x0d0a, 0xffff, 0xffff, 0xffff, 0xffff, 0x0d0a, 0x0d0a, 0x0d0a, 0x0d0a, 0x0d0a, 0x0d0a, 0x0d0a, 0x0d0a,
	0x0d0a, 0x0d0a, 0x0d0a, 0x0d0a, 0x0d0a, 0x0d0a, 0x0d0a, 0x0509, 0xffff, 0xffff, 0xffff, 0xffff, 0x0d2a, 0x0d0a, 0x0d0a, 0x0d0a,
	0x0d0a, 0x0d0a, 0x0d0a, 0x0d0a, 0x0d0a, 0x0d0a, 0x0d0a, 0x0d0a, 0xffff, 0xffff, 0xc75a, 0x0d0a, 0x0d0a, 0x0d0a, 0x0d0a, 0x0d0a,
	0x0d0a, 0x0d0a, 0x0d0a, 0x0d0a, 0x0d0a, 0x0d0a, 0x0d0a, 0x0d0a, 0x0d0a, 0x0d0a, 0x0d0a, 0xffff, 0xffff, 0xffff, 0xffff, 0x10a2,
	0x10c3, 0x10c3, 0x10c3, 0x10c3, 0x10c3, 0xef9e, 0xffff, 0xffff, 0xffff, 0xffff, 0xffff, 0xffff, 0xffff, 0xffff, 0xffff, 0xffff,
	0xffff, 0xffff, 0xffff, 0xffff, 0xffff, 0xffff, 0x0d0a, 0x0d0a, 0xffff, 0xffff, 0xffff, 0x10a3, 0x10c3, 0x10c3, 0xffff, 0xffff,
	0xffff, 0xffff, 0x10a2, 0x10c3, 0x10c3, 0xffff, 0xffff, 0xffff, 0x052a, 0x0d0a, 0x0d0a, 0xffff, 0xffff, 0xffff, 0xffff, 0xffff,
	0xffff, 0xffff, 0xffff, 0x10c3, 0x10c3, 0x10c3, 0x10c3, 0x10c3, 0x10c3, 0x10c3, 0x10c3, 0x10c3, 0x10c3, 0x10c3, 0x10c3, 0x10c3,
	0x10c3, 0xffff, 0xffff, 0xffff, 0xffff, 0x0d0a, 0x0d0a, 0x0d0a, 0x0d0a, 0x0d0a, 0x0d0a, 0x0d0a, 0x0d0a, 0x0d0a, 0x0d0a, 0x0d0a,
	0x0d0a, 0x0d0a, 0x0d0a, 0x2d6d, 0xc75a, 0xc759, 0xffff, 0xffff, 0xc75a, 0xc75a, 0xc75a, 0x0d09, 0x0d0a, 0x0d0a, 0x0d0a, 0x0d0a,
	0x0d0a, 0x0d0a, 0x0d0a, 0x0d0a, 0xffff, 0xffff, 0xffff, 0xffff, 0x0d0a, 0x0d0a, 0x0d0a, 0x0d0a, 0x0d0a, 0x0d0a, 0x0d0a, 0x0d0a,
	0x0d0a, 0x0d0a, 0x0d0a, 0x0d0a, 0x0d0a, 0x0d0a, 0x0d0a, 0x0d0a, 0xffff, 0xffff, 0xffff, 0xffff, 0x0509, 0x0d0a, 0x0d0a, 0x0d0a,
	0x0d0a, 0x0d0a, 0x0d0a, 0x0d0a, 0x0d0a, 0xc75a, 0xc75a, 0xc75a, 0xffff, 0xffff, 0xf7de, 0xc75a, 0xb719, 0x0d0a, 0x0d0a, 0x0d0a,
	0x0d0a, 0x0d0a, 0x0d0a, 0x0d0a, 0x0d0a, 0x0d0a, 0x0d0a, 0x0d0a, 0x0d0a, 0x0d0a, 0x0d29, 0xffff, 0xffff, 0xffff, 0x10c3, 0x10c3,
	0x10a3, 0x2986, 0x3a08, 0x10c3, 0x10c3, 0x10c3, 0xffff, 0xffff, 0xffff, 0xffff, 0xffff, 0xffff, 0xffff, 0xffff, 0xffff, 0xffff,
	0xffff, 0xffff, 0xffff, 0xffff, 0xffff, 0x0509, 0x0d0a, 0x0d0a, 0xffff, 0xffff, 0xffff, 0x10a3, 0x10c3, 0x10a3, 0xffff, 0xffff,
	0xffff, 0xffff, 0xffff, 0x10c3, 0x10c3, 0x10a2, 0xffff, 0xffff, 0x55f0, 0x0d0a, 0x0d0a, 0xffff, 0xffff, 0xffff, 0xffff, 0xffff,
	0xffff, 0xffff, 0xffff, 0x10a3, 0x10a2, 0x10c3, 0x10a2, 0x10c3, 0x10c3, 0x10c3, 0x10c3, 0x10c3, 0x10c3, 0x10c3, 0x10c3, 0x10c3,
	0x10c3, 0x10c3, 0xffff, 0xffff, 0xffff, 0xffff, 0x0d0a, 0x0d0a, 0x0d0a, 0x0d0a, 0x0d0a, 0x0d0a, 0x0d0a, 0x0d0a, 0x0d0a, 0x0d0a,
	0x0d0a, 0x0d0a, 0x0d09, 0xffff, 0xffff, 0xffff, 0xffff, 0xffff, 0xffff, 0xffff, 0xffff, 0x0d0a, 0x0d0a, 0x0d0a, 0x0d0a, 0x0d0a,
	0x0d0a, 0x0d0a, 0x0d0a, 0xffff, 0xffff, 0xffff, 0xffff, 0xffff, 0xffff, 0x0d0a, 0x0d0a, 0x0d0a, 0x0d0a, 0x0d0a, 0x0d0a, 0x0d0a,
	0x0d0a, 0x0d0a, 0x0d0a, 0x0d0a, 0x0d0a, 0x0d0a, 0x0d2a, 0xffff, 0xffff, 0xffff, 0xffff, 0xffff, 0xffff, 0x6632, 0x0d0a, 0x0d0a,
	0x0d0a, 0x0d0a, 0x0d0a, 0x0d0a, 0x0d0a, 0xffff, 0xffff, 0xffff, 0xffff, 0xffff, 0xffff, 0xffff, 0xffff, 0x0509, 0x0d0a, 0x0d0a,
	0x0d0a, 0x0d0a, 0x0d0a, 0x0d0a, 0x0d0a, 0x0d0a, 0x0d0a, 0x0d0a, 0x0d0a, 0x0d2a, 0xffff, 0xffff, 0xffff, 0xffff, 0x10c3, 0x10c3,
	0xffff, 0xffff, 0xffff, 0x7bef, 0x10c3, 0x10c3, 0xffff, 0xffff, 0xffff, 0xffff, 0xffff, 0x10a3, 0xffff, 0xffff, 0xffff, 0xffff,
	0xffff, 0xffff, 0xffff, 0xffff, 0xffff, 0x0d0a, 0x0d0a, 0x0509, 0xffff, 0xffff, 0x3a08, 0x10c3, 0x10c3, 0xffff, 0xffff, 0xffff,
	0xffff, 0xffff, 0xffff, 0x10c3, 0x10c3, 0x10c3, 0xffff, 0xffff, 0xffff, 0x0d0a, 0x0d0a, 0x256c, 0xffff, 0xffff, 0xffff, 0xffff,
	0xffff, 0xffff, 0xffff, 0xffff, 0xffff, 0xffff, 0xffff, 0xffff, 0xffff, 0xffff, 0xffff, 0xffff, 0xffff, 0xffff, 0xffff, 0xffff,
	0xffff, 0xffff, 0xffff, 0xffff, 0xffff, 0xffff, 0xa6f7, 0x0d0a, 0x0d0a, 0x0d0a, 0x0d0a, 0x0d0a, 0x0d0a, 0x0d0a, 0x0d0a, 0x0d0a,
	0x0d0a, 0x0d0a, 0x0d0a, 0x0d0a, 0x0d0a, 0xffff, 0xffff, 0xffff, 0x0d0a, 0x0d0a, 0x0d0a, 0x0d0a, 0x0d0a, 0x0d0a, 0x0d0a, 0x0d0a,
	0x0d0a, 0x0d0a, 0xffff, 0xffff, 0xffff, 0xffff, 0xffff, 0xffff, 0xffff, 0xffff, 0x0d0a, 0x0d0a, 0x0d0a, 0x0d0a, 0x0d0a, 0x0d0a,
	0x0d0a, 0x0d0a, 0x0d0a, 0x0d0a, 0x0d0a, 0x0d0a, 0xffff, 0xffff, 0xffff, 0xffff, 0xffff, 0xffff, 0xffff, 0xffff, 0x8694, 0x0d0a,
	0x0d0a, 0x0d0a, 0x0d0a, 0x0d0a, 0x0d0a, 0x0d0a, 0x0d0a, 0x0d09, 0xffff, 0xffff, 0xffff, 0x0529, 0x0d0a, 0x0d0a, 0x0d0a, 0x0d0a,
	0x0d0a, 0x0d0a, 0x0d0a, 0x0d0a, 0x0d0a, 0x0d0a, 0x0d0a, 0x0d0a, 0x0d0a, 0x0d0a, 0xffff, 0xffff, 0xffff, 0x8c51, 0x10c3, 0x10c3,
	0xffff, 0xffff, 0xffff, 0xffff, 0x10c3, 0x10c3, 0xffff, 0xffff, 0xffff, 0xe71c, 0x10c3, 0x10a3, 0xffff, 0xffff, 0xffff, 0xffff,
	0xffff, 0xffff, 0xffff, 0xffff, 0xf7be, 0x0d0a, 0x0d0a, 0xffff, 0xffff, 0xffff, 0x10a3, 0x10c3, 0x10c3, 0xffff, 0xffff, 0xffff,
	0xffff, 0xffff, 0xffff, 0x10a3, 0x10c3, 0x10c3, 0xffff, 0xffff, 0xffff, 0x0d2a, 0x0d0a, 0x0d0a, 0xffff, 0xffff, 0xffff, 0xffff,
	0xffff, 0xffff, 0xffff, 0xffff, 0xffff, 0xffff, 0xffff, 0xffff, 0xffff, 0xffff, 0xffff, 0xffff, 0xffff, 0xffff, 0xffff, 0xffff,
	0xffff, 0xffff, 0xffff, 0xffff, 0xffff, 0xffff, 0xffff, 0x0d0a, 0x0d0a, 0x0d0a, 0x0d0a, 0x0d0a, 0x0d0a, 0x0d0a, 0x0d0a, 0x0d0a,
	0x0d0a, 0x0d0a, 0x0d0a, 0x0d0a, 0xffff, 0xffff, 0xffff, 0xffff, 0x0d0a, 0xffff, 0xffff, 0x0d0a, 0x0d0a, 0x0d0a, 0x0d0a, 0x0d0a,
	0x0d0a, 0xffff, 0xffff, 0xffff, 0xffff, 0xffff, 0xffff, 0xffff, 0xffff, 0xffff, 0xffff, 0x0d0a, 0x0d0a, 0x0d0a, 0x0d0a, 0x0d0a,
	0x0d0a, 0x0d0a, 0x0d0a, 0x0d0a, 0x0d0a, 0x5610, 0xffff, 0xffff, 0xffff, 0xffff, 0xffff, 0xffff, 0xffff, 0xffff, 0xffff, 0x0d0a,
	0x0d0a, 0x0d0a, 0x0d0a, 0x0d0a, 0x0d0a, 0xf7de, 0xffff, 0x0529, 0xffff, 0xffff, 0xffff, 0xffff, 0x0d0a, 0x0d0a, 0x0d0a, 0x0d0a,
	0x0d0a, 0x0d0a, 0x0d0a, 0x0d0a, 0x0d0a, 0x0d0a, 0x0d0a, 0x0d0a, 0x0d0a, 0xffff, 0xffff, 0xffff, 0xffff, 0xffff, 0x10c3, 0x10c3,
	0xffff, 0xffff, 0xffff, 0xffff, 0x10c3, 0x10c3, 0xffff, 0xffff, 0xffff, 0xffff, 0x10a3, 0x10c3, 0xffff, 0xffff, 0xffff, 0xffff,
	0xffff, 0xffff, 0xffff, 0xffff, 0x0d2a, 0x0d0a, 0x0d09, 0xffff, 0xffff, 0xffff, 0x10c3, 0x10c3, 0x10c3, 0xffff, 0xffff, 0xffff,
	0xffff, 0xffff, 0xffff, 0xffff, 0x10c3, 0x10c3, 0x10a3, 0xffff, 0xffff, 0xffff, 0x0d0a, 0x0d0a, 0xffff, 0xffff, 0xffff, 0xffff,
	0xffff, 0xffff, 0xffff, 0xffff, 0xffff, 0xffff, 0xffff, 0xffff, 0xffff, 0xffff, 0xffff, 0xffff, 0xffff, 0xffff, 0xffff, 0xffff,
	0xffff, 0xef9e, 0x10c3, 0x10c3, 0xffff, 0xffff, 0xffff, 0xffff, 0x0d0a, 0x0d0a, 0x0d0a, 0x0d0a, 0x0d0a, 0x0d0a, 0x0d0a, 0x0d0a,
	0x0d0a, 0x0d0a, 0x0d0a, 0x0d0a, 0xffff, 0xffff, 0xffff, 0xffff, 0xffff, 0xffff, 0xffff, 0x0d0a, 0x0d0a, 0x0d0a, 0x0d0a, 0x0d0a,
	0x0d0a, 0xffff, 0xffff, 0xffff, 0xffff, 0xffff, 0xffff, 0xffff, 0xffff, 0xffff, 0xffff, 0x0d0a, 0x0d0a, 0x0d0a, 0x0d0a, 0x0d0a,
	0x0d0a, 0x0d0a, 0x0d0a, 0x0d0a, 0x0d0a, 0xffff, 0xffff, 0xffff, 0xffff, 0xffff, 0xffff, 0xffff, 0xffff, 0xffff, 0xffff, 0x0d0a,
	0x0d0a, 0x0d0a, 0x0d0a, 0x0d0a, 0x0d0a, 0xffff, 0xffff, 0xffff, 0xffff, 0xffff, 0xffff, 0xffff, 0x0d0a, 0x0d0a, 0x0d0a, 0x0d0a,
	0x0d0a, 0x0d0a, 0x0d0a, 0x0d0a, 0x0d0a, 0x0d0a, 0x0d0a, 0x0d2a, 0xffff, 0xffff, 0xffff, 0xffff, 0xffff, 0xffff, 0x10a3, 0xffff,
	0xffff, 0xffff, 0xffff, 0xffff, 0x10c3, 0x10c3, 0x10c3, 0xffff, 0xffff, 0x10c3, 0x10c3, 0x10a2, 0xffff, 0xffff, 0xffff, 0xffff,
	0xffff, 0xffff, 0xffff, 0xffff, 0x0d0a, 0x0d0a, 0x96b6, 0xffff, 0xffff, 0x10a2, 0x10c3, 0x10c3, 0xffff, 0xffff, 0xffff, 0xffff,
	0xffff, 0xffff, 0xffff, 0xffff, 0x10c3, 0x10c3, 0x10a2, 0xffff, 0xffff, 0xffff, 0x0d0a, 0x0d0a, 0x0509, 0xffff, 0xffff, 0xffff,
	0xffff, 0xffff, 0xffff, 0xffff, 0xffff, 0xffff, 0xffff, 0xffff, 0xffff, 0xffff, 0xffff, 0xffff, 0xffff, 0xffff, 0xffff, 0xffff,
	0x10a2, 0x10c3, 0x10c3, 0x10c3, 0x2124, 0xffff, 0xffff, 0xffff, 0xffff, 0x0d0a, 0x0d0a, 0x0d0a, 0x0d0a, 0x0d0a, 0x0d0a, 0x0d0a,
	0x0d0a, 0x0d0a, 0x0d0a, 0x0d0a, 0x0d0a, 0xffff, 0xffff, 0xffff, 0xffff, 0xffff, 0x0d2a, 0x0d0a, 0x0d0a, 0x0d0a, 0x0d0a, 0x0d0a,
	0x0d0a, 0xffff, 0xffff, 0xffff, 0xffff, 0xffff, 0xffff, 0xffff, 0xffff, 0xffff, 0x3d8e, 0x0d0a, 0x0d0a, 0x0d0a, 0x0d0a, 0x0d0a,
	0x0d0a, 0x0d0a, 0x0d0a, 0x0d0a, 0x0d0a, 0x0d2a, 0xffff, 0xffff, 0xffff, 0xffff, 0xffff, 0xffff, 0xffff, 0xffff, 0xffff, 0x0d0a,
	0x0d0a, 0x0d0a, 0x0d0a, 0x0d0a, 0x0d0a, 0x0d0a, 0xffff, 0xffff, 0xffff, 0xffff, 0xffff, 0x0d09, 0x0d0a, 0x0d0a, 0x0d0a, 0x0d0a,
	0x0d0a, 0x0d0a, 0x0d0a, 0x0d0a, 0x0d0a, 0x0d0a, 0x0d0a, 0xf7de, 0xffff, 0xffff, 0xffff, 0xffff, 0xffff, 0xffff, 0xffff, 0xffff,
	0xffff, 0xffff, 0xffff, 0xffff, 0x10c3, 0x10c3, 0x10c3, 0x10c3, 0x10a2, 0x10c3, 0x10c3, 0xffff, 0xffff, 0xffff, 0xffff, 0xffff,
	0xffff, 0xffff, 0xffff, 0x050a, 0x0d0a, 0x0d2a, 0xffff, 0xffff, 0xffff, 0x10c3, 0x10c3, 0x10c3, 0xffff, 0xffff, 0xffff, 0xffff,
	0xffff, 0xffff, 0xffff, 0xffff, 0xffff, 0x10c3, 0x10c3, 0x10a3, 0xffff, 0xffff, 0xe79d, 0x0d0a, 0x0d0a, 0xffff, 0xffff, 0xffff,
	0xffff, 0xffff, 0xffff, 0xffff, 0xffff, 0xffff, 0xffff, 0xffff, 0xffff, 0xffff, 0xffff, 0xffff, 0xffff, 0xffff, 0x10c3, 0x10c3,
	0x10c3, 0x10c3, 0x10a2, 0x10c3, 0x10c3, 0xffff, 0xffff, 0xffff, 0xffff, 0x0d09, 0x0d0a, 0x0d0a, 0x0d0a, 0x0d0a, 0x0d0a, 0x0d0a,
	0x0d0a, 0x0d0a, 0x0d0a, 0x0d0a, 0x0d0a, 0x0509, 0xffff, 0xffff, 0xffff, 0x0d0a, 0x0d0a, 0x0d0a, 0x0d0a, 0x0d0a, 0x0d0a, 0x0d0a,
	0x0d0a, 0x050a, 0xffff, 0xffff, 0xffff, 0xffff, 0xffff, 0xffff, 0xffff, 0xffff, 0x0d0a, 0x0d0a, 0x0d0a, 0x0d0a, 0x0d0a, 0x0d0a,
	0x0d0a, 0x0d0a, 0x0d0a, 0x0d0a, 0x0d0a, 0x0d0a, 0xffff, 0xffff, 0xffff, 0xffff, 0xffff, 0xffff, 0xffff, 0xffff, 0x0d0a, 0x0d0a,
	0x0d0a, 0x0d0a, 0x0d0a, 0x0d0a, 0x0d0a, 0x0d0a, 0x0d2a, 0x96b6, 0xffff, 0xffff, 0x0d09, 0x0d0a, 0x0d0a, 0x0d0a, 0x0d0a, 0x0d0a,
	0x0d0a, 0x0d0a, 0x0d0a, 0x0d0a, 0x0d0a, 0x0d0a, 0x0d2a, 0xffff, 0xffff, 0xffff, 0xffff, 0x10c3, 0x10c3, 0xffff, 0xffff, 0xffff,
	0xffff, 0xffff, 0xffff, 0xffff, 0xffff, 0x10c3, 0x10c3, 0x10c3, 0x10c3, 0x10c3, 0xef9e, 0xffff, 0xffff, 0xffff, 0xffff, 0xffff,
	0xffff, 0xffff, 0xffff, 0x0d0a, 0x0d0a, 0x256c, 0xffff, 0xffff, 0x9cd3, 0x10c3, 0x10c3, 0xffff, 0xffff, 0xffff, 0xffff, 0xffff,
	0xffff, 0xffff, 0xffff, 0xffff, 0xffff, 0x10c3, 0x10c3, 0x10c3, 0xffff, 0xffff, 0xffff, 0x0d0a, 0x0d0a, 0x0d0a, 0xffff, 0xffff,
	0xffff, 0xffff, 0xffff, 0xffff, 0xffff, 0xffff, 0xffff, 0xffff, 0xffff, 0xffff, 0xffff, 0xa554, 0x10c3, 0x10c3, 0x10c3, 0x10c3,
	0x10c3, 0xffff, 0xffff, 0x10c3, 0x10c3, 0x10c3, 0xffff, 0xffff, 0xffff, 0xffff, 0x0d09, 0x0d0a, 0x0d0a, 0x0d0a, 0x0d0a, 0x0d0a,
	0x0d0a, 0x0d0a, 0x0d0a, 0x0d0a, 0x0d0a, 0x0d0a, 0x35ae, 0xffff, 0x0529, 0x0d0a, 0x0d0a, 0x0d0a, 0x0d0a, 0x0d0a, 0x0d0a, 0x0d0a,
	0x0d0a, 0x0d0a, 0x050a, 0xffff, 0xffff, 0xffff, 0xffff, 0xffff, 0xffff, 0x0d09, 0x0d0a, 0x0d0a, 0x0d0a, 0x0d0a, 0x0d0a, 0x0d0a,
	0x0d0a, 0x0d0a, 0x0d0a, 0x0d0a, 0x0d0a, 0x0d0a, 0x0d0a, 0xffff, 0xffff, 0xffff, 0xffff, 0xffff, 0xffff, 0x0d2a, 0x0d0a, 0x0d0a,
	0x0d0a, 0x0d0a, 0x0d0a, 0x0d0a, 0x0d0a, 0x0d0a, 0x0d0a, 0x0d0a, 0xffff, 0xffff, 0x0d0a, 0x0d0a, 0x0d0a, 0x0d0a, 0x0d0a, 0x0d0a,
	0x0d0a, 0x0d0a, 0x0d0a, 0x0d0a, 0x0d0a, 0x0d0a, 0xffff, 0xffff, 0xffff, 0xffff, 0x10a2, 0x10c3, 0x10c3, 0xffff, 0xffff, 0xffff,
	0xffff, 0xffff, 0xffff, 0xffff, 0xffff, 0xffff, 0xffff, 0xffff, 0xffff, 0xffff, 0xffff, 0xffff, 0xffff, 0xffff, 0xffff, 0xffff,
	0xffff, 0xffff, 0x0d09, 0x0d0a, 0x0d0a, 0xffff, 0xffff, 0xffff, 0x10c3, 0x10c3, 0x10c3, 0xffff, 0xffff, 0xffff, 0xffff, 0xffff,
	0xffff, 0xffff, 0xffff, 0xffff, 0xffff, 0xffff, 0x10c3, 0x10c3, 0x10a2, 0xffff, 0xffff, 0xffff, 0x0d0a, 0x0d0a, 0xffff, 0xffff,
	0xffff, 0xffff, 0xffff, 0xffff, 0xffff, 0xffff, 0xffff, 0xffff, 0xffff, 0xc638, 0x10c3, 0x10c3, 0x10c3, 0x10c3, 0x10c3, 0x10a2,
	0xffff, 0xffff, 0xffff, 0xffff, 0x10c3, 0x10c3, 0x10a2, 0xffff, 0xffff, 0xffff, 0xffff, 0x0d2a, 0x0d0a, 0x0d0a, 0x0d0a, 0x0d0a,
	0x0d0a, 0x0d0a, 0x0d0a, 0x0d0a, 0x0d0a, 0x0d0a, 0x0d29, 0x0d0a, 0x0d0a, 0x0d0a, 0x0d0a, 0x0d0a, 0x0d0a, 0x0d0a, 0x0d0a, 0x0d0a,
	0x0d0a, 0x0d0a, 0x0d0a, 0x0d0a, 0x0d0a, 0x0509, 0x0d09, 0x0d0a, 0x0d0a, 0x0d0a, 0x0d0a, 0x0d0a, 0x0d0a, 0x0d0a, 0x0d0a, 0x0d0a,
	0x0d0a, 0x0d0a, 0x0d0a, 0x0d0a, 0x0d0a, 0x0d0a, 0x0d0a, 0x0d0a, 0x0d0a, 0x0d2a, 0x0509, 0x0d0a, 0x0d0a, 0x0d0a, 0x0d0a, 0x0d0a,
	0x0d0a, 0x0d0a, 0x0d0a, 0x0d0a, 0x0d0a, 0x0d0a, 0x0d0a, 0x0d0a, 0x0d0a, 0x0d2a, 0x0d0a, 0x0d0a, 0x0d0a, 0x0d0a, 0x0d0a, 0x0d0a,
	0x0d0a, 0x0d0a, 0x0d0a, 0x0d0a, 0x0d09, 0xffff, 0xffff, 0xffff, 0xffff, 0xffff, 0xffff, 0x10c3, 0x10c3, 0x10c3, 0xffff, 0xffff,
	0xffff, 0xffff, 0xffff, 0xffff, 0xffff, 0xffff, 0xffff, 0xffff, 0xffff, 0xffff, 0xffff, 0xffff, 0xffff, 0xffff, 0xffff, 0xffff,
	0xffff, 0xffff, 0x0d0a, 0x0d0a, 0xa6d7, 0xffff, 0xffff, 0x6b6d, 0x10c3, 0x10c3, 0xef9d, 0xffff, 0xffff, 0xffff, 0xffff, 0xffff,
	0xffff, 0xffff, 0xffff, 0xffff, 0xffff, 0xffff, 0x10a3, 0x10c3, 0x10c3, 0xffff, 0xffff, 0xffff, 0x0d0a, 0x0d0a, 0x0d0a, 0xffff,
	0xffff, 0xffff, 0xffff, 0xffff, 0xffff, 0xffff, 0xffff, 0xc638, 0x10c3, 0x10c3, 0x10c3, 0x10c3, 0x10a2, 0xffff, 0x10c3, 0x10c3,
	0x10c3, 0xffff, 0xffff, 0xffff, 0xffff, 0x10c3, 0x10c3, 0xffff, 0xffff, 0xffff, 0xffff, 0xffff, 0x0509, 0x0d2a, 0x0d0a, 0x0d0a,
	0x0d0a, 0x0d0a, 0x0d0a, 0x0d0a, 0x0d0a, 0x0d0a, 0x0d0a, 0x0d0a, 0x0d0a, 0x0d0a, 0x0d0a, 0x0d0a, 0x0d0a, 0x0d0a, 0x0d0a, 0x0d0a,
	0x0d0a, 0x0d0a, 0x0d0a, 0x0d0a, 0x0d0a, 0x0d0a, 0x0d0a, 0x0d0a, 0x0d0a, 0x0d0a, 0x0d0a, 0x0d0a, 0x0d0a, 0x0d0a, 0x0d0a, 0x0d0a,
	0x0d0a, 0x0d0a, 0x0d0a, 0x0d0a, 0x0d0a, 0x0d0a, 0x0d0a, 0x0d0a, 0x0d0a, 0x0d0a, 0x0d0a, 0x0d0a, 0x0d0a, 0x0d0a, 0x0d0a, 0x0d0a,
	0x0d0a, 0x0d0a, 0x0d0a, 0x0d0a, 0x0d0a, 0x0d0a, 0x0d0a, 0x0d0a, 0x0d0a, 0x0d0a, 0x0d0a, 0x0d0a, 0x0d0a, 0x0d0a, 0x0d0a, 0x0d0a,
	0x0d0a, 0x0d0a, 0x0d0a, 0x0d2a, 0xffff, 0xffff, 0xffff, 0xffff, 0xffff, 0xffff, 0xffff, 0x10c3, 0x10c3, 0x10c3, 0xa535, 0xffff,
	0xffff, 0xffff, 0xffff, 0xffff, 0xffff, 0xffff, 0xffff, 0xffff, 0xffff, 0xffff, 0xffff, 0xffff, 0xffff, 0xffff, 0xffff, 0xffff,
	0xffff, 0x0d0a, 0x0d0a, 0x0d2a, 0xffff, 0xffff, 0xffff, 0x10a2, 0x10c3, 0x10c3, 0xffff, 0xffff, 0xffff, 0xffff, 0xffff, 0xffff,
	0xffff, 0xffff, 0xffff, 0xffff, 0xffff, 0xffff, 0xffff, 0x10c3, 0x10c3, 0x10a3, 0xffff, 0xffff, 0xffff, 0x0d0a, 0x0d0a, 0x8694,
	0xffff, 0xffff, 0xffff, 0xffff, 0xffff, 0xffff, 0xffff, 0xffff, 0x10a3, 0x10c3, 0x10c3, 0xffff, 0xffff, 0xffff, 0x10a3, 0x10c3,
	0x10c3, 0xffff, 0xffff, 0xffff, 0xffff, 0xffff, 0xffff, 0xffff, 0xffff, 0xffff, 0xffff, 0xffff, 0xffff, 0x6632, 0x0d0a, 0x0d0a,
	0x0d0a, 0x0d0a, 0x0d0a, 0x0d0a, 0x0d0a, 0x0d0a, 0x0d0a, 0x0d0a, 0x0d0a, 0x0d0a, 0x0d0a, 0x0d0a, 0x0d0a, 0x0d0a, 0x0d0a, 0x0d0a,
	0x0d0a, 0x0d0a, 0x0d0a, 0x0d0a, 0x0d0a, 0x0d0a, 0x0d0a, 0x0d0a, 0x0d0a, 0x0d0a, 0x0d0a, 0x0d0a, 0x0d0a, 0x0d0a, 0x0d0a, 0x0d0a,
	0x0d0a, 0x0d0a, 0x0d0a, 0x0d0a, 0x0d0a, 0x0d0a, 0x0d0a, 0x0d0a, 0x0d0a, 0x0d0a, 0x0d0a, 0x0d0a, 0x0d0a, 0x0d0a, 0x0d0a, 0x0d0a,
	0x0d0a, 0x0d0a, 0x0d0a, 0x0d0a, 0x0d0a, 0x0d0a, 0x0d0a, 0x0d0a, 0x0d0a, 0x0d0a, 0x0d0a, 0x0d0a, 0x0d0a, 0x0d0a, 0x0d0a, 0x0d0a,
	0x0d0a, 0x0d0a, 0x0d0a, 0xffff, 0xffff, 0xffff, 0xffff, 0x10a3, 0x10a2, 0xef9e, 0xffff, 0xffff, 0x10a2, 0x10c3, 0x10a2, 0x10c3,
	0x10c3, 0x10c3, 0x10c3, 0x10c3, 0xffff, 0xffff, 0xffff, 0xffff, 0xffff, 0xffff, 0xffff, 0xffff, 0xffff, 0xffff, 0xffff, 0xffff,
	0xffff, 0x0d0a, 0x0d0a, 0xffff, 0xffff, 0xffff, 0x2986, 0x10c3, 0x10c3, 0xc638, 0xffff, 0xffff, 0xffff, 0xffff, 0xffff, 0xffff,
	0xffff, 0xffff, 0xffff, 0xffff, 0xffff, 0xffff, 0xffff, 0x10a2, 0x10c3, 0x10c3, 0xffff, 0xffff, 0xffff, 0x0d2a, 0x0d0a, 0x0d2a,
	0xffff, 0xffff, 0xffff, 0xffff, 0xffff, 0xffff, 0xffff, 0xffff, 0xffff, 0x10a2, 0x10c3, 0x10c3, 0xffff, 0xffff, 0xffff, 0x10a3,
	0x10c3, 0x10a2, 0xffff, 0xffff, 0xffff, 0xffff, 0xffff, 0xffff, 0xffff, 0x10a3, 0xffff, 0xffff, 0xffff, 0xffff, 0xffff, 0x0d0a,
	0x0d0a, 0x0d0a, 0x0d0a, 0x0d0a, 0x0d0a, 0x0d0a, 0x0d0a, 0x0d0a, 0x0d0a, 0x0d0a, 0x0d0a, 0x0d0a, 0x0d0a, 0x0d0a, 0x0d0a, 0x0d0a,
	0x0d0a, 0x0d0a, 0x0d0a, 0x0d0a, 0x0d0a, 0x0d0a, 0x0d0a, 0x0d0a, 0x0d0a, 0x0d0a, 0x0d0a, 0x0d0a, 0x0d0a, 0x0d0a, 0x0d0a, 0x0d0a,
	0x0d0a, 0x0d0a, 0x0d0a, 0x0d0a, 0x0d0a, 0x0d0a, 0x0d0a, 0x0d0a, 0x0d0a, 0x0d0a, 0x0d0a, 0x0d0a, 0x0d0a, 0x0d0a, 0x0d0a, 0x0d0a,
	0x0d0a, 0x0d0a, 0x0d0a, 0x0d0a, 0x0d0a, 0x0d0a, 0x0d0a, 0x0d0a, 0x0d0a, 0x0d0a, 0x0d0a, 0x0d0a, 0x0d0a, 0x0d0a, 0x0d0a, 0x0d0a,
	0x0d0a, 0xffff, 0xffff, 0xffff, 0xffff, 0xffff, 0x10a2, 0x10c3, 0x10c3, 0x10c3, 0x10a2, 0xffff, 0x6b6d, 0x10c3, 0x10c3, 0x10c3,
	0x10a3, 0x10a2, 0x10c3, 0x10c3, 0x10c3, 0xffff, 0xffff, 0xffff, 0xffff, 0xffff, 0xffff, 0xffff, 0xffff, 0xffff, 0xffff, 0xffff,
	0x0d0a, 0x0d0a, 0x0d0a, 0xffff, 0xffff, 0xffff, 0x10c3, 0x10c3, 0x10a2, 0xffff, 0xffff, 0xffff, 0xffff, 0xffff, 0xffff, 0xffff,
	0xffff, 0xffff, 0xffff, 0xffff, 0xffff, 0xffff, 0xffff, 0xffff, 0x10a2, 0x10c3, 0x10c3, 0xffff, 0xffff, 0xffff, 0x052a, 0x0d0a,
	0x0529, 0xffff, 0xffff, 0xffff, 0xffff, 0xffff, 0xffff, 0xffff, 0xffff, 0xffff, 0x10c3, 0x10c3, 0x10c3, 0xffff, 0xffff, 0xffff,
	0x10a2, 0xffff, 0xffff, 0xffff, 0xffff, 0xffff, 0xffff, 0xffff, 0x10c3, 0x10c3, 0x10c3, 0xffff, 0xffff, 0xffff, 0xffff, 0xffff,
	0x0d2a, 0x0d0a, 0x0d0a, 0x0d0a, 0x0d0a, 0x0d0a, 0x0d0a, 0x0d0a, 0x0d0a, 0x0d0a, 0x0d0a, 0x0d0a, 0x0d0a, 0x0d0a, 0x0d0a, 0x0d0a,
	0x0d0a, 0x0d0a, 0x0d0a, 0x0d0a, 0x0d0a, 0x0d0a, 0x0d0a, 0x0d0a, 0x0d0a, 0x0d0a, 0x0d0a, 0x0d0a, 0x0d0a, 0x0d0a, 0x0d0a, 0x0d0a,
	0x0d0a, 0x0d0a, 0x0d0a, 0x0d0a, 0x0d0a, 0x0d0a, 0x0d0a, 0x0d0a, 0x0d0a, 0x0d0a, 0x0d0a, 0x0d0a, 0x0d0a, 0x0d0a, 0x0d0a, 0x0d0a,
	0x0d0a, 0x0d0a, 0x0d0a, 0x0d0a, 0x0d0a, 0x0d0a, 0x0d0a, 0x0d0a, 0x0d0a, 0x0d0a, 0x0d0a, 0x0d0a, 0x0d0a, 0x0d0a, 0x0d0a, 0x050a,
	0xffff, 0xffff, 0xffff, 0xffff, 0xffff, 0xffff, 0xffff, 0xffff, 0x10a2, 0x10c3, 0x10c3, 0x10c3, 0x10c3, 0x10c3, 0x10a2, 0xffff,
	0xffff, 0xffff, 0x10a3, 0x10c3, 0x10c3, 0xffff, 0xffff, 0xffff, 0xffff, 0xffff, 0xffff, 0xffff, 0xffff, 0xffff, 0xffff, 0x0d0a,
	0x0d0a, 0x0d0a, 0xffff, 0xffff, 0xffff, 0x10c3, 0x10c3, 0x10c3, 0xffff, 0xffff, 0xffff, 0xffff, 0xffff, 0xffff, 0xffff, 0xffff,
	0xffff, 0xffff, 0xffff, 0xffff, 0xffff, 0xffff, 0xffff, 0xffff, 0x10a2, 0x10c3, 0x10c3, 0x7bef, 0xffff, 0xffff, 0xffff, 0x0d0a,
	0x0d0a, 0x0d09, 0xffff, 0xffff, 0xffff, 0xffff, 0xffff, 0xffff, 0xffff, 0xffff, 0xc638, 0x10c3, 0x10c3, 0x7bef, 0xffff, 0xffff,
	0xffff, 0xffff, 0xffff, 0xffff, 0xffff, 0xffff, 0xffff, 0x10c3, 0x10c3, 0x10c3, 0x10c3, 0x10a2, 0xffff, 0xffff, 0xffff, 0xffff,
	0xffff, 0x154b, 0x0d0a, 0x0d0a, 0x0d0a, 0x0d0a, 0x0d0a, 0x0d0a, 0x0d0a, 0x0d0a, 0x0d0a, 0x0d0a, 0x0d0a, 0x0d0a, 0x0d0a, 0x0d0a,
	0x0d0a, 0x0d0a, 0x0d0a, 0x0d0a, 0x0d0a, 0x0d0a, 0x0d0a, 0x0d0a, 0x0d0a, 0x0d0a, 0x0d0a, 0x0d0a, 0x0d0a, 0x0d0a, 0x0d0a, 0x0d0a,
	0x0d0a, 0x0d0a, 0x0d0a, 0x0d0a, 0x0d0a, 0x0d0a, 0x0d0a, 0x0d0a, 0x0d0a, 0x0d0a, 0x0d0a, 0x0d0a, 0x0d0a, 0x0d0a, 0x0d0a, 0x0d0a,
	0x0d0a, 0x0d0a, 0x0d0a, 0x0d0a, 0x0d0a, 0x0d0a, 0x0d0a, 0x0d0a, 0x0d0a, 0x0d0a, 0x0d0a, 0x0d0a, 0x0d0a, 0x0d0a, 0x0d09, 0xffff,
	0xffff, 0xffff, 0xffff, 0xffff, 0xffff, 0xffff, 0xffff, 0xffff, 0xffff, 0x9cd3, 0x10c3, 0x10c3, 0x10c3, 0x10c3, 0x10a3, 0xffff,
	0xffff, 0xffff, 0xa555, 0x10c3, 0x10c3, 0xffff, 0xffff, 0xffff, 0xffff, 0xffff, 0xffff, 0xffff, 0xffff, 0xffff, 0x96d6, 0x0d0a,
	0x0d0a, 0xffff, 0xffff, 0xffff, 0xffff, 0x10c3, 0x10c3, 0x10a2, 0xffff, 0xffff, 0xffff, 0xffff, 0xffff, 0xffff, 0xffff, 0xffff,
	0xffff, 0xffff, 0xffff, 0xffff, 0xffff, 0xffff, 0xffff, 0xffff, 0xffff, 0x10c3, 0x10c3, 0x10c3, 0xffff, 0xffff, 0xffff, 0x0d2a,
	0x0d0a, 0x0d0a, 0xffff, 0xffff, 0xffff, 0xffff, 0xffff, 0xffff, 0xffff, 0xffff, 0xffff, 0x10c3, 0x10a2, 0xffff, 0xffff, 0xffff,
	0xffff, 0xffff, 0xffff, 0xffff, 0xffff, 0xd69a, 0x10c3, 0x10c3, 0x10c3, 0x10c3, 0x10c3, 0x10c3, 0x10c3, 0x10a2, 0xffff, 0xffff,
	0xffff, 0xffff, 0xffff, 0x0d0a, 0x0d0a, 0x0d0a, 0x0d0a, 0x0d0a, 0x0d0a, 0x0d0a, 0x0d0a, 0x0d0a, 0x0d0a, 0x0d0a, 0x0d0a, 0x0d0a,
	0x0d0a, 0x0d0a, 0x0d0a, 0x0d0a, 0x0d0a, 0x0d0a, 0x0d0a, 0x0d0a, 0x0d0a, 0x0d0a, 0x0d0a, 0x0d0a, 0x0d0a, 0x0d0a, 0x0d0a, 0x0d0a,
	0x0d0a, 0x0d0a, 0x0d0a, 0x0d0a, 0x0d0a, 0x0d0a, 0x0d0a, 0x0d0a, 0x0d0a, 0x0d0a, 0x0d0a, 0x0d0a, 0x0d0a, 0x0d0a, 0x0d0a, 0x0d0a,
	0x0d0a, 0x0d0a, 0x0d0a, 0x0d0a, 0x0d0a, 0x0d0a, 0x0d0a, 0x0d0a, 0x0d0a, 0x0d0a, 0x0d0a, 0x0d0a, 0x0d09, 0xffff, 0xffff, 0xffff,
	0xffff, 0xffff, 0xb5b6, 0x10c3, 0x10c3, 0xffff, 0xffff, 0xffff, 0xffff, 0xffff, 0xffff, 0x10c3, 0x10a2, 0x10c3, 0x10c3, 0x10c3,
	0xffff, 0xffff, 0x10c3, 0x10c3, 0x10c3, 0xffff, 0xffff, 0xffff, 0xffff, 0xffff, 0xffff, 0xffff, 0xffff, 0xffff, 0x0d0a, 0x0d0a,
	0x0d2a, 0xffff, 0xffff, 0xffff, 0x10c3, 0x10c3, 0x10c3, 0xffff, 0xffff, 0xffff, 0xffff, 0xffff, 0xffff, 0xffff, 0xffff, 0xffff,
	0xffff, 0xffff, 0xffff, 0xffff, 0xffff, 0xffff, 0xffff, 0xffff, 0xffff, 0xffff, 0x10c3, 0x10c3, 0x10a3, 0xffff, 0xffff, 0xffff,
	0x0d0a, 0x0d0a, 0x0d0a, 0xffff, 0xffff, 0xffff, 0xffff, 0xffff, 0xffff, 0xffff, 0xffff, 0xffff, 0xffff, 0xffff, 0xffff, 0xffff,
	0xffff, 0xffff, 0xffff, 0xffff, 0x10a3, 0x10c3, 0x10c3, 0x10c3, 0x3a08, 0xffff, 0xffff, 0x10c3, 0x10c3, 0x10c3, 0x10a3, 0xffff,
	0xffff, 0xffff, 0xffff, 0xffff, 0xffff, 0x0d0a, 0x0d0a, 0x0d0a, 0x0d0a, 0x0d0a, 0x0d0a, 0x0d0a, 0x0d0a, 0x0d0a, 0x0d0a, 0x0d0a,
	0x0d0a, 0x0d0a, 0x0d0a, 0x0d0a, 0x0d0a, 0x0d0a, 0x0d0a, 0x0d0a, 0x0d0a, 0x0d0a, 0x0d0a, 0x0d0a, 0x0d0a, 0x0d0a, 0x0d0a, 0x0d0a,
	0x0d0a, 0x0d0a, 0x0d0a, 0x0d0a, 0x0d0a, 0x0d0a, 0x0d0a, 0x0d0a, 0x0d0a, 0x0d0a, 0x0d0a, 0x0d0a, 0x0d0a, 0x0d0a, 0x0d0a, 0x0d0a,
	0x0d0a, 0x0d0a, 0x0d0a, 0x0d0a, 0x0d0a, 0x0d0a, 0x0d0a, 0x0d0a, 0x0d0a, 0x0d0a, 0x0d0a, 0xd77b, 0xffff, 0xffff, 0xffff, 0xffff,
	0xffff, 0x10c3, 0x10a3, 0x10c3, 0x10c3, 0xffff, 0xffff, 0xffff, 0xffff, 0xffff, 0xffff, 0xffff, 0xffff, 0x10c3, 0x10c3, 0x10c3,
	0x10a2, 0x10c3, 0x10c3, 0x10c3, 0xffff, 0xffff, 0xffff, 0xffff, 0xffff, 0xffff, 0xffff, 0xffff, 0xffff, 0x0d0a, 0x0d0a, 0x0d0a,
	0xffff, 0xffff, 0xffff, 0x10a3, 0x10c3, 0x10c3, 0xffff, 0xffff, 0xffff, 0xffff, 0xffff, 0xffff, 0xffff, 0xffff, 0xffff, 0xffff,
	0xffff, 0xffff, 0xffff, 0xffff, 0xffff, 0xffff, 0xffff, 0xffff, 0xffff, 0xffff, 0x10a3, 0x10c3, 0x10c3, 0x10a3, 0xffff, 0xffff,
	0xffff, 0x0d0a, 0x0d0a, 0x050a, 0xffff, 0xffff, 0xffff, 0xffff, 0xffff, 0xffff, 0xffff, 0xffff, 0xffff, 0xffff, 0xffff, 0xffff,
	0xffff, 0xffff, 0xffff, 0x10a2, 0x10c3, 0x10c3, 0x10c3, 0xffff, 0xffff, 0xffff, 0xffff, 0xffff, 0x10a3, 0x10c3, 0xffff, 0xffff,
	0xffff, 0xffff, 0xffff, 0xffff, 0xffff, 0xffff, 0x1d2b, 0x0d0a, 0x0d0a, 0x0d0a, 0x0d0a, 0x0d0a, 0x0d0a, 0x0d0a, 0x0d0a, 0x0d0a,
	0x0d0a, 0x0d0a, 0x0d0a, 0x0d0a, 0x0d0a, 0x0d0a, 0x0d0a, 0x0d0a, 0x0d0a, 0x0d0a, 0x0d0a, 0x0d0a, 0x0d0a, 0x0d0a, 0x0d0a, 0x0d0a,
	0x0d0a, 0x0d0a, 0x0d0a, 0x0d0a, 0x0d0a, 0x0d0a, 0x0d0a, 0x0d0a, 0x0d0a, 0x0d0a, 0x0d0a, 0x0d0a, 0x0d0a, 0x0d0a, 0x0d0a, 0x0d0a,
	0x0d0a, 0x0d0a, 0x0d0a, 0x0d0a, 0x0d0a, 0x0d0a, 0x0d0a, 0x0d0a, 0x0d09, 0x0d2a, 0xffff, 0xffff, 0xffff, 0xffff, 0xffff, 0xef9e,
	0x10c3, 0x10c3, 0x10c3, 0x4a6a, 0xffff, 0xffff, 0xffff, 0xffff, 0xffff, 0xffff, 0xffff, 0xffff, 0xffff, 0xffff, 0xffff, 0x10c3,
	0x10c3, 0x10c3, 0x10a2, 0xffff, 0xffff, 0xffff, 0xffff, 0xffff, 0xffff, 0xffff, 0xffff, 0xffff, 0x0d0a, 0x0d0a, 0x052a, 0xffff,
	0xffff, 0xffff, 0x8c51, 0x10c3, 0x10c3, 0x10a2, 0xffff, 0xffff, 0xffff, 0xffff, 0xffff, 0xffff, 0xffff, 0xffff, 0xffff, 0xffff,
	0xffff, 0xffff, 0xffff, 0xffff, 0xffff, 0xffff, 0xffff, 0xffff, 0xffff, 0xffff, 0xffff, 0x10a2, 0x10c3, 0x10c3, 0xffff, 0xffff,
	0xffff, 0xffff, 0x0d0a, 0x0d0a, 0x0509, 0xffff, 0xffff, 0xffff, 0xffff, 0xffff, 0xffff, 0xffff, 0xffff, 0xffff, 0xffff, 0xffff,
	0xffff, 0xffff, 0x10c3, 0x10c3, 0x10c3, 0x10a2, 0xffff, 0xffff, 0xffff, 0xffff, 0xffff, 0xffff, 0xffff, 0xffff, 0xffff, 0xffff,
	0xffff, 0x10c3, 0xffff, 0xffff, 0xffff, 0xffff, 0xffff, 0xffff, 0x0d09, 0x0d0a, 0x0d0a, 0x0d0a, 0x0d0a, 0x0d0a, 0x0d0a, 0x0d0a,
	0x0d0a, 0x0d0a, 0x0d0a, 0x0d0a, 0x0d0a, 0x0d0a, 0x0d0a, 0x0d0a, 0x0d0a, 0x0d0a, 0x0d0a, 0x0d0a, 0x0d0a, 0x0d0a, 0x0d0a, 0x0d0a,
	0x0d0a, 0x0d0a, 0x0d0a, 0x0d0a, 0x0d0a, 0x0d0a, 0x0d0a, 0x0d0a, 0x0d0a, 0x0d0a, 0x0d0a, 0x0d0a, 0x0d0a, 0x0d0a, 0x0d0a, 0x0d0a,
	0x0d0a, 0x0d0a, 0x0d0a, 0x0d0a, 0x0d0a, 0x0d0a, 0x0d0a, 0x052a, 0xffff, 0xffff, 0xffff, 0xffff, 0xffff, 0xffff, 0x10c3, 0x10c3,
	0x10c3, 0x10a2, 0xffff, 0xffff, 0xffff, 0xffff, 0xffff, 0x10a3, 0xffff, 0xffff, 0xffff, 0xffff, 0xffff, 0xffff, 0xffff, 0xffff,
	0x10a3, 0x10a2, 0xffff, 0xffff, 0xffff, 0xffff, 0xffff, 0xffff, 0xffff, 0xffff, 0xffff, 0x0d09, 0x0d0a, 0x0d0a, 0xb719, 0xffff,
	0xffff, 0xffff, 0x10c3, 0x10c3, 0x10c3, 0xffff, 0xffff, 0xffff, 0xffff, 0xffff, 0xffff, 0xffff, 0xffff, 0xffff, 0xffff, 0xffff,
	0xffff, 0xffff, 0xffff, 0xffff, 0xffff, 0xffff, 0xffff, 0xffff, 0xffff, 0xffff, 0xffff, 0xffff, 0x10c3, 0x10c3, 0x10c3, 0xffff,
	0xffff, 0xffff, 0x0d09, 0x0d0a, 0x0d0a, 0xb719, 0xffff, 0xffff, 0xffff, 0xffff, 0xffff, 0xffff, 0xffff, 0xffff, 0xffff, 0xffff,
	0x8c51, 0x10c3, 0x10c3, 0x10c3, 0x10c3, 0xffff, 0xffff, 0xffff, 0xffff, 0xffff, 0xffff, 0xffff, 0xffff, 0xffff, 0xffff, 0xffff,
	0x10a2, 0x10c3, 0x10c3, 0xffff, 0xffff, 0xffff, 0xffff, 0xffff, 0xffff, 0xffff, 0xffff, 0x0d0a, 0x0d0a, 0x0d0a, 0x0d0a, 0x0d0a,
	0x0d0a, 0x0d0a, 0x0d0a, 0x0d0a, 0x0d0a, 0x0d0a, 0x0d0a, 0x0d0a, 0x0d0a, 0x0d0a, 0x0d0a, 0x0d0a, 0x0d0a, 0x0d0a, 0x0d0a, 0x0d0a,
	0x0d0a, 0x0d0a, 0x0d0a, 0x0d0a, 0x0d0a, 0x0d0a, 0x0d0a, 0x0d0a, 0x0d0a, 0x0d0a, 0x0d0a, 0x0d0a, 0x0d0a, 0x0d0a, 0x0d0a, 0x0d0a,
	0x0d0a, 0x0d0a, 0x0d0a, 0x0d0a, 0x0d0a, 0xc75a, 0xffff, 0xffff, 0xffff, 0xffff, 0xffff, 0xffff, 0xffff, 0xffff, 0xa555, 0x10c3,
	0x10c3, 0x10c3, 0xa535, 0xffff, 0xffff, 0xffff, 0x10a2, 0x10c3, 0x10c3, 0xffff, 0xffff, 0xffff, 0xffff, 0xffff, 0xffff, 0xffff,
	0xffff, 0xffff, 0xffff, 0xffff, 0xffff, 0xffff, 0xffff, 0xffff, 0xffff, 0xffff, 0xffff, 0x0d0a, 0x0d0a, 0x0d29, 0xffff, 0xffff,
	0xffff, 0x10c3, 0x10c3, 0x10c3, 0xffff, 0xffff, 0xffff, 0xffff, 0xffff, 0xffff, 0xffff, 0xffff, 0xffff, 0xffff, 0xffff, 0xffff,
	0xffff, 0xffff, 0xffff, 0xffff, 0xffff, 0xffff, 0xffff, 0xffff, 0xffff, 0xffff, 0xffff, 0xffff, 0xffff, 0x10c3, 0x10c3, 0x10c3,
	0xffff, 0xffff, 0xffff, 0x0d09, 0x0d0a, 0x0d0a, 0xf7de, 0xffff, 0xffff, 0xffff, 0xffff, 0xffff, 0xffff, 0xffff, 0xffff, 0xffff,
	0x10a2, 0x10c3, 0x10c3, 0x6b6d, 0xffff, 0xffff, 0xffff, 0xffff, 0xffff, 0xffff, 0xffff, 0xffff, 0xffff, 0xffff, 0xffff, 0x10c3,
	0x10c3, 0x10c3, 0xffff, 0xffff, 0xffff, 0xffff, 0xffff, 0xffff, 0xffff, 0xffff, 0xffff, 0xffff, 0xffff, 0x0509, 0x0d0a, 0x0d0a,
	0x0d0a, 0x0d0a, 0x0d0a, 0x0d0a, 0x0d0a, 0x0d0a, 0x0d0a, 0x0d0a, 0x0d0a, 0x0d0a, 0x0d0a, 0x0d0a, 0x0d0a, 0x0d0a, 0x0d0a, 0x0d0a,
	0x0d0a, 0x0d0a, 0x0d0a, 0x0d0a, 0x0d0a, 0x0d0a, 0x0d0a, 0x0d0a, 0x0d0a, 0x0d0a, 0x0d0a, 0x0d0a, 0x0d0a, 0x0d0a, 0x0d0a, 0x0d0a,
	0x0d0a, 0x0d0a, 0x0d2a, 0xffff, 0xffff, 0xffff, 0xffff, 0xffff, 0xffff, 0xffff, 0xffff, 0xffff, 0xffff, 0xffff, 0xffff, 0xffff,
	0x10c3, 0x10c3, 0x10c3, 0x10a2, 0x3a08, 0x10c3, 0x10c3, 0x10a2, 0xffff, 0xffff, 0xffff, 0xffff, 0xffff, 0xffff, 0xffff, 0xffff,
	0xffff, 0xffff, 0xffff, 0xffff, 0xffff, 0xffff, 0xffff, 0xffff, 0xffff, 0xffff, 0x0d0a, 0x0d0a, 0x0d0a, 0xffff, 0xffff, 0xffff,
	0x10c3, 0x10c3, 0x10c3, 0x9cd3, 0xffff, 0xffff, 0xffff, 0xffff, 0xffff, 0xffff, 0xffff, 0xffff, 0xffff, 0xffff, 0xffff, 0xffff,
	0xffff, 0xffff, 0xffff, 0xffff, 0xffff, 0xffff, 0xffff, 0xffff, 0xffff, 0xffff, 0xffff, 0xffff, 0xffff, 0x2124, 0x10c3, 0x10c3,
	0x10a2, 0xffff, 0xffff, 0xffff, 0x0509, 0x0d0a, 0x0d09, 0xffff, 0xffff, 0xffff, 0xffff, 0xffff, 0xffff, 0xffff, 0xffff, 0xffff,
	0xffff, 0x2124, 0xffff, 0xffff, 0xffff, 0xffff, 0xffff, 0xffff, 0xffff, 0xffff, 0xffff, 0xffff, 0xffff, 0xffff, 0x10c3, 0x10c3,
	0x10c3, 0x1924, 0xffff, 0xffff, 0xffff, 0xffff, 0xffff, 0xffff, 0xffff, 0xffff, 0xffff, 0xffff, 0xffff, 0xffff, 0xffff, 0xffff,
	0x7653, 0x0d0a, 0x0d0a, 0x0d0a, 0x0d0a, 0x0d0a, 0x0d0a, 0x0d0a, 0x0d0a, 0x0d0a, 0x0d0a, 0x0d0a, 0x0d0a, 0x0d0a, 0x0d0a, 0x0d0a,
	0x0d0a, 0x0d0a, 0x0d0a, 0x0d0a, 0x0d0a, 0x0d0a, 0x0d0a, 0x0d0a, 0x0d0a, 0x0d0a, 0x0d0a, 0x0d0a, 0x0d0a, 0x0d0a, 0x0d0a, 0x2d6c,
	0xffff, 0xffff, 0xffff, 0xffff, 0xffff, 0xffff, 0xffff, 0xffff, 0xffff, 0xffff, 0xffff, 0xffff, 0xffff, 0xffff, 0xffff, 0xffff,
	0xffff, 0x10c3, 0x10c3, 0x10c3, 0x10c3, 0x10c3, 0x10a2, 0xffff, 0xffff, 0xffff, 0xffff, 0xd69a, 0xffff, 0xffff, 0xffff, 0xffff,
	0xffff, 0xffff, 0xffff, 0xffff, 0xffff, 0xffff, 0xffff, 0xffff, 0xffff, 0x0d09, 0x0d0a, 0x0d09, 0xffff, 0xffff, 0xffff, 0x10a2,
	0x10c3, 0x10c3, 0x10a2, 0xffff, 0xffff, 0xffff, 0xffff, 0xffff, 0xffff, 0xffff, 0xffff, 0xffff, 0xffff, 0xffff, 0xffff, 0xffff,
	0xffff, 0xffff, 0xffff, 0xffff, 0xffff, 0xffff, 0xffff, 0xffff, 0xffff, 0xffff, 0xffff, 0xffff, 0xffff, 0xffff, 0x10a2, 0x10c3,
	0x10c3, 0x10a2, 0xffff, 0xffff, 0xffff, 0x0d0a, 0x0d0a, 0x0d0a, 0xffff, 0xffff, 0xffff, 0xffff, 0xffff, 0xffff, 0xffff, 0xffff,
	0xffff, 0xffff, 0xffff, 0xffff, 0xffff, 0xffff, 0xffff, 0xffff, 0xffff, 0xffff, 0xffff, 0xffff, 0xffff, 0x10c3, 0x10c3, 0x10c3,
	0x10a3, 0xffff, 0xffff, 0xffff, 0xffff, 0xffff, 0xffff, 0xffff, 0xffff, 0xffff, 0xffff, 0xffff, 0xffff, 0xffff, 0xffff, 0xffff,
	0xffff, 0xffff, 0xffff, 0xffff, 0xd77b, 0x0d0a, 0x0d0a, 0x0d0a, 0x0d0a, 0x0d0a, 0x0d0a, 0x0d0a, 0x0d0a, 0x0d0a, 0x0d0a, 0x0d0a,
	0x0d0a, 0x0d0a, 0x0d0a, 0x0d0a, 0x0d0a, 0x0d0a, 0x0d0a, 0x0d0a, 0x0d0a, 0x0d0a, 0x0d0a, 0xa6d7, 0xffff, 0xffff, 0xffff, 0xffff,
	0xffff, 0xffff, 0xffff, 0xffff, 0xffff, 0xe71c, 0x10c3, 0x10c3, 0x10a2, 0xffff, 0xffff, 0xffff, 0xffff, 0xffff, 0xffff, 0xffff,
	0xffff, 0xffff, 0x10a2, 0x10c3, 0x10c3, 0x10a2, 0xffff, 0xffff, 0xffff, 0xffff, 0x10c3, 0x10c3, 0xd69a, 0xffff, 0xffff, 0xffff,
	0xffff, 0xffff, 0xffff, 0xffff, 0xffff, 0xffff, 0xffff, 0xffff, 0x0d0a, 0x0d0a, 0x0d0a, 0xffff, 0xffff, 0xffff, 0x10a2, 0x10c3,
	0x10c3, 0x10a3, 0xffff, 0xffff, 0xffff, 0xffff, 0xffff, 0xffff, 0xffff, 0xffff, 0xffff, 0xffff, 0xffff, 0xffff, 0xffff, 0xffff,
	0xffff, 0xffff, 0xffff, 0xffff, 0xffff, 0xffff, 0xffff, 0xffff, 0xffff, 0xffff, 0xffff, 0xffff, 0xffff, 0xffff, 0xffff, 0x10a3,
	0x10c3, 0x10c3, 0x10c3, 0xffff, 0xffff, 0xffff, 0x0509, 0x0d0a, 0x0d0a, 0xd77b, 0xffff, 0xffff, 0xffff, 0xffff, 0xffff, 0xffff,
	0xffff, 0xffff, 0xffff, 0xffff, 0xffff, 0xffff, 0xffff, 0xffff, 0xffff, 0xffff, 0xffff, 0xffff, 0x10c3, 0x10c3, 0x10c3, 0x10c3,
	0xffff, 0xffff, 0xffff, 0xffff, 0xffff, 0xffff, 0xffff, 0xffff, 0xffff, 0xffff, 0xffff, 0xffff, 0xffff, 0xffff, 0xffff, 0xffff,
	0xffff, 0xffff, 0xffff, 0xffff, 0xffff, 0xffff, 0xffff, 0xffff, 0xffff, 0xffff, 0xffff, 0xffff, 0x8695, 0x0d0a, 0x0d0a, 0x0d09,
	0x0d09, 0x0d0a, 0x0509, 0x8694, 0xffff, 0xffff, 0xffff, 0xffff, 0xffff, 0xffff, 0xffff, 0xffff, 0xffff, 0xffff, 0xffff, 0xffff,
	0xffff, 0xffff, 0xffff, 0xffff, 0xffff, 0x10a2, 0x10c3, 0x10c3, 0x10c3, 0x10c3, 0xffff, 0xffff, 0xffff, 0xffff, 0xffff, 0xffff,
	0xffff, 0xffff, 0xffff, 0x10c3, 0x10c3, 0x10c3, 0x10a3, 0xffff, 0x10a3, 0x10c3, 0x10c3, 0x10c3, 0xffff, 0xffff, 0xffff, 0xffff,
	0xffff, 0xffff, 0xffff, 0xffff, 0xffff, 0xffff, 0xffff, 0x0d0a, 0x0d0a, 0x0d0a, 0xffff, 0xffff, 0xffff, 0x7bef, 0x10c3, 0x10c3,
	0x10c3, 0xffff, 0xffff, 0xffff, 0xffff, 0xffff, 0xffff, 0xffff, 0xffff, 0xffff, 0xffff, 0xffff, 0xffff, 0xffff, 0xffff, 0xffff,
	0xffff, 0xffff, 0xffff, 0xffff, 0xffff, 0xffff, 0xffff, 0xffff, 0xffff, 0xffff, 0xffff, 0xffff, 0xffff, 0xffff, 0xffff, 0xffff,
	0x10c3, 0x10c3, 0x10c3, 0x10a3, 0xffff, 0xffff, 0xffff, 0x0d0a, 0x0d0a, 0x0d0a, 0x0d09, 0xffff, 0xffff, 0xffff, 0xffff, 0xffff,
	0xffff, 0xffff, 0xffff, 0xffff, 0xffff, 0xffff, 0xffff, 0xffff, 0xffff, 0xffff, 0xffff, 0x10c3, 0x10c3, 0x10c3, 0x10a3, 0xffff,
	0xffff, 0xffff, 0xffff, 0xffff, 0xffff, 0xffff, 0xffff, 0xffff, 0xffff, 0xffff, 0xffff, 0xffff, 0xffff, 0xffff, 0x10a3, 0x10a2,
	0x10c3, 0x10c3, 0xffff, 0xffff, 0xffff, 0xffff, 0xffff, 0xffff, 0xffff, 0xffff, 0xffff, 0xffff, 0xffff, 0xffff, 0xffff, 0xffff,
	0xffff, 0xffff, 0xffff, 0xffff, 0xffff, 0xffff, 0xffff, 0xffff, 0xffff, 0xffff, 0xffff, 0xffff, 0xffff, 0xffff, 0xffff, 0xffff,
	0xffff, 0xffff, 0xffff, 0xffff, 0xffff, 0x10a3, 0x10c3, 0x10c3, 0x10c3, 0x10c3, 0x10c3, 0x3a08, 0xffff, 0xffff, 0xffff, 0xffff,
	0xffff, 0xffff, 0xffff, 0xffff, 0x10c3, 0x10c3, 0x10c3, 0x10c3, 0x10c3, 0x10c3, 0x10a2, 0xffff, 0xffff, 0xffff, 0xffff, 0xffff,
	0xffff, 0xffff, 0xffff, 0xffff, 0xffff, 0x5610, 0x0d2a, 0x0d0a, 0x0d2a, 0xffff, 0xffff, 0xffff, 0x6b6d, 0x10c3, 0x10c3, 0x10c3,
	0xffff, 0xffff, 0xffff, 0xffff, 0xffff, 0xffff, 0xffff, 0xffff, 0xffff, 0xffff, 0xffff, 0xffff, 0xffff, 0xffff, 0xffff, 0xffff,
	0xffff, 0xffff, 0xffff, 0xffff, 0xffff, 0xffff, 0xffff, 0xffff, 0xffff, 0xffff, 0xffff, 0xffff, 0xffff, 0xffff, 0xffff, 0xffff,
	0xffff, 0x10a3, 0x10c3, 0x10c3, 0x10a2, 0xffff, 0xffff, 0xffff, 0x0529, 0x0d0a, 0x0d0a, 0x0d2a, 0xffff, 0xffff, 0xffff, 0xffff,
	0xffff, 0xffff, 0xffff, 0xffff, 0xffff, 0xffff, 0xffff, 0xffff, 0xffff, 0xffff, 0x10a3, 0x10c3, 0x10c3, 0x10a3, 0xffff, 0xffff,
	0xffff, 0xffff, 0xffff, 0xffff, 0xffff, 0xffff, 0xffff, 0xffff, 0xffff, 0xffff, 0xffff, 0xffff, 0x10a2, 0x10c3, 0x10c3, 0x10c3,
	0x10c3, 0x10c3, 0x10c3, 0x10c3, 0x10c3, 0xffff, 0xffff, 0xffff, 0xffff, 0xffff, 0xffff, 0xffff, 0xffff, 0xffff, 0xffff, 0xffff,
	0xffff, 0xffff, 0xffff, 0xffff, 0xffff, 0xffff, 0xffff, 0xffff, 0xffff, 0xffff, 0xffff, 0xffff, 0x10c3, 0x10c3, 0x10a2, 0xffff,
	0xffff, 0xffff, 0xffff, 0xffff, 0xffff, 0xffff, 0x10c3, 0x10c3, 0xffff, 0x10a2, 0x10c3, 0x10c3, 0x10c3, 0xffff, 0xffff, 0xffff,
	0xffff, 0xffff, 0xffff, 0xffff, 0xffff, 0x10a2, 0x10c3, 0x10c3, 0x10c3, 0xffff, 0xffff, 0xffff, 0xffff, 0xffff, 0xffff, 0xffff,
	0xffff, 0xffff, 0xffff, 0xffff, 0x0d0a, 0x0d0a, 0x0d0a, 0x0d09, 0xffff, 0xffff, 0xffff, 0x10a3, 0x10c3, 0x10c3, 0x10a2, 0xffff,
	0xffff, 0xffff, 0xffff, 0xffff, 0xffff, 0xffff, 0xffff, 0xffff, 0xffff, 0xffff, 0xffff, 0xffff, 0xffff, 0xffff, 0xffff, 0xffff,
	0xffff, 0xffff, 0xffff, 0xffff, 0xffff, 0xffff, 0xffff, 0xffff, 0xffff, 0xffff, 0xffff, 0xffff, 0xffff, 0xffff, 0xffff, 0xffff,
	0xffff, 0xffff, 0x10a3, 0x10c3, 0x10c3, 0x10c3, 0xffff, 0xffff, 0xffff, 0x0d09, 0x0d0a, 0x0d0a, 0x0d0a, 0xffff, 0xffff, 0xffff,
	0xffff, 0xffff, 0xffff, 0xffff, 0xffff, 0xffff, 0xffff, 0xffff, 0xffff, 0x10c3, 0x10c3, 0x10c3, 0x10c3, 0xffff, 0xffff, 0xffff,
	0xffff, 0xffff, 0xffff, 0xffff, 0xffff, 0xffff, 0xffff, 0xffff, 0xffff, 0xffff, 0xffff, 0x10a3, 0x10c3, 0x10c3, 0x10a3, 0x5aeb,
	0xffff, 0x2124, 0x10a2, 0x10c3, 0x10c3, 0x10c3, 0xffff, 0xffff, 0xffff, 0xffff, 0xffff, 0x4a8a, 0x10c3, 0x10a2, 0xffff, 0xffff,
	0xffff, 0xffff, 0xffff, 0xffff, 0xffff, 0x10c3, 0x10c3, 0x10c3, 0xffff, 0xffff, 0xffff, 0xffff, 0x10a3, 0x10c3, 0x10a3, 0xffff,
	0xffff, 0xffff, 0xffff, 0xffff, 0xffff, 0xffff, 0x10c3, 0x10c3, 0xffff, 0xffff, 0x10a2, 0x10a3, 0x10c3, 0x10c3, 0xffff, 0xffff,
	0xffff, 0xffff, 0xffff, 0xffff, 0xffff, 0xffff, 0x10a2, 0x10a3, 0xffff, 0xffff, 0xffff, 0xffff, 0xffff, 0xffff, 0xffff, 0xffff,
	0xffff, 0xffff, 0xffff, 0x0d09, 0x0d0a, 0x0d0a, 0x0d0a, 0xffff, 0xffff, 0xffff, 0x10c3, 0x10c3, 0x10c3, 0x10a2, 0xffff, 0xffff,
	0xffff, 0xffff, 0xffff, 0xffff, 0xffff, 0xffff, 0xffff, 0xffff, 0xffff, 0xffff, 0xffff, 0xffff, 0xffff, 0xffff, 0xffff, 0xffff,
	0xffff, 0xffff, 0xffff, 0xffff, 0xffff, 0xffff, 0xffff, 0xffff, 0xffff, 0xffff, 0xffff, 0xffff, 0xffff, 0xffff, 0xffff, 0xffff,
	0xffff, 0xffff, 0xffff, 0x10c3, 0x10c3, 0x10c3, 0x10c3, 0xffff, 0xffff, 0xffff, 0xffff, 0x0d0a, 0x0d0a, 0x052a, 0xffff, 0xffff,
	0xffff, 0xffff, 0xffff, 0xffff, 0xffff, 0xffff, 0xffff, 0xffff, 0xffff, 0xffff, 0x10a3, 0x10a2, 0xffff, 0xffff, 0xffff, 0xffff,
	0xffff, 0xffff, 0xffff, 0xffff, 0xffff, 0xffff, 0xffff, 0xffff, 0xffff, 0xffff, 0xffff, 0x10a3, 0x10c3, 0x10c3, 0xffff, 0xffff,
	0xffff, 0xffff, 0xffff, 0x10a3, 0x10c3, 0x10c3, 0x10c3, 0xffff, 0xffff, 0xffff, 0xffff, 0x10a2, 0x10c3, 0x10a2, 0xffff, 0xffff,
	0xffff, 0xffff, 0xffff, 0xffff, 0x10a2, 0x10c3, 0x10c3, 0x10c3, 0xffff, 0xffff, 0xffff, 0xffff, 0x10c3, 0x10c3, 0x10c3, 0xef9e,
	0xffff, 0xffff, 0xffff, 0xffff, 0xffff, 0xffff, 0x10c3, 0x10c3, 0x10a2, 0xffff, 0xffff, 0x6b6d, 0x10c3, 0x10c3, 0x10c3, 0x10a3,
	0xffff, 0xffff, 0xffff, 0xffff, 0xffff, 0xffff, 0xffff, 0xffff, 0xffff, 0xffff, 0xffff, 0xffff, 0xffff, 0xffff, 0xffff, 0xffff,
	0xffff, 0xffff, 0x0d2a, 0x0d0a, 0x0d0a, 0xf7de, 0xffff, 0xffff, 0xffff, 0x10a2, 0x10c3, 0x10c3, 0x10a3, 0xffff, 0xffff, 0xffff,
	0xffff, 0xffff, 0xffff, 0xffff, 0xffff, 0xffff, 0xffff, 0xffff, 0xffff, 0xffff, 0xffff, 0xffff, 0xffff, 0xffff, 0xffff, 0xffff,
	0xffff, 0xffff, 0xffff, 0xffff, 0xffff, 0xffff, 0xffff, 0xffff, 0xffff, 0xffff, 0xffff, 0xffff, 0xffff, 0xffff, 0xffff, 0xffff,
	0xffff, 0xffff, 0xffff, 0xffff, 0x10a2, 0x10c3, 0x10c3, 0x10c3, 0xffff, 0xffff, 0xffff, 0xffff, 0x0d0a, 0x0d0a, 0x0d0a, 0x152b,
	0xffff, 0xffff, 0xffff, 0xffff, 0xffff, 0xffff, 0xffff, 0xffff, 0x10a3, 0xffff, 0xffff, 0xffff, 0xffff, 0xffff, 0xffff, 0xffff,
	0xffff, 0xffff, 0xffff, 0xffff, 0xffff, 0xffff, 0xffff, 0xffff, 0xffff, 0xffff, 0xffff, 0x10c3, 0x10c3, 0x10a2, 0xffff, 0xffff,
	0xffff, 0xffff, 0xffff, 0xffff, 0x10c3, 0x10c3, 0x10a2, 0xffff, 0xffff, 0xffff, 0xffff, 0x10a2, 0x10c3, 0x10a2, 0xffff, 0xffff,
	0xffff, 0xffff, 0xffff, 0x10a3, 0x10c3, 0x10c3, 0x10c3, 0x10c3, 0xffff, 0xffff, 0xffff, 0xffff, 0xffff, 0x10c3, 0x10c3, 0x10a3,
	0xffff, 0xffff, 0xffff, 0xffff, 0xffff, 0xffff, 0x10c3, 0x10c3, 0x10c3, 0xffff, 0xffff, 0xffff, 0xffff, 0x10a2, 0x10c3, 0x10c3,
	0x10a2, 0xffff, 0xffff, 0xffff, 0xffff, 0xffff, 0xffff, 0xffff, 0xffff, 0xffff, 0xffff, 0xffff, 0xffff, 0xffff, 0xffff, 0xffff,
	0xa6f7, 0x0d0a, 0x0d0a, 0x0d0a, 0xffff, 0xffff, 0xffff, 0xffff, 0x10c3, 0x10c3, 0x10c3, 0x10a3, 0xffff, 0xffff, 0xffff, 0xffff,
	0xffff, 0xffff, 0xffff, 0xffff, 0xffff, 0xffff, 0xffff, 0xffff, 0xffff, 0xffff, 0xffff, 0xffff, 0xffff, 0xffff, 0xffff, 0xffff,
	0xffff, 0xffff, 0xffff, 0xffff, 0xffff, 0xffff, 0xffff, 0xffff, 0xffff, 0xffff, 0xffff, 0xffff, 0xffff, 0xffff, 0xffff, 0xffff,
	0xffff, 0xffff, 0xffff, 0xffff, 0xffff, 0x10a3, 0x10c3, 0x10c3, 0x10a3, 0xffff, 0xffff, 0xffff, 0xffff, 0x0d0a, 0x0d0a, 0x0d0a,
	0x050a, 0xffff, 0xffff, 0xffff, 0xffff, 0xffff, 0xffff, 0x10c3, 0x10c3, 0x10a3, 0xffff, 0xffff, 0xffff, 0xffff, 0xffff, 0xffff,
	0xffff, 0xffff, 0xffff, 0xffff, 0xffff, 0xffff, 0xffff, 0xffff, 0xffff, 0xffff, 0x10a3, 0x10c3, 0x10c3, 0xffff, 0xffff, 0xffff,
	0xffff, 0xffff, 0xffff, 0xffff, 0x10c3, 0x10c3, 0x10a3, 0xffff, 0xffff, 0xffff, 0xffff, 0x10c3, 0x10c3, 0x10a3, 0xffff, 0xffff,
	0xffff, 0xffff, 0x10a3, 0x10a2, 0x10c3, 0xffff, 0x10c3, 0x10c3, 0xffff, 0xffff, 0xffff, 0xffff, 0xffff, 0x10c3, 0x10c3, 0x10c3,
	0xffff, 0xffff, 0xffff, 0xffff, 0xffff, 0xffff, 0x10c3, 0x10c3, 0x10a2, 0xffff, 0xffff, 0xffff, 0xffff, 0xffff, 0x10a2, 0x10c3,
	0x10c3, 0x10c3, 0xffff, 0xffff, 0xffff, 0xffff, 0xffff, 0xffff, 0xffff, 0xffff, 0xffff, 0xffff, 0xffff, 0xffff, 0xffff, 0x0d09,
	0x0d0a, 0x0d0a, 0x0d0a, 0xffff, 0xffff, 0xffff, 0xffff, 0x10a3, 0x10c3, 0x10c3, 0x10c3, 0xffff, 0xffff, 0xffff, 0xffff, 0xffff,
	0xffff, 0xffff, 0xffff, 0xffff, 0xffff, 0xffff, 0xffff, 0xffff, 0xffff, 0xffff, 0xffff, 0xffff, 0xffff, 0xffff, 0xffff, 0xffff,
	0xffff, 0xffff, 0xffff, 0xffff, 0xffff, 0xffff, 0xffff, 0xffff, 0xffff, 0xffff, 0xffff, 0xffff, 0xffff, 0xffff, 0xffff, 0xffff,
	0xffff, 0xffff, 0xffff, 0xffff, 0xffff, 0xffff, 0xffff, 0x10c3, 0x10c3, 0x10c3, 0xa535, 0xffff, 0xffff, 0xffff, 0xa6f7, 0x0d0a,
	0x0d0a, 0x0d0a, 0xb719, 0xffff, 0xffff, 0xffff, 0xffff, 0xffff, 0x4a6a, 0xffff, 0xffff, 0xffff, 0xffff, 0xffff, 0xffff, 0xffff,
	0xffff, 0xffff, 0xffff, 0xffff, 0xffff, 0xffff, 0xffff, 0xffff, 0xffff, 0xffff, 0x10c3, 0x10c3, 0x10c3, 0xffff, 0xffff, 0xffff,
	0xffff, 0xffff, 0xffff, 0x10c3, 0x10c3, 0x10c3, 0xffff, 0xffff, 0xffff, 0xffff, 0xffff, 0x10a2, 0x10c3, 0x10c3, 0xffff, 0xffff,
	0xffff, 0x10a2, 0x10c3, 0x10c3, 0x10a2, 0xffff, 0x10c3, 0x10c3, 0xffff, 0xffff, 0xffff, 0xffff, 0xffff, 0x10a3, 0x10c3, 0x10c3,
	0x7bef, 0xffff, 0xffff, 0xffff, 0xffff, 0xffff, 0x10c3, 0x10c3, 0x10a3, 0xffff, 0xffff, 0xffff, 0xffff, 0xffff, 0xffff, 0x10a3,
	0x31a6, 0xffff, 0xffff, 0xffff, 0xffff, 0xffff, 0xffff, 0xffff, 0xffff, 0xffff, 0xffff, 0xffff, 0xffff, 0xffff, 0x0d0a, 0x0d0a,
	0x0d2a, 0x1d4b, 0xffff, 0xffff, 0xffff, 0xffff, 0x10a2, 0x10c3, 0x10c3, 0x6b6d, 0xffff, 0xffff, 0xffff, 0xffff, 0xffff, 0xffff,
	0xffff, 0xffff, 0xffff, 0xffff, 0xffff, 0xffff, 0xffff, 0xffff, 0xffff, 0xffff, 0xffff, 0xffff, 0xffff, 0xffff, 0xffff, 0xffff,
	0xffff, 0xffff, 0xffff, 0xffff, 0xffff, 0xffff, 0xffff, 0xffff, 0xffff, 0xffff, 0xffff, 0xffff, 0xffff, 0xffff, 0xffff, 0xffff,
	0xffff, 0xffff, 0xffff, 0xffff, 0xffff, 0xffff, 0xffff, 0xffff, 0x10a2, 0x10c3, 0x10c3, 0x10c3, 0xffff, 0xffff, 0xffff, 0xffff,
	0x0d0a, 0x0d0a, 0x0d0a, 0x0d0a, 0xffff, 0xffff, 0xffff, 0xffff, 0xffff, 0xffff, 0xffff, 0xffff, 0xffff, 0xffff, 0xffff, 0xffff,
	0xffff, 0xffff, 0xffff, 0xffff, 0xffff, 0xffff, 0xffff, 0xffff, 0xffff, 0x5aeb, 0x10c3, 0x10c3, 0x10a3, 0xffff, 0xffff, 0xffff,
	0xffff, 0xffff, 0xffff, 0x10c3, 0x10c3, 0x10c3, 0xffff, 0xffff, 0xffff, 0xffff, 0xffff, 0x10a3, 0x10c3, 0x10c3, 0xffff, 0xffff,
	0xffff, 0x10c3, 0x10c3, 0x10a2, 0xffff, 0xffff, 0x10c3, 0x10c3, 0xc638, 0xffff, 0xffff, 0xffff, 0xffff, 0xffff, 0x10c3, 0x10c3,
	0x10c3, 0xffff, 0xffff, 0xffff, 0xffff, 0xffff, 0x10c3, 0x10c3, 0x10c3, 0xffff, 0xffff, 0xffff, 0xffff, 0xffff, 0xffff, 0xffff,
	0xffff, 0xffff, 0xffff, 0xffff, 0xffff, 0xffff, 0xffff, 0xffff, 0xffff, 0xffff, 0xffff, 0xffff, 0x0d0a, 0x0d0a, 0x0d0a, 0x0d0a,
	0xffff, 0xffff, 0xffff, 0xffff, 0x10a2, 0x10c3, 0x10c3, 0x10c3, 0xffff, 0xffff, 0xffff, 0xffff, 0xffff, 0xffff, 0xffff, 0xffff,
	0xffff, 0xffff, 0xffff, 0xffff, 0xffff, 0xffff, 0xffff, 0xffff, 0xffff, 0xffff, 0xffff, 0xffff, 0xffff, 0xffff, 0xffff, 0xffff,
	0xffff, 0xffff, 0xffff, 0xffff, 0xffff, 0xffff, 0xffff, 0xffff, 0xffff, 0xffff, 0xffff, 0xffff, 0xffff, 0xffff, 0xffff, 0xffff,
	0xffff, 0xffff, 0xffff, 0xffff, 0xffff, 0xffff, 0xffff, 0xffff, 0xffff, 0x10c3, 0x10c3, 0x10c3, 0x10c3, 0xffff, 0xffff, 0xffff,
	0xffff, 0x0d2a, 0x0d0a, 0x0d0a, 0x052a, 0x0d09, 0xffff, 0xffff, 0xffff, 0xffff, 0xffff, 0xffff, 0xffff, 0xffff, 0xffff, 0xffff,
	0xffff, 0xffff, 0xffff, 0xffff, 0xffff, 0xffff, 0xffff, 0xffff, 0xffff, 0x10c3, 0x10c3, 0x10c3, 0xffff, 0xffff, 0xffff, 0xffff,
	0xffff, 0xffff, 0x9cd3, 0x10c3, 0x10c3, 0x10a3, 0xffff, 0xffff, 0xffff, 0xffff, 0xffff, 0x10a3, 0x10c3, 0x10c3, 0xffff, 0xffff,
	0x10c3, 0x10c3, 0x10c3, 0xffff, 0xffff, 0xffff, 0x10c3, 0x10c3, 0x8451, 0xffff, 0xffff, 0xffff, 0xffff, 0xffff, 0x10c3, 0x10c3,
	0x10c3, 0xffff, 0xffff, 0xffff, 0xffff, 0xffff, 0xef9e, 0x10c3, 0x10c3, 0x10a3, 0xffff, 0xffff, 0xffff, 0xffff, 0xffff, 0xffff,
	0xffff, 0xffff, 0xffff, 0xffff, 0xffff, 0xffff, 0xffff, 0xffff, 0xffff, 0xffff, 0x7673, 0x0d0a, 0x0d0a, 0x0d0a, 0x0d09, 0xffff,
	0xffff, 0xffff, 0xffff, 0x10a3, 0x10c3, 0x10c3, 0x10c3, 0xffff, 0xffff, 0xffff, 0xffff, 0xffff, 0xffff, 0xffff, 0xffff, 0xffff,
	0xffff, 0xffff, 0xffff, 0xffff, 0xffff, 0xffff, 0xffff, 0xffff, 0xffff, 0xffff, 0xffff, 0xffff, 0xffff, 0xffff, 0xffff, 0xffff,
	0xffff, 0xffff, 0xffff, 0xffff, 0xffff, 0xffff, 0xffff, 0xffff, 0xffff, 0xffff, 0xffff, 0xffff, 0xffff, 0xffff, 0xffff, 0xffff,
	0xffff, 0xffff, 0xffff, 0xffff, 0xffff, 0xffff, 0xffff, 0xffff, 0xffff, 0xffff, 0x10a3, 0x10c3, 0x10c3, 0x10c3, 0x3a08, 0xffff,
	0xffff, 0xffff, 0xffff, 0x0d0a, 0x0d0a, 0x0d0a, 0x0d0a, 0xffff, 0xffff, 0xffff, 0xffff, 0xffff, 0xffff, 0xffff, 0xffff, 0xffff,
	0xffff, 0xffff, 0xffff, 0xffff, 0xffff, 0xffff, 0xffff, 0xffff, 0xffff, 0x10c3, 0x10c3, 0x10c3, 0xffff, 0xffff, 0xffff, 0xffff,
	0xffff, 0xffff, 0x10a3, 0x10c3, 0x10c3, 0xffff, 0xffff, 0xffff, 0xffff, 0xffff, 0xffff, 0x10a2, 0x10c3, 0x10c3, 0xffff, 0x10a2,
	0x10c3, 0x10c3, 0xffff, 0xffff, 0xffff, 0xffff, 0x10c3, 0x10c3, 0x10a2, 0xffff, 0xffff, 0xffff, 0xffff, 0xffff, 0x10a3, 0x10c3,
	0x10c3, 0x3a08, 0xffff, 0xffff, 0xffff, 0xffff, 0xffff, 0x10c3, 0x10a3, 0xffff, 0xffff, 0xffff, 0xffff, 0xffff, 0xffff, 0xffff,
	0xffff, 0xffff, 0xffff, 0xffff, 0xffff, 0xffff, 0xffff, 0xffff, 0xffff, 0x0d0a, 0x0d0a, 0x0d0a, 0x0509, 0xffff, 0xffff, 0xffff,
	0xffff, 0xd69a, 0x10c3, 0x10c3, 0x10c3, 0x10c3, 0xffff, 0xffff, 0xffff, 0xffff, 0xffff, 0xffff, 0xffff, 0xffff, 0xffff, 0xffff,
	0xffff, 0xffff, 0xffff, 0xffff, 0xffff, 0xffff, 0xffff, 0xffff, 0xffff, 0xffff, 0xffff, 0xffff, 0xffff, 0xffff, 0xffff, 0xffff,
	0xffff, 0xffff, 0xffff, 0xffff, 0xffff, 0xffff, 0xffff, 0xffff, 0xffff, 0xffff, 0xffff, 0xffff, 0xffff, 0xffff, 0xffff, 0xffff,
	0xffff, 0xffff, 0xffff, 0xffff, 0xffff, 0xffff, 0xffff, 0xffff, 0xffff, 0xffff, 0xffff, 0xffff, 0x10c3, 0x10c3, 0x10c3, 0x10c3,
	0xffff, 0xffff, 0xffff, 0xffff, 0xffff, 0x0d0a, 0x0d0a, 0x0d0a, 0x050a, 0xffff, 0xffff, 0xffff, 0xffff, 0xffff, 0xffff, 0xffff,
	0xffff, 0xffff, 0xffff, 0xffff, 0xffff, 0xffff, 0xffff, 0xffff, 0xffff, 0xffff, 0x10c3, 0xef9e, 0xffff, 0xffff, 0xffff, 0xffff,
	0xffff, 0xffff, 0x10c3, 0x10c3, 0x10c3, 0xffff, 0xffff, 0xffff, 0xffff, 0xffff, 0xffff, 0x10a2, 0x10c3, 0x10c3, 0x10a3, 0x10c3,
	0x10c3, 0xffff, 0xffff, 0xffff, 0xffff, 0xffff, 0x10c3, 0x10c3, 0x10a3, 0xffff, 0xffff, 0xffff, 0xffff, 0xffff, 0xffff, 0x10c3,
	0x10c3, 0x10c3, 0xffff, 0xffff, 0xffff, 0xffff, 0xffff, 0xffff, 0xffff, 0xffff, 0xffff, 0xffff, 0xffff, 0xffff, 0xffff, 0xffff,
	0xffff, 0xffff, 0xffff, 0xffff, 0xffff, 0xffff, 0xffff, 0x0d09, 0x0d0a, 0x0d0a, 0x0d0a, 0xffff, 0xffff, 0xffff, 0xffff, 0xffff,
	0x10a2, 0x10c3, 0x10c3, 0x10c3, 0xffff, 0xffff, 0xffff, 0xffff, 0xffff, 0xffff, 0xffff, 0xffff, 0xffff, 0xffff, 0xffff, 0xffff,
	0xffff, 0xffff, 0xffff, 0xffff, 0xffff, 0xffff, 0xffff, 0xffff, 0xffff, 0xffff, 0xffff, 0xffff, 0xffff, 0xffff, 0xffff, 0xffff,
	0xffff, 0xffff, 0xffff, 0xffff, 0xffff, 0xffff, 0xffff, 0xffff, 0xffff, 0xffff, 0xffff, 0xffff, 0xffff, 0xffff, 0xffff, 0xffff,
	0xffff, 0xffff, 0xffff, 0xffff, 0xffff, 0xffff, 0xffff, 0xffff, 0xffff, 0xffff, 0xffff, 0xffff, 0xffff, 0x10a3, 0x10c3, 0x10c3,
	0x10c3, 0x10a2, 0xffff, 0xffff, 0xffff, 0xffff, 0xdfbd, 0x0d0a, 0x0d0a, 0x0d0a, 0x0d0a, 0xffff, 0xffff, 0xffff, 0xffff, 0xffff,
	0xffff, 0xffff, 0xffff, 0xffff, 0xffff, 0xffff, 0xffff, 0xffff, 0xffff, 0xffff, 0xffff, 0xffff, 0xffff, 0xffff, 0xffff, 0xffff,
	0xffff, 0x10a2, 0x10c3, 0x10c3, 0xa555, 0xffff, 0xffff, 0xffff, 0xffff, 0xffff, 0xffff, 0x4a6a, 0x10c3, 0x10c3, 0x10c3, 0x10c3,
	0xffff, 0xffff, 0xffff, 0xffff, 0xffff, 0xffff, 0x10c3, 0x10c3, 0x10a3, 0xffff, 0xffff, 0xffff, 0xffff, 0xffff, 0xffff, 0x10c3,
	0x10c3, 0x10a2, 0xffff, 0xffff, 0xffff, 0xffff, 0xffff, 0xffff, 0xffff, 0xffff, 0xffff, 0xffff, 0xffff, 0xffff, 0xffff, 0xffff,
	0xffff, 0xffff, 0xffff, 0xffff, 0xffff, 0x0d2a, 0x0d0a, 0x0d0a, 0x0d0a, 0x5611, 0xffff, 0xffff, 0xffff, 0xffff, 0x10a2, 0x10c3,
	0x10c3, 0x10c3, 0x10a2, 0xffff, 0xffff, 0xffff, 0xffff, 0xffff, 0xffff, 0xffff, 0xffff, 0xffff, 0xffff, 0xffff, 0xffff, 0xffff,
	0xffff, 0xffff, 0xffff, 0xffff, 0xffff, 0xffff, 0xffff, 0xffff, 0xffff, 0xffff, 0xffff, 0xffff, 0xffff, 0xffff, 0xffff, 0xffff,
	0xffff, 0xffff, 0xffff, 0xffff, 0xffff, 0xffff, 0xffff, 0xffff, 0xffff, 0xffff, 0xffff, 0xffff, 0xffff, 0xffff, 0xffff, 0xffff,
	0xffff, 0xffff, 0xffff, 0xffff, 0xffff, 0xffff, 0xffff, 0xffff, 0xffff, 0xffff, 0xffff, 0xffff, 0xffff, 0xffff, 0xffff, 0x10c3,
	0x10c3, 0x10c3, 0x10c3, 0x8c51, 0xffff, 0xffff, 0xffff, 0xffff, 0x45cf, 0x0d09, 0x0d0a, 0x0d0a, 0x0d0a, 0xc759, 0xffff, 0xffff,
	0xffff, 0xffff, 0xffff, 0xffff, 0xffff, 0xffff, 0xffff, 0xffff, 0xffff, 0xffff, 0xffff, 0x10a3, 0xffff, 0xffff, 0xffff, 0xffff,
	0xffff, 0xffff, 0xffff, 0x10c3, 0xffff, 0xffff, 0xffff, 0xffff, 0xffff, 0xffff, 0xffff, 0xc638, 0x10c3, 0x10c3, 0x10c3, 0x10a3,
	0xffff, 0xffff, 0xffff, 0xffff, 0xffff, 0xffff, 0x10c3, 0x10c3, 0x10a3, 0xffff, 0xffff, 0xffff, 0xffff, 0xffff, 0xffff, 0xffff,
	0xffff, 0xffff, 0xffff, 0xffff, 0xffff, 0xffff, 0xffff, 0xffff, 0xffff, 0xffff, 0xffff, 0xffff, 0xffff, 0xffff, 0xffff, 0xffff,
	0xffff, 0xffff, 0xffff, 0x0d0a, 0x0d0a, 0x0d0a, 0x0d2a, 0x0d0a, 0xffff, 0xffff, 0xffff, 0xffff, 0xef9e, 0x10c3, 0x10c3, 0x10c3,
	0x10a3, 0xffff, 0xffff, 0xffff, 0xffff, 0xffff, 0xffff, 0xffff, 0xffff, 0xffff, 0xffff, 0xffff, 0xffff, 0xffff, 0xffff, 0xffff,
	0xffff, 0xffff, 0xffff, 0xffff, 0xffff, 0xffff, 0xffff, 0xffff, 0xffff, 0xffff, 0xffff, 0xffff, 0xffff, 0xffff, 0xffff, 0xffff,
	0xffff, 0xffff, 0xffff, 0xffff, 0xffff, 0xffff, 0xffff, 0xffff, 0xffff, 0xffff, 0xffff, 0xffff, 0xffff, 0xffff, 0xffff, 0xffff,
	0xffff, 0xffff, 0xffff, 0xffff, 0xffff, 0xffff, 0xffff, 0xffff, 0xffff, 0xffff, 0xffff, 0xffff, 0xffff, 0xffff, 0xffff, 0xffff,
	0xe71c, 0x10c3, 0x10c3, 0x10c3, 0x10c3, 0xffff, 0xffff, 0xffff, 0xffff, 0xffff, 0x8694, 0x0d0a, 0x0d0a, 0x0d0a, 0x050a, 0x0d0a,
	0xffff, 0xffff, 0xffff, 0xffff, 0xffff, 0xffff, 0xffff, 0xffff, 0xffff, 0xffff, 0xffff, 0x10c3, 0x10c3, 0xffff, 0x10c3, 0x10a2,
	0xffff, 0xffff, 0xffff, 0xffff, 0xffff, 0xffff, 0xffff, 0xffff, 0xffff, 0xffff, 0xffff, 0xffff, 0x10a3, 0x10a3, 0x4a6a, 0xffff,
	0xffff, 0xffff, 0xffff, 0xffff, 0xffff, 0xffff, 0xffff, 0xffff, 0xffff, 0xffff, 0xffff, 0xffff, 0xffff, 0xffff, 0xffff, 0xffff,
	0x10a3, 0x10a3, 0x10a3, 0xffff, 0xffff, 0xffff, 0xffff, 0xffff, 0xffff, 0xffff, 0xffff, 0xffff, 0xffff, 0xffff, 0xffff, 0xffff,
	0x0d2a, 0x0d09, 0x0d0a, 0x0d0a, 0x0d0a, 0x256c, 0xffff, 0xffff, 0xffff, 0xffff, 0xffff, 0x10a3, 0x10c3, 0x10c3, 0x10c3, 0x5aeb,
	0xffff, 0xffff, 0xffff, 0xffff, 0xffff, 0xffff, 0xffff, 0xffff, 0xffff, 0xffff, 0xffff, 0xffff, 0xffff, 0xffff, 0xffff, 0xffff,
	0xffff, 0xffff, 0xffff, 0xffff, 0xffff, 0xffff, 0xffff, 0xffff, 0xffff, 0xffff, 0xffff, 0xffff, 0xffff, 0xffff, 0xffff, 0xffff,
	0xffff, 0xffff, 0xffff, 0xffff, 0xffff, 0xffff, 0xffff, 0xffff, 0xffff, 0xffff, 0xffff, 0xffff, 0xffff, 0xffff, 0xffff, 0xffff,
	0xffff, 0xffff, 0xffff, 0xffff, 0xffff, 0xffff, 0xffff, 0xffff, 0xffff, 0xffff, 0xffff, 0xffff, 0xffff, 0xffff, 0xffff, 0xffff,
	0xffff, 0xffff, 0x10a2, 0x10a2, 0x10c3, 0x10c3, 0x10c3, 0xffff, 0xffff, 0xffff, 0xffff, 0xffff, 0xffff, 0x0d09, 0x0d0a, 0x0d0a,
	0x0d0a, 0x0d0a, 0xa6f7, 0xffff, 0xffff, 0xffff, 0xffff, 0xffff, 0xffff, 0xffff, 0xffff, 0xffff, 0xffff, 0xffff, 0x10c3, 0x10a2,
	0xffff, 0xffff, 0xffff, 0xffff, 0xffff, 0xffff, 0xffff, 0xffff, 0xffff, 0xffff, 0xffff, 0xffff, 0xffff, 0xffff, 0xffff, 0xffff,
	0xffff, 0xffff, 0xffff, 0xffff, 0xffff, 0xffff, 0xffff, 0xffff, 0xffff, 0xffff, 0xffff, 0xffff, 0xffff, 0xffff, 0xffff, 0xffff,
	0x10a2, 0x10c3, 0x10a3, 0xffff, 0xffff, 0xffff, 0xffff, 0xffff, 0xffff, 0xffff, 0xffff, 0xffff, 0xffff, 0xefde, 0x0d0a, 0x0d0a,
	0x0d0a, 0x0d0a, 0x0d0a, 0xffff, 0xffff, 0xffff, 0xffff, 0xffff, 0xffff, 0x10c3, 0x10c3, 0x10c3, 0x10c3, 0x10a2, 0xffff, 0xffff,
	0xffff, 0xffff, 0xffff, 0xffff, 0xffff, 0xffff, 0xffff, 0xffff, 0xffff, 0xffff, 0xffff, 0xffff, 0xffff, 0xffff, 0xffff, 0xffff,
	0xffff, 0xffff, 0xffff, 0xffff, 0xffff, 0xffff, 0xffff, 0xffff, 0xffff, 0xffff, 0xffff, 0xffff, 0xffff, 0xffff, 0xffff, 0xffff,
	0xffff, 0xffff, 0xffff, 0xffff, 0xffff, 0xffff, 0xffff, 0xffff, 0xffff, 0xffff, 0xffff, 0xffff, 0xffff, 0xffff, 0xffff, 0xffff,
	0xffff, 0xffff, 0xffff, 0xffff, 0xffff, 0xffff, 0xffff, 0xffff, 0xffff, 0xffff, 0xffff, 0xffff, 0xffff, 0xffff, 0xffff, 0xffff,
	0xffff, 0xffff, 0xffff, 0xffff, 0x10c3, 0x10a2, 0x10c3, 0x10c3, 0x10c3, 0xffff, 0xffff, 0xffff, 0xffff, 0xffff, 0xffff, 0x0d09,
	0x0d09, 0x0d0a, 0x0d0a, 0x0d0a, 0x0d0a, 0xc75a, 0xffff, 0xffff, 0xffff, 0xffff, 0xffff, 0xffff, 0xffff, 0xffff, 0xffff, 0xffff,
	0xffff, 0xffff, 0xffff, 0xffff, 0xffff, 0xffff, 0xffff, 0xffff, 0xffff, 0xffff, 0xffff, 0xffff, 0xffff, 0xffff, 0xffff, 0xffff,
	0xffff, 0xffff, 0xffff, 0xffff, 0xffff, 0xffff, 0xffff, 0xffff, 0xffff, 0xffff, 0xffff, 0xffff, 0xffff, 0xffff, 0xffff, 0xffff,
	0xffff, 0xffff, 0xffff, 0xffff, 0xffff, 0xffff, 0xffff, 0xffff, 0xffff, 0xffff, 0xffff, 0x0d0a, 0x0d0a, 0x0d0a, 0x0d0a, 0x0d2a,
	0x0d0a, 0xffff, 0xffff, 0xffff, 0xffff, 0xffff, 0xffff, 0x10c3, 0x10c3, 0x10c3, 0x10a2, 0x10a3, 0xffff, 0xffff, 0xffff, 0xffff,
	0xffff, 0xffff, 0xffff, 0xffff, 0xffff, 0xffff, 0xffff, 0xffff, 0xffff, 0xffff, 0xffff, 0xffff, 0xffff, 0xffff, 0xffff, 0xffff,
	0xffff, 0xffff, 0xffff, 0xffff, 0xffff, 0xffff, 0xffff, 0xffff, 0xffff, 0xffff, 0xffff, 0xffff, 0xffff, 0xffff, 0xffff, 0xffff,
	0xffff, 0xffff, 0xffff, 0xffff, 0xffff, 0xffff, 0xffff, 0xffff, 0xffff, 0xffff, 0xffff, 0xffff, 0xffff, 0xffff, 0xffff, 0xffff,
	0xffff, 0xffff, 0xffff, 0xffff, 0xffff, 0xffff, 0xffff, 0xffff, 0xffff, 0xffff, 0xffff, 0xffff, 0xffff, 0xffff, 0xffff, 0xffff,
	0xffff, 0xffff, 0xffff, 0xffff, 0xffff, 0xffff, 0x10a3, 0x10c3, 0x10c3, 0x10c3, 0x10c3, 0x10a3, 0xffff, 0xffff, 0xffff, 0xffff,
	0xffff, 0xffff, 0x0509, 0x0d0a, 0x0d0a, 0x0d0a, 0x0d0a, 0x0d0a, 0x0d0a, 0xffff, 0xffff, 0xffff, 0xffff, 0xffff, 0xffff, 0xffff,
	0xffff, 0xffff, 0xffff, 0xffff, 0xffff, 0xffff, 0xffff, 0xffff, 0xffff, 0xffff, 0xffff, 0xffff, 0xffff, 0xffff, 0xffff, 0xffff,
	0xffff, 0xffff, 0xffff, 0xffff, 0xffff, 0xffff, 0xffff, 0xffff, 0xffff, 0xffff, 0xffff, 0xffff, 0xffff, 0xffff, 0xffff, 0xffff,
	0xffff, 0xffff, 0xffff, 0xffff, 0xffff, 0xffff, 0xffff, 0x0d0a, 0x0d09, 0x0d0a, 0x0d0a, 0x0d0a, 0x0d0a, 0x0d0a, 0xffff, 0xffff,
	0xffff, 0xffff, 0xffff, 0xffff, 0x6b6d, 0x10a2, 0x10c3, 0x10c3, 0x10c3, 0x10c3, 0xffff, 0xffff, 0xffff, 0xffff, 0xffff, 0xffff,
	0xffff, 0xffff, 0xffff, 0xffff, 0xffff, 0xffff, 0xffff, 0xffff, 0xffff, 0xffff, 0xffff, 0xffff, 0xffff, 0xffff, 0xffff, 0xffff,
	0xffff, 0xffff, 0xffff, 0xffff, 0xffff, 0xffff, 0xffff, 0xffff, 0xffff, 0xffff, 0xffff, 0xffff, 0xffff, 0xffff, 0xffff, 0xffff,
	0xffff, 0xffff, 0xffff, 0xffff, 0xffff, 0xffff, 0xffff, 0xffff, 0xffff, 0xffff, 0xffff, 0xffff, 0xffff, 0xffff, 0xffff, 0xffff,
	0xffff, 0xffff, 0xffff, 0xffff, 0xffff, 0xffff, 0xffff, 0xffff, 0xffff, 0xffff, 0xffff, 0xffff, 0xffff, 0xffff, 0xffff, 0xffff,
	0xffff, 0xffff, 0xffff, 0xffff, 0xffff, 0xffff, 0xffff, 0xffff, 0x10a2, 0x10a2, 0x10c3, 0x10c3, 0x10c3, 0x10a2, 0xffff, 0xffff,
	0xffff, 0xffff, 0xffff, 0xffff, 0xffff, 0x052a, 0x0d0a, 0x0d0a, 0x0d0a, 0x0d0a, 0x0d0a, 0x0d0a, 0x0d0a, 0xffff, 0xffff, 0xffff,
	0xffff, 0xffff, 0xffff, 0xffff, 0xffff, 0xffff, 0xffff, 0xffff, 0xffff, 0xffff, 0xffff, 0xffff, 0xffff, 0xffff, 0xffff, 0xffff,
	0xffff, 0xffff, 0xffff, 0xffff, 0xffff, 0xffff, 0xffff, 0xffff, 0xffff, 0xffff, 0xffff, 0xffff, 0xffff, 0xffff, 0xffff, 0xffff,
	0xffff, 0xffff, 0xffff, 0x0d2a, 0x0d0a, 0x0d0a, 0x0d0a, 0x0d0a, 0x0d0a, 0x0d2a, 0x0509, 0xffff, 0xffff, 0xffff, 0xffff, 0xffff,
	0xffff, 0xffff, 0x10c3, 0x10c3, 0x10c3, 0x10c3, 0x10c3, 0x10a2, 0xffff, 0xffff, 0xffff, 0xffff, 0xffff, 0xffff, 0xffff, 0xffff,
	0xffff, 0xffff, 0xffff, 0xffff, 0xffff, 0xffff, 0xffff, 0xffff, 0xffff, 0xffff, 0xffff, 0xffff, 0xffff, 0xffff, 0xffff, 0xffff,
	0xffff, 0xffff, 0xffff, 0xffff, 0xffff, 0xffff, 0xffff, 0xffff, 0xffff, 0xffff, 0xffff, 0xffff, 0xffff, 0xffff, 0xffff, 0xffff,
	0xffff, 0xffff, 0xffff, 0xffff, 0xffff, 0xffff, 0xffff, 0xffff, 0xffff, 0xffff, 0xffff, 0xffff, 0xffff, 0xffff, 0xffff, 0xffff,
	0xffff, 0xffff, 0xffff, 0xffff, 0xffff, 0xffff, 0xffff, 0xffff, 0xffff, 0xffff, 0xffff, 0xffff, 0xffff, 0xffff, 0xffff, 0xffff,
	0xffff, 0xffff, 0xffff, 0xffff, 0xffff, 0xffff, 0xffff, 0xffff, 0xffff, 0xffff, 0x4a8a, 0x10c3, 0x10c3, 0x10c3, 0x10c3, 0x10a3,
	0x10a3, 0xffff, 0xffff, 0xffff, 0xffff, 0xffff, 0xffff, 0xffff, 0x0d0a, 0x0d0a, 0x0d0a, 0x0d0a, 0x0d0a, 0x0d0a, 0x0d0a, 0x050a,
	0x0d0a, 0x0509, 0xbf5a, 0xffff, 0xffff, 0xffff, 0xffff, 0xffff, 0xffff, 0xffff, 0xffff, 0xffff, 0xffff, 0xffff, 0xffff, 0xffff,
	0xffff, 0xffff, 0xffff, 0xffff, 0xffff, 0xffff, 0xffff, 0xffff, 0xffff, 0xffff, 0xffff, 0xffff, 0xffff, 0xdf9d, 0x050a, 0x0d0a,
	0x0509, 0x0d0a, 0x0d0a, 0x0d0a, 0x0d0a, 0x0d0a, 0x0d0a, 0x052a, 0xffff, 0xffff, 0xffff, 0xffff, 0xffff, 0xffff, 0xffff, 0x10a3,
	0x10a3, 0x10c3, 0x10c3, 0x10c3, 0x10c3, 0x10c3, 0xffff, 0xffff, 0xffff, 0xffff, 0xffff, 0xffff, 0xffff, 0xffff, 0xffff, 0xffff,
	0xffff, 0xffff, 0xffff, 0xffff, 0xffff, 0xffff, 0xffff, 0xffff, 0xffff, 0xffff, 0xffff, 0xffff, 0xffff, 0xffff, 0xffff, 0xffff,
	0xffff, 0xffff, 0xffff, 0xffff, 0xffff, 0xffff, 0xffff, 0xffff, 0xffff, 0xffff, 0xffff, 0xffff, 0xffff, 0xffff, 0xffff, 0xffff,
	0xffff, 0xffff, 0xffff, 0xffff, 0xffff, 0xffff, 0xffff, 0xffff, 0xffff, 0xffff, 0xffff, 0xffff, 0xffff, 0xffff, 0xffff, 0xffff,
	0xffff, 0xffff, 0xffff, 0xffff, 0xffff, 0xffff, 0xffff, 0xffff, 0xffff, 0xffff, 0xffff, 0xffff, 0xffff, 0xffff, 0xffff, 0xffff,
	0xffff, 0xffff, 0xffff, 0xffff, 0xffff, 0xffff, 0xffff, 0xffff, 0xffff, 0xffff, 0xffff, 0xffff, 0xffff, 0x10c3, 0x10c3, 0x10c3,
	0x10c3, 0x10c3, 0x10a2, 0x10a2, 0xffff, 0xffff, 0xffff, 0xffff, 0xffff, 0xffff, 0xffff, 0xffff, 0xa6d7, 0x0d09, 0x0d0a, 0x0d0a,
	0x0d0a, 0x0d0a, 0x0d0a, 0x0d0a, 0x0d0a, 0x0d0a, 0x0d0a, 0x0d0a, 0x0d09, 0x0d2a, 0x0d0a, 0x0509, 0x0d2a, 0x8694, 0xc75a, 0xc75a,
	0xc75a, 0xc75a, 0x8694, 0x0d09, 0x0d09, 0x0d0a, 0x0d2a, 0x0d0a, 0x0d0a, 0x0d0a, 0x0d0a, 0x0d0a, 0x0d0a, 0x0d0a, 0x0d0a, 0x0d0a,
	0x0d0a, 0x0d0a, 0x0d2a, 0x6632, 0xffff, 0xffff, 0xffff, 0xffff, 0xffff, 0xffff, 0xffff, 0xffff, 0x10a2, 0x10a2, 0x10c3, 0x10c3,
	0x10c3, 0x10c3, 0x10c3, 0xffff, 0xffff, 0xffff, 0xffff, 0xffff, 0xffff, 0xffff, 0xffff, 0xffff, 0xffff, 0xffff, 0xffff, 0xffff,
	0xffff, 0xffff, 0xffff, 0xffff, 0xffff, 0xffff, 0xffff, 0xffff, 0xffff, 0xffff, 0xffff, 0xffff, 0xffff, 0xffff, 0xffff, 0xffff,
	0xffff, 0xffff, 0xffff, 0xffff, 0xffff, 0xffff, 0xffff, 0xffff, 0xffff, 0xffff, 0xffff, 0xffff, 0xffff, 0xffff, 0xffff, 0xffff,
	0xffff, 0xffff, 0xffff, 0xffff, 0xffff, 0xffff, 0xffff, 0xffff, 0xffff, 0xffff, 0xffff, 0xffff, 0xffff, 0xffff, 0xffff, 0xffff,
	0xffff, 0xffff, 0xffff, 0xffff, 0xffff, 0xffff, 0xffff, 0xffff, 0xffff, 0xffff, 0xffff, 0xffff, 0xffff, 0xffff, 0xffff, 0xffff,
	0xffff, 0xffff, 0xffff, 0xffff, 0xffff, 0xffff, 0xffff, 0xffff, 0xffff, 0xffff, 0xffff, 0xffff, 0xffff, 0xffff, 0xffff, 0x10a3,
	0x10a2, 0x10c3, 0x10c3, 0x10c3, 0x10c3, 0x10c3, 0x10a3, 0xffff, 0xffff, 0xffff, 0xffff, 0xffff, 0xffff, 0xffff, 0xffff, 0xffff,
	0xffff, 0x8694, 0x0d2a, 0x0d0a, 0x0d0a, 0x052a, 0x0d0a, 0x0d0a, 0x0d0a, 0x0d0a, 0x0d0a, 0x0d0a, 0x0d0a, 0x0d0a, 0x0d0a, 0x0d0a,
	0x0d0a, 0x0d0a, 0x0d0a, 0x0d0a, 0x0d0a, 0x0d0a, 0x0d0a, 0x0d0a, 0x0d0a, 0x0d0a, 0x0d0a, 0x0d0a, 0x0d0a, 0x050a, 0x4dcf, 0xffff,
	0xffff, 0xffff, 0xffff, 0xffff, 0xffff, 0xffff, 0xffff, 0xffff, 0xffff, 0x10c3, 0x10c3, 0x10c3, 0x10c3, 0x10c3, 0x10c3, 0x10a3,
	0x10a3, 0xffff, 0xffff, 0xffff, 0xffff, 0xffff, 0xffff, 0xffff, 0xffff, 0xffff, 0xffff, 0xffff, 0xffff, 0xffff, 0xffff, 0xffff,
	0xffff, 0xffff, 0xffff, 0xffff, 0xffff, 0xffff, 0xffff, 0xffff, 0xffff, 0xffff, 0xffff, 0xffff, 0xffff, 0xffff, 0xffff, 0xffff,
	0xffff, 0xffff, 0xffff, 0xffff, 0xffff, 0xffff, 0xffff, 0xffff, 0xffff, 0xffff, 0xffff, 0xffff, 0xffff, 0xffff, 0xffff, 0xffff,
	0xffff, 0xffff, 0xffff, 0xffff, 0xffff, 0xffff, 0xffff, 0xffff, 0xffff, 0xffff, 0xffff, 0xffff, 0xffff, 0xffff, 0xffff, 0xffff,
	0xffff, 0xffff, 0xffff, 0xffff, 0xffff, 0xffff, 0xffff, 0xffff, 0xffff, 0xffff, 0xffff, 0xffff, 0xffff, 0xffff, 0xffff, 0xffff,
	0xffff, 0xffff, 0xffff, 0xffff, 0xffff, 0xffff, 0xffff, 0xffff, 0xffff, 0xffff, 0xffff, 0xffff, 0xffff, 0xffff, 0xffff, 0xffff,
	0xffff, 0xffff, 0x10a2, 0x10c3, 0x10c3, 0x10c3, 0x10c3, 0x10c3, 0x10c3, 0x10a2, 0x10c3, 0xffff, 0xffff, 0xffff, 0xffff, 0xffff,
	0xffff, 0xffff, 0xffff, 0xffff, 0xffff, 0xffff, 0xffff, 0xffff, 0xffff, 0xffff, 0xffff, 0x4dcf, 0x0d09, 0x0d0a, 0x0d0a, 0x0d0a,
	0x0d0a, 0x0d0a, 0x0d2a, 0x050a, 0x4dcf, 0xefde, 0xffff, 0xffff, 0xffff, 0xffff, 0xffff, 0xffff, 0xffff, 0xffff, 0xffff, 0xffff,
	0xffff, 0xffff, 0xffff, 0xffff, 0xffff, 0x10c3, 0x10a3, 0x10c3, 0x10c3, 0x10c3, 0x10c3, 0x10c3, 0x10c3, 0x10a3, 0xffff, 0xffff,
	0xffff, 0xffff, 0xffff, 0xffff, 0xffff, 0xffff, 0xffff, 0xffff, 0xffff, 0xffff, 0xffff, 0xffff, 0xffff, 0xffff, 0xffff, 0xffff,
	0xffff, 0xffff, 0xffff, 0xffff, 0xffff, 0xffff, 0xffff, 0xffff, 0xffff, 0xffff, 0xffff, 0xffff, 0xffff, 0xffff, 0xffff, 0xffff,
	0xffff, 0xffff, 0xffff, 0xffff, 0xffff, 0xffff, 0xffff, 0xffff, 0xffff, 0xffff, 0xffff, 0xffff, 0xffff, 0xffff, 0xffff, 0xffff,
	0xffff, 0xffff, 0xffff, 0xffff, 0xffff, 0xffff, 0xffff, 0xffff, 0xffff, 0xffff, 0xffff, 0xffff, 0xffff, 0xffff, 0xffff, 0xffff,
	0xffff, 0xffff, 0xffff, 0xffff, 0xffff, 0xffff, 0xffff, 0xffff, 0xffff, 0xffff, 0xffff, 0xffff, 0xffff, 0xffff, 0xffff, 0xffff,
	0xffff, 0xffff, 0xffff, 0xffff, 0xffff, 0xffff, 0xffff, 0xffff, 0xffff, 0xffff, 0xffff, 0xffff, 0xffff, 0xffff, 0xffff, 0xffff,
	0xffff, 0xffff, 0xffff, 0xffff, 0xffff, 0xffff, 0x10c3, 0x10a2, 0x10c3, 0x10c3, 0x10c3, 0x10c3, 0x10c3, 0x10c3, 0x10c3, 0x10c3,
	0xffff, 0xffff, 0xffff, 0xffff, 0xffff, 0xffff, 0xffff, 0xffff, 0xffff, 0xffff, 0xffff, 0xffff, 0xffff, 0xffff, 0xffff, 0xffff,
	0xffff, 0xffff, 0xffff, 0xffff, 0xffff, 0xffff, 0xffff, 0xffff, 0xffff, 0xffff, 0xffff, 0xffff, 0xffff, 0xffff, 0xffff, 0xffff,
	0x10a3, 0x10a2, 0x10c3, 0x10c3, 0x10c3, 0x10c3, 0x10c3, 0x10c3, 0x10c3, 0x10a2, 0xf79e, 0xffff, 0xffff, 0xffff, 0xffff, 0xffff,
	0xffff, 0xffff, 0xffff, 0xffff, 0xffff, 0xffff, 0xffff, 0xffff, 0xffff, 0xffff, 0xffff, 0xffff, 0xffff, 0xffff, 0xffff, 0xffff,
	0xffff, 0xffff, 0xffff, 0xffff, 0xffff, 0xffff, 0xffff, 0xffff, 0xffff, 0xffff, 0xffff, 0xffff, 0xffff, 0xffff, 0xffff, 0xffff,
	0xffff, 0xffff, 0xffff, 0xffff, 0xffff, 0xffff, 0xffff, 0xffff, 0xffff, 0xffff, 0xffff, 0xffff, 0xffff, 0xffff, 0xffff, 0xffff,
	0xffff, 0xffff, 0xffff, 0xffff, 0xffff, 0xffff, 0xffff, 0xffff, 0xffff, 0xffff, 0xffff, 0xffff, 0xffff, 0xffff, 0xffff, 0xffff,
	0xffff, 0xffff, 0xffff, 0xffff, 0xffff, 0xffff, 0xffff, 0xffff, 0xffff, 0xffff, 0xffff, 0xffff, 0xffff, 0xffff, 0xffff, 0xffff,
	0xffff, 0xffff, 0xffff, 0xffff, 0xffff, 0xffff, 0xffff, 0xffff, 0xffff, 0xffff, 0xffff, 0xffff, 0xffff, 0xffff, 0xffff, 0xffff,
	0xffff, 0xffff, 0xffff, 0xffff, 0xffff, 0xffff, 0xffff, 0xffff, 0xffff, 0xffff, 0x10c3, 0x10c3, 0x10c3, 0x10c3, 0x10c3, 0x10c3,
	0x10c3, 0x10c3, 0x10c3, 0x10c3, 0x10c3, 0x10c3, 0x10a2, 0x10a3, 0xffff, 0xffff, 0xffff, 0xffff, 0xffff, 0xffff, 0xffff, 0xffff,
	0xffff, 0xffff, 0xffff, 0xffff, 0xffff, 0xffff, 0xffff, 0xffff, 0x2986, 0x10a3, 0x10a2, 0x10a2, 0x10a3, 0x10a2, 0x10c3, 0x10c3,
	0x10c3, 0x10c3, 0x10c3, 0x10c3, 0x10c3, 0x10c3, 0xe71c, 0xffff, 0xffff, 0xffff, 0xffff, 0xffff, 0xffff, 0xffff, 0xffff, 0xffff,
	0xffff, 0xffff, 0xffff, 0xffff, 0xffff, 0xffff, 0xffff, 0xffff, 0xffff, 0xffff, 0xffff, 0xffff, 0xffff, 0xffff, 0xffff, 0xffff,
	0xffff, 0xffff, 0xffff, 0xffff, 0xffff, 0xffff, 0xffff, 0xffff, 0xffff, 0xffff, 0xffff, 0xffff, 0xffff, 0xffff, 0xffff, 0xffff,
	0xffff, 0xffff, 0xffff, 0xffff, 0xffff, 0xffff, 0xffff, 0xffff, 0xffff, 0xffff, 0xffff, 0xffff, 0xffff, 0xffff, 0xffff, 0xffff,
	0xffff, 0xffff, 0xffff, 0xffff, 0xffff, 0xffff, 0xffff, 0xffff, 0xffff, 0xffff, 0xffff, 0xffff, 0xffff, 0xffff, 0xffff, 0xffff,
	0xffff, 0xffff, 0xffff, 0xffff, 0xffff, 0xffff, 0xffff, 0xffff, 0xffff, 0xffff, 0xffff, 0xffff, 0xffff, 0xffff, 0xffff, 0xffff,
	0xffff, 0xffff, 0xffff, 0xffff, 0xffff, 0xffff, 0xffff, 0xffff, 0xffff, 0xffff, 0xffff, 0xffff, 0xffff, 0xffff, 0xffff, 0xffff,
	0xffff, 0xffff, 0xffff, 0xffff, 0xffff, 0xffff, 0xffff, 0xffff, 0xffff, 0xffff, 0xffff, 0xffff, 0xffff, 0xffff, 0xb5b6, 0x10a3,
	0x10c3, 0x10c3, 0x10c3, 0x10c3, 0x10c3, 0x10c3, 0x10c3, 0x10c3, 0x10c3, 0x10c3, 0x10c3, 0x10c3, 0x10c3, 0x10c3, 0x10c3, 0x10c3,
	0x10c3, 0x10c3, 0x10c3, 0x10c3, 0x10c3, 0x10c3, 0x10c3, 0x10c3, 0x10c3, 0x10c3, 0x10c3, 0x10c3, 0x10c3, 0x10c3, 0x10c3, 0x10a2,
	0x10a3, 0x8451, 0xffff, 0xffff, 0xffff, 0xffff, 0xffff, 0xffff, 0xffff, 0xffff, 0xffff, 0xffff, 0xffff, 0xffff, 0xffff, 0xffff,
	0xffff, 0xffff, 0xffff, 0xffff, 0xffff, 0xffff, 0xffff, 0xffff, 0xffff, 0xffff, 0xffff, 0xffff, 0xffff, 0xffff, 0xffff, 0xffff,
	0xffff, 0xffff, 0xffff, 0xffff, 0xffff, 0xffff, 0xffff, 0xffff, 0xffff, 0xffff, 0xffff, 0xffff, 0xffff, 0xffff, 0xffff, 0xffff,
	0xffff, 0xffff, 0xffff, 0xffff, 0xffff, 0xffff, 0xffff, 0xffff, 0xffff, 0xffff, 0xffff, 0xffff, 0xffff, 0xffff, 0xffff, 0xffff,
	0xffff, 0xffff, 0xffff, 0xffff, 0xffff, 0xffff, 0xffff, 0xffff, 0xffff, 0xffff, 0xffff, 0xffff, 0xffff, 0xffff, 0xffff, 0xffff,
	0xffff, 0xffff, 0xffff, 0xffff, 0xffff, 0xffff, 0xffff, 0xffff, 0xffff, 0xffff, 0xffff, 0xffff, 0xffff, 0xffff, 0xffff, 0xffff,
	0xffff, 0xffff, 0xffff, 0xffff, 0xffff, 0xffff, 0xffff, 0xffff, 0xffff, 0xffff, 0xffff, 0xffff, 0xffff, 0xffff, 0xffff, 0xffff,
	0xffff, 0xffff, 0xffff, 0xffff, 0xffff, 0xffff, 0xffff, 0xffff, 0xffff, 0xffff, 0xffff, 0xffff, 0xffff, 0xffff, 0xffff, 0xffff,
	0xffff, 0xffff, 0xffff, 0xffff, 0xffff, 0xffff, 0x10a3, 0x10a3, 0x10a2, 0x10c3, 0x10c3, 0x10c3, 0x10a3, 0x10c3, 0x10c3, 0x10c3,
	0x10c3, 0x10c3, 0x10c3, 0x10a2, 0x10a3, 0x10a2, 0x10a3, 0x10a3, 0x10c3, 0x10a2, 0xd69a, 0xffff, 0xffff, 0xffff, 0xffff, 0xffff,
	0xffff, 0xffff, 0xffff, 0xffff, 0xffff, 0xffff, 0xffff, 0xffff, 0xffff, 0xffff, 0xffff, 0xffff, 0xffff, 0xffff, 0xffff, 0xffff,
	0xffff, 0xffff, 0xffff, 0xffff, 0xffff, 0xffff, 0xffff, 0xffff, 0xffff, 0xffff, 0xffff, 0xffff, 0xffff, 0xffff, 0xffff, 0xffff,
	0xffff, 0xffff, 0xffff, 0xffff, 0xffff, 0xffff, 0xffff, 0xffff, 0xffff, 0xffff, 0xffff, 0xffff, 0xffff, 0xffff, 0xffff, 0xffff,
	0xffff, 0xffff, 0xffff, 0xffff, 0xffff, 0xffff, 0xffff, 0xffff, 0xffff, 0xffff, 0xffff, 0xffff, 0xffff, 0xffff, 0xffff, 0xffff

};

//volatile float temperature=0;
volatile  uint16_t  redtemp=0;
uint16_t	  MSBLSB;
uint8_t	  status;
//uint16_t volatile MSBLSB;
//volatile uint8_t MSB;
//volatile uint8_t LSB;
//volatile uint8_t M;
//volatile uint8_t L;

/* USER CODE END PV */

void SystemClock_Config(void);
static void MX_DMA_Init(void);
static void MX_GPIO_Init(void);
static void MX_SPI1_Init(void);
static void MX_SPI2_Init(void);

/* USER CODE BEGIN 0 */

uint32_t adc_oku(){
	uint32_t deger;
  ADC1->CR2 |=0x40000000;
	while(!(ADC1->SR & 0X00000002));
	deger = ADC1->DR;
	return deger;
}

uint16_t readDada(void){
						uint8_t data8[2];
						MAX6675_CS0
						HAL_SPI_Receive(&hspi1,data8,1,1000);
//	uint8_t   LSB = data8[0];
//	uint8_t  	MSB = data8[1];
//	uint16_t	MSBLSB = MSB << 8 | LSB;
            if(data8[0] & 1<<2)	status=1;
	          else status=0;
	          MSBLSB = data8[1] << 8 | data8[0];
		        MSBLSB=(0X0FFF &(MSBLSB>>3));
						MAX6675_CS1
	return    (uint16_t)(MSBLSB/4);

}

void spi2_8b_init(void){//переходит в 8 бит SPI
 hspi2.Init.DataSize = SPI_DATASIZE_8BIT;
 HAL_SPI_Init(&hspi2);

}
void spi2_16b_init(void){//переходит в 16 бит SPI
 hspi2.Init.DataSize = SPI_DATASIZE_16BIT;
 HAL_SPI_Init(&hspi2);
}

void lcd7735_senddata(unsigned char data) {//передаем в режиме 8 бит
  HAL_SPI_Transmit(&hspi2, &data,1,0x1);
	//HAL_SPI_Transmit_DMA(&hspi2, &data,1);
}
void lcd7735_send16bData(uint8_t msb,uint8_t lsb) {//передаем в режиме 16 бит
	uint8_t masData[2]={lsb,msb};
	HAL_SPI_Transmit(&hspi2,masData,1,0x1);
	//HAL_SPI_Transmit_DMA(&hspi2,masData,1);
}

/* USER CODE END 0 */

int main(void)
{

  /* USER CODE BEGIN 1 */
  //uint8_t degger=0x45;
  /* USER CODE END 1 */

  /* MCU Configuration----------------------------------------------------------*/

  /* Reset of all peripherals, Initializes the Flash interface and the Systick. */
  HAL_Init();

  /* Configure the system clock */
  SystemClock_Config();

  /* Initialize all configured peripherals */
  MX_GPIO_Init();
	MX_DMA_Init();
  MX_SPI1_Init();
  MX_SPI2_Init();

  /* USER CODE BEGIN 2 */
	lcd7735_ini();

	 int j=0;
	 int i=0;
	lcd7735_fillrect(0, 0, 129, 161,0x0000);
	//lcd7735_putpix(20,30,0xffff);
//lcd7735_fillrect(20, 30, 110, 110,0x001f);

for (i=0;i<128;i++){
  for	(j=0;j<160;j++){
	pixel++;
  lcd7735_putpix(i,j,test_img_128x128[pixel]);
  }
}

HAL_Delay(1000);

lcd7735_fillrect(0, 0, 129, 161,0x0000);

  RCC->AHB1ENR    |=0x00000001;
  GPIOA->MODER    |=0x00000003;
  GPIOA->OSPEEDR  |=0x00000003;

  RCC->APB2ENR|=0x00000100;
  //ADC1->CR1   |=0x02000000;
  ADC1->CR2   |=0x00000001;
  //ADC1->SMPR2 |=0x00000003;
  //ADC->CCR    |=0X00010000;
  ADC1->CR2 |=0x40000000;
	const unsigned char yazi[11]="ADC deger= ";
	lcd7735_putstr(114,0,yazi, 0xffff, 0x0000);
  int zaman=0;

  while (1){
 	//HAL_SPI_Transmit_DMA(&hspi2,&degger,1);
 HAL_Delay(30);
 zaman++;
 uint16_t analogveri=0;
 unsigned char analog[5]="    ";
 uint16_t yuzde=0;
 float basamak;
 //analogveri= ADC1->DR;
 analogveri= adc_oku();
 int2char(analogveri,analog);
 lcd7735_putstr(114,80,analog, 0xffff, 0x0000);
 basamak=analogveri;
 yuzde=(basamak/4095)*100;
 unsigned char yuzde_deger[4]="   %";
 int2char(yuzde,yuzde_deger);
 lcd7735_putstr(114,125,yuzde_deger, 0xffff, 0x0000);
 //lcd7735_putpix(analogveri/36,zaman%160,0xffff);
lcd7735_line(0,zaman%160,analogveri/36,zaman%160,0xffff);
lcd7735_line(0,1+(zaman%160),113,1+(zaman%160),0x0000);
lcd7735_line(0,2+(zaman%160),113,2+(zaman%160),0x0000);
//HAL_SPI_Transmit_DMA(&hspi2,&degger,1);
  }
  /* USER CODE END 3 */

}

/** System Clock Configuration
*/
void SystemClock_Config(void)
{

  RCC_OscInitTypeDef RCC_OscInitStruct;
  RCC_ClkInitTypeDef RCC_ClkInitStruct;

  __PWR_CLK_ENABLE();

  __HAL_PWR_VOLTAGESCALING_CONFIG(PWR_REGULATOR_VOLTAGE_SCALE1);

  RCC_OscInitStruct.OscillatorType = RCC_OSCILLATORTYPE_HSE;
  RCC_OscInitStruct.HSEState = RCC_HSE_ON;
  RCC_OscInitStruct.PLL.PLLState = RCC_PLL_ON;
  RCC_OscInitStruct.PLL.PLLSource = RCC_PLLSOURCE_HSE;
  RCC_OscInitStruct.PLL.PLLM = 5;
  RCC_OscInitStruct.PLL.PLLN = 210;
  RCC_OscInitStruct.PLL.PLLP = RCC_PLLP_DIV2;
  RCC_OscInitStruct.PLL.PLLQ = 4;
  HAL_RCC_OscConfig(&RCC_OscInitStruct);

  RCC_ClkInitStruct.ClockType = RCC_CLOCKTYPE_SYSCLK|RCC_CLOCKTYPE_PCLK1
                              |RCC_CLOCKTYPE_PCLK2;
  RCC_ClkInitStruct.SYSCLKSource = RCC_SYSCLKSOURCE_PLLCLK;
  RCC_ClkInitStruct.AHBCLKDivider = RCC_SYSCLK_DIV1;
  RCC_ClkInitStruct.APB1CLKDivider = RCC_HCLK_DIV4;
  RCC_ClkInitStruct.APB2CLKDivider = RCC_HCLK_DIV2;
  HAL_RCC_ClockConfig(&RCC_ClkInitStruct, FLASH_LATENCY_5);

  HAL_SYSTICK_Config(HAL_RCC_GetHCLKFreq()/1000);

  HAL_SYSTICK_CLKSourceConfig(SYSTICK_CLKSOURCE_HCLK);

}

/* SPI1 init function */
void MX_DMA_Init(void)
{
  /* DMA controller clock enable */
  __HAL_RCC_DMA1_CLK_ENABLE();

  /* DMA interrupt init */
  /* DMA1_Stream3_IRQn interrupt configuration */
  HAL_NVIC_SetPriority(DMA1_Stream3_IRQn, 0, 0);
  HAL_NVIC_EnableIRQ(DMA1_Stream3_IRQn);
  /* DMA1_Stream4_IRQn interrupt configuration */
  HAL_NVIC_SetPriority(DMA1_Stream4_IRQn, 0, 0);
  HAL_NVIC_EnableIRQ(DMA1_Stream4_IRQn);
}
void MX_SPI1_Init(void)
{

  /* SPI1 parameter configuration*/
  hspi1.Instance = SPI1;
  hspi1.Init.Mode = SPI_MODE_MASTER;
  hspi1.Init.Direction = SPI_DIRECTION_2LINES;
  hspi1.Init.DataSize = SPI_DATASIZE_8BIT;
  hspi1.Init.CLKPolarity = SPI_POLARITY_LOW;
  hspi1.Init.CLKPhase = SPI_PHASE_1EDGE;
  hspi1.Init.NSS = SPI_NSS_SOFT;
  hspi1.Init.BaudRatePrescaler = SPI_BAUDRATEPRESCALER_2;
  hspi1.Init.FirstBit = SPI_FIRSTBIT_MSB;
  hspi1.Init.TIMode = SPI_TIMODE_DISABLE;
  hspi1.Init.CRCCalculation = SPI_CRCCALCULATION_DISABLE;
  hspi1.Init.CRCPolynomial = 10;
  if (HAL_SPI_Init(&hspi1) != HAL_OK)
  {
    Error_Handler();
  }

}

/* SPI2 init function */
void MX_SPI2_Init(void)
{

  /* SPI2 parameter configuration*/
  hspi2.Instance = SPI2;
  hspi2.Init.Mode = SPI_MODE_MASTER;
  hspi2.Init.Direction = SPI_DIRECTION_2LINES;
  hspi2.Init.DataSize = SPI_DATASIZE_8BIT;
  hspi2.Init.CLKPolarity = SPI_POLARITY_LOW;
  hspi2.Init.CLKPhase = SPI_PHASE_1EDGE;
  hspi2.Init.NSS = SPI_NSS_SOFT;
  hspi2.Init.BaudRatePrescaler = SPI_BAUDRATEPRESCALER_2;
  hspi2.Init.FirstBit = SPI_FIRSTBIT_MSB;
  hspi2.Init.TIMode = SPI_TIMODE_DISABLE;
  hspi2.Init.CRCCalculation = SPI_CRCCALCULATION_DISABLE;
  hspi2.Init.CRCPolynomial = 10;
  if (HAL_SPI_Init(&hspi2) != HAL_OK)
  {
    Error_Handler();
  }

}

/** Configure pins as
        * Analog
        * Input
        * Output
        * EVENT_OUT
        * EXTI
*/
void MX_GPIO_Init(void)
{

  GPIO_InitTypeDef GPIO_InitStruct;

  /* GPIO Ports Clock Enable */
  __GPIOH_CLK_ENABLE();
  __GPIOA_CLK_ENABLE();
  __GPIOB_CLK_ENABLE();

  /*Configure GPIO pin : PA4 */
  GPIO_InitStruct.Pin = GPIO_PIN_4;
  GPIO_InitStruct.Mode = GPIO_MODE_OUTPUT_PP;
  GPIO_InitStruct.Pull = GPIO_NOPULL;
  GPIO_InitStruct.Speed = GPIO_SPEED_LOW;
  HAL_GPIO_Init(GPIOA, &GPIO_InitStruct);

  /*Configure GPIO pins : PB10 PB12 PB14 */
  GPIO_InitStruct.Pin = GPIO_PIN_10|GPIO_PIN_12|GPIO_PIN_14;
  GPIO_InitStruct.Mode = GPIO_MODE_OUTPUT_PP;
  GPIO_InitStruct.Pull = GPIO_NOPULL;
  GPIO_InitStruct.Speed = GPIO_SPEED_LOW;
  HAL_GPIO_Init(GPIOB, &GPIO_InitStruct);

}

/************************ (C) COPYRIGHT STMicroelectronics *****END OF FILE****/
